VERSION ""

NS_ :

BS_:

BU_: VDCU_M CDCU VDR_TBOX ADCU VIU_B VIU_C VDCU_V EPB EBS FCS EPS_M EPS_S CMS_R CMS_B ECAS EGSM MTCU

BO_ 2566889511 NM_VDCU: 8 VDCU_M
 SG_ VDCU_SourceNodeID : 0|8@1+ (1,0) [0|255] "" Vector__XXX
 SG_ VDCU_ActiveWakeUpBit : 12|1@1+ (1,0) [0|1] "" Vector__XXX
 SG_ VDCU_RepeatMessageRequest : 8|1@1+ (1,0) [0|1] "" Vector__XXX
 SG_ VDCU_NMState_RMSfromBSM : 16|1@1+ (1,0) [0|1] "" Vector__XXX
 SG_ VDCU_NMState_RMSfromPBSM : 17|1@1+ (1,0) [0|1] "" Vector__XXX
 SG_ VDCU_NMState_RMSfromNOS : 18|1@1+ (1,0) [0|1] "" Vector__XXX
 SG_ VDCU_NMState_RMSfromRSS : 19|1@1+ (1,0) [0|1] "" Vector__XXX
 SG_ VDCU_NMState_NOSfromRMS : 20|1@1+ (1,0) [0|1] "" Vector__XXX
 SG_ VDCU_NMState_NOSfromRSS : 21|1@1+ (1,0) [0|1] "" Vector__XXX
 SG_ VDCU_WakeupSource : 24|8@1+ (1,0) [0|255] "" Vector__XXX
 SG_ VDCU_NMKpARson_NMPduReceived : 32|1@1+ (1,0) [0|1] "" Vector__XXX
 SG_ VDCU_NMKpARson_TimeOut : 33|1@1+ (1,0) [0|1] "" Vector__XXX
 SG_ VDCU_NMKpARson_Diag : 34|1@1+ (1,0) [0|1] "" Vector__XXX
 SG_ VDCU_NMKpARson_KL15 : 36|1@1+ (1,0) [0|1] "" Vector__XXX
 SG_ VDCU_NMKpARson_LINReq : 37|1@1+ (1,0) [0|1] "" Vector__XXX
 SG_ VDCU_NMKpARson_WinCtrl_L : 38|1@1+ (1,0) [0|1] "" Vector__XXX
 SG_ VDCU_NMKpARson_WinCtrl_R : 39|1@1+ (1,0) [0|1] "" Vector__XXX
 SG_ VDCU_NMKpARson_BrakePedalPressed : 40|1@1+ (1,0) [0|1] "" Vector__XXX
 SG_ VDCU_NMKpARson_LowBeamReq : 41|1@1+ (1,0) [0|1] "" Vector__XXX
 SG_ VDCU_NMKpARson_PosnLigjtReq : 42|1@1+ (1,0) [0|1] "" Vector__XXX
 SG_ VDCU_NMKpARson_DCChargeActive : 43|1@1+ (1,0) [0|1] "" Vector__XXX
 SG_ VDCU_NMKpARson_PowerOFFdelayMonitor : 44|1@1+ (1,0) [0|1] "" Vector__XXX
 SG_ VDCU_NMKpARson_ACChargeActive : 45|1@1+ (1,0) [0|1] "" Vector__XXX
 SG_ VDCU_NMKpARson_HVConnected : 46|1@1+ (1,0) [0|1] "" Vector__XXX
 SG_ VDCU_NMKpARson_ChargeWarmer : 47|1@1+ (1,0) [0|1] "" Vector__XXX
 SG_ VDCU_NMKpARson_Ready : 48|1@1+ (1,0) [0|1] "" Vector__XXX
 SG_ VDCU_NMKpARson_SmartCharge : 49|1@1+ (1,0) [0|1] "" Vector__XXX

BO_ 2566865177 TM_ACCtrl: 8 VDCU_M
 SG_ ACTempLevelDisp : 0|6@1+ (1,0) [0|63] "" CDCU,VDR_TBOX,ADCU
 SG_ ACPTCDisp : 6|2@1+ (1,0) [0|3] "" Vector__XXX
 SG_ ACTempLevelCtrl : 8|6@1+ (1,0) [0|63] "" VIU_B,ADCU
 SG_ ACModeMotorDisp : 16|3@1+ (1,0) [0|7] "" CDCU,VDR_TBOX,ADCU
 SG_ ACModeMotorCtrl : 19|3@1+ (1,0) [0|7] "" VIU_B,ADCU
 SG_ ACCycleMotorDisp : 22|2@1+ (1,0) [0|3] "" CDCU,VDR_TBOX,ADCU
 SG_ ACCycleMotorPosnCtrl : 24|2@1+ (1,0) [0|3] "" VIU_B,ADCU
 SG_ ACBlowerLevelDisp : 26|4@1+ (1,0) [0|15] "" CDCU,VDR_TBOX,ADCU
 SG_ ACBlowerLevelCtrl : 32|4@1+ (1,0) [0|15] "" VIU_B,ADCU
 SG_ ACFrontDefrostDisp : 36|2@1+ (1,0) [0|3] "" CDCU,VDR_TBOX,ADCU
 SG_ ACAcDisp : 38|2@1+ (1,0) [0|3] "" CDCU,VDR_TBOX,ADCU
 SG_ ACMaxDisp : 40|2@1+ (1,0) [0|3] "" CDCU,VDR_TBOX,ADCU
 SG_ ACAutoDisp : 42|2@1+ (1,0) [0|3] "" CDCU,VDR_TBOX,ADCU
 SG_ ACOffDisp : 44|2@1+ (1,0) [0|3] "" CDCU,VDR_TBOX,ADCU
 SG_ ACAirPurgeDisp : 46|2@1+ (1,0) [0|3] "" CDCU,VDR_TBOX,ADCU
 SG_ ACAirPurgeCtrl : 48|2@1+ (1,0) [0|3] "" VIU_B,ADCU
 SG_ ACLonizerDisp : 50|2@1+ (1,0) [0|3] "" CDCU,VDR_TBOX,ADCU
 SG_ ACLonizerCtrl : 52|2@1+ (1,0) [0|3] "" VIU_B,ADCU
 SG_ AC_TempZoneSyncSts : 54|2@1+ (1,0) [0|3] "" VIU_B,CDCU,VDR_TBOX,ADCU
 SG_ AC_HeatingMaxSts : 56|2@1+ (1,0) [0|3] "" VIU_B,CDCU,VDR_TBOX,ADCU
 SG_ ElecACTempLevelDisp : 58|5@1+ (1,0) [0|31] "" Vector__XXX

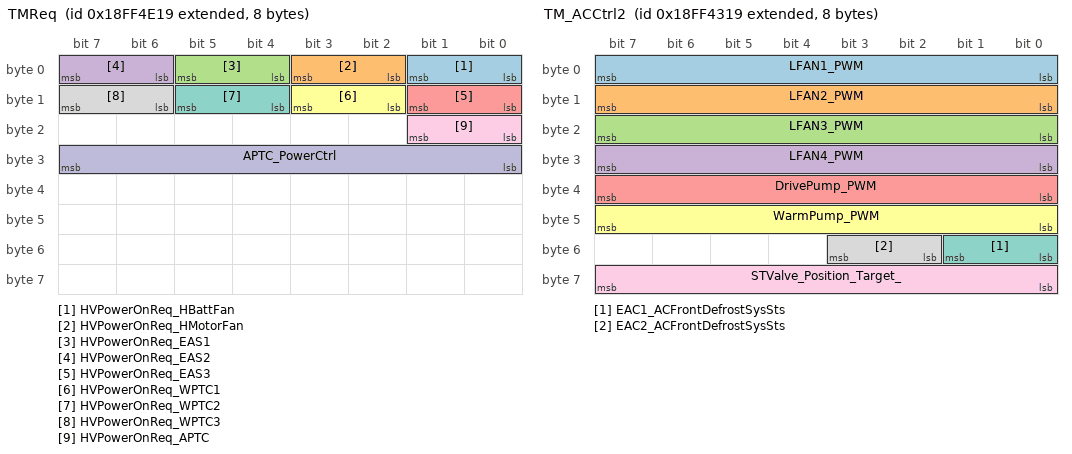
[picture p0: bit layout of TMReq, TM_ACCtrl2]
BO_ 2566868505 TMReq: 8 VDCU_M
 SG_ HVPowerOnReq_HBattFan : 0|2@1+ (1,0) [0|3] "" Vector__XXX
 SG_ HVPowerOnReq_HMotorFan : 2|2@1+ (1,0) [0|3] "" Vector__XXX
 SG_ HVPowerOnReq_EAS1 : 4|2@1+ (1,0) [0|3] "" Vector__XXX
 SG_ HVPowerOnReq_EAS2 : 6|2@1+ (1,0) [0|3] "" Vector__XXX
 SG_ HVPowerOnReq_EAS3 : 8|2@1+ (1,0) [0|3] "" Vector__XXX
 SG_ HVPowerOnReq_WPTC1 : 10|2@1+ (1,0) [0|3] "" Vector__XXX
 SG_ HVPowerOnReq_WPTC2 : 12|2@1+ (1,0) [0|3] "" Vector__XXX
 SG_ HVPowerOnReq_WPTC3 : 14|2@1+ (1,0) [0|3] "" Vector__XXX
 SG_ HVPowerOnReq_APTC : 16|2@1+ (1,0) [0|3] "" Vector__XXX
 SG_ APTC_PowerCtrl : 24|8@1+ (100,0) [0|4700] "W" VIU_B

BO_ 2566865433 TM_ACCtrl1: 8 VDCU_M
 SG_ ACTempLevelDispSlpr : 2|6@1+ (1,0) [0|63] "" CDCU
 SG_ ACTempLevelCtrl_Slpr : 10|6@1+ (1,0) [0|63] "" VIU_B
 SG_ ACBlowerLevelDisp_Slpr : 16|4@1+ (1,0) [0|15] "" CDCU
 SG_ ACBlowerLevelCtrl_Slpr : 20|4@1+ (1,0) [0|15] "" VIU_B
 SG_ ACTimingRunDisp_Slpr : 24|2@1+ (1,0) [0|3] "" CDCU
 SG_ ACOffDisp_Slpr : 26|2@1+ (1,0) [0|3] "" CDCU
 SG_ ESC_PTC_LowRelayCtrl : 28|2@1+ (1,0) [0|3] "" VIU_B
 SG_ FAN_LowRelayCtrl : 30|2@1+ (1,0) [0|3] "" VIU_C
 SG_ Blower_RelayCtrl : 32|2@1+ (1,0) [0|3] "" VIU_B
 SG_ Blower_RelayCtrl_Slpr : 34|2@1+ (1,0) [0|3] "" VIU_B
 SG_ BattPump_RelayCtrl : 36|2@1+ (1,0) [0|3] "" VIU_B
 SG_ WarmPump_RelayCtrl : 38|2@1+ (1,0) [0|3] "" VIU_B
 SG_ DrivePump_RelayCtrl : 40|2@1+ (1,0) [0|3] "" VIU_C
 SG_ SOVFront_Ctrl : 42|1@1+ (1,0) [0|1] "" VIU_B
 SG_ SOVRear_Ctrl : 43|1@1+ (1,0) [0|1] "" VIU_B
 SG_ Wasteheat_use_2way_SOV : 46|2@1+ (1,0) [0|3] "" VIU_C
 SG_ BattPump_PWM : 48|8@1+ (0.4,0) [0|100] "%" VIU_B,VIU_C
 SG_ Temp_Ambt_Accurate : 56|8@1+ (0.5,-40) [-40|87] "℃" Vector__XXX

BO_ 2566865689 TM_ACCtrl2: 8 VDCU_M
 SG_ LFAN1_PWM : 0|8@1+ (0.4,0) [0|100] "%" VIU_B,VIU_C
 SG_ LFAN2_PWM : 8|8@1+ (0.4,0) [0|100] "%" VIU_B,VIU_C
 SG_ LFAN3_PWM : 16|8@1+ (0.4,0) [0|100] "%" VIU_B,VIU_C
 SG_ LFAN4_PWM : 24|8@1+ (0.4,0) [0|100] "%" VIU_B,VIU_C
 SG_ DrivePump_PWM : 32|8@1+ (0.4,0) [0|100] "%" VIU_B,VIU_C
 SG_ WarmPump_PWM : 40|8@1+ (0.4,0) [0|100] "%" VIU_C
 SG_ EAC1_ACFrontDefrostSysSts : 48|2@1+ (1,0) [0|3] "" CDCU
 SG_ EAC2_ACFrontDefrostSysSts : 50|2@1+ (1,0) [0|3] "" CDCU
 SG_ STValve_Position_Target_ : 56|8@1+ (0.01953,0) [0|5] "v" VIU_C

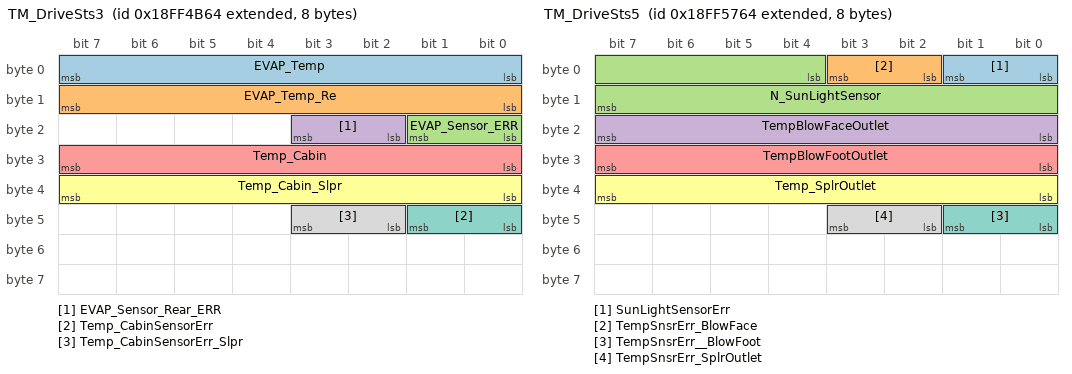
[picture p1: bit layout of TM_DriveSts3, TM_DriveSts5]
BO_ 2566867812 TM_DriveSts3: 8 VIU_B
 SG_ EVAP_Temp : 0|8@1+ (0.5,-48) [-48|79] "℃" VDCU_M
 SG_ EVAP_Temp_Re : 8|8@1+ (0.5,-48) [-48|79] "℃" VDCU_M
 SG_ EVAP_Sensor_ERR : 16|2@1+ (1,0) [0|3] "" VDCU_M
 SG_ EVAP_Sensor_Rear_ERR : 18|2@1+ (1,0) [0|3] "" VDCU_M
 SG_ Temp_Cabin : 24|8@1+ (0.5,-40) [-40|87] "℃" VDCU_M
 SG_ Temp_Cabin_Slpr : 32|8@1+ (0.5,-40) [-40|87] "℃" VDCU_M
 SG_ Temp_CabinSensorErr : 40|2@1+ (1,0) [0|3] "" VDCU_M
 SG_ Temp_CabinSensorErr_Slpr : 42|2@1+ (1,0) [0|3] "" VDCU_M

BO_ 2566868068 TM_DriveSts4: 8 VIU_B
 SG_ ESC_PTC_LowRelaySts : 0|1@1+ (1,0) [0|1] "" VDCU_M
 SG_ FAN_LowRelaySts : 1|1@1+ (1,0) [0|1] "" VDCU_M
 SG_ Blower_RelaySts : 2|1@1+ (1,0) [0|1] "" VDCU_M
 SG_ BlowerRelaySts_Slpr : 3|1@1+ (1,0) [0|1] "" VDCU_M
 SG_ VIUB_BattPump_RelaySts : 4|1@1+ (1,0) [0|1] "" VDCU_M
 SG_ VIUB_WarmPump_RelaySts : 5|1@1+ (1,0) [0|1] "" VDCU_M
 SG_ VIUB_DrivePump_RelaySts : 6|1@1+ (1,0) [0|1] "" VDCU_M
 SG_ ESC_PTC_LowRelayErr : 7|1@1+ (1,0) [0|1] "" VDCU_M
 SG_ FAN_LowRelayErr : 8|1@1+ (1,0) [0|1] "" VDCU_M
 SG_ Blower_RelayErr : 9|1@1+ (1,0) [0|1] "" VDCU_M
 SG_ Blower_RelayErr_Slpr : 10|1@1+ (1,0) [0|1] "" VDCU_M
 SG_ VIUB_BattPump_RelayErr : 11|1@1+ (1,0) [0|1] "" VDCU_M
 SG_ VIUB_WarmPump_RelayErr : 12|1@1+ (1,0) [0|1] "" VDCU_M
 SG_ VIUB_DrivePump_RelayErr : 13|1@1+ (1,0) [0|1] "" VDCU_M
 SG_ ACModeMotorErr : 24|3@1+ (1,0) [0|3] "" VDCU_M
 SG_ ACTempMixMotorErr : 27|3@1+ (1,0) [0|3] "" VDCU_M
 SG_ ACBlowerMotorErr : 32|3@1+ (1,0) [0|3] "" VDCU_M
 SG_ ACCycleMotorErr : 35|3@1+ (1,0) [0|3] "" VDCU_M
 SG_ ACTempMixMotorErr_Splr : 40|3@1+ (1,0) [0|3] "" VDCU_M
 SG_ ACBlowerMotorErr_Splr : 43|3@1+ (1,0) [0|3] "V" VDCU_M
 SG_ ACLonizerErr : 46|2@1+ (1,0) [0|3] "" VDCU_M

BO_ 2566870884 TM_DriveSts5: 8 VIU_B
 SG_ SunLightSensorErr : 0|2@1+ (1,0) [0|3] "" VDCU_M
 SG_ TempSnsrErr_BlowFace : 2|2@1+ (1,0) [0|3] "" VDCU_M
 SG_ N_SunLightSensor : 4|12@1+ (1,0) [0|2047] "W/m2" VDCU_M
 SG_ TempBlowFaceOutlet : 16|8@1+ (0.5,-40) [-40|87] "℃" VDCU_M
 SG_ TempBlowFootOutlet : 24|8@1+ (0.5,-40) [-40|87] "℃" VDCU_M
 SG_ Temp_SplrOutlet : 32|8@1+ (0.5,-40) [-40|87] "℃" VDCU_M
 SG_ TempSnsrErr__BlowFoot : 40|2@1+ (1,0) [0|3] "" VDCU_M
 SG_ TempSnsrErr_SplrOutlet : 42|2@1+ (1,0) [0|3] "" VDCU_M

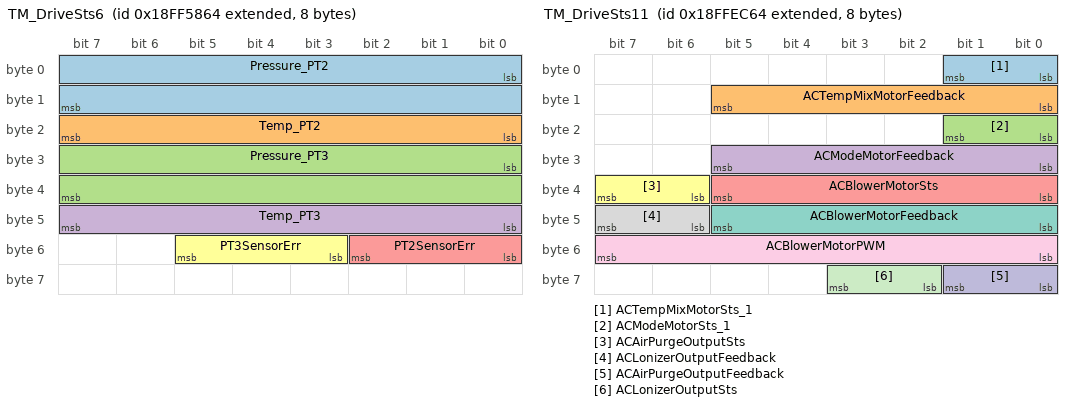
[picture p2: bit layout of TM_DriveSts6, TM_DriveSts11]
BO_ 2566871140 TM_DriveSts6: 8 VIU_B
 SG_ Pressure_PT2 : 0|16@1+ (1,0) [0|4000] "kpa" VDCU_M
 SG_ Temp_PT2 : 16|8@1+ (1,-48) [-48|206] "℃" VDCU_M
 SG_ Pressure_PT3 : 24|16@1+ (1,0) [0|4000] "kpa" VDCU_M
 SG_ Temp_PT3 : 40|8@1+ (1,-48) [-48|206] "℃" VDCU_M
 SG_ PT2SensorErr : 48|3@1+ (1,0) [0|7] "" VDCU_M
 SG_ PT3SensorErr : 51|3@1+ (1,0) [0|7] "" VDCU_M

BO_ 2566909028 TM_DriveSts11: 8 VIU_B
 SG_ ACTempMixMotorSts_1 : 0|2@1+ (1,0) [0|3] "" VDCU_M
 SG_ ACTempMixMotorFeedback : 8|6@1+ (0.1,0) [0|5] "V" VDCU_M
 SG_ ACModeMotorSts_1 : 16|2@1+ (1,0) [0|3] "" VDCU_M
 SG_ ACModeMotorFeedback : 24|6@1+ (0.1,0) [0|5] "V" VDCU_M
 SG_ ACBlowerMotorSts : 32|6@1+ (0.1,0) [0|5] "V" VDCU_M
 SG_ ACAirPurgeOutputSts : 38|2@1+ (1,0) [0|3] "" VDCU_M
 SG_ ACBlowerMotorFeedback : 40|6@1+ (0.1,0) [0|5] "V" VDCU_M
 SG_ ACLonizerOutputFeedback : 46|2@1+ (1,0) [0|3] "" VDCU_M
 SG_ ACBlowerMotorPWM : 48|8@1+ (0.4,0) [0|100] "%" VDCU_M
 SG_ ACAirPurgeOutputFeedback : 56|2@1+ (1,0) [0|3] "" VDCU_M
 SG_ ACLonizerOutputSts : 58|2@1+ (1,0) [0|3] "" VDCU_M

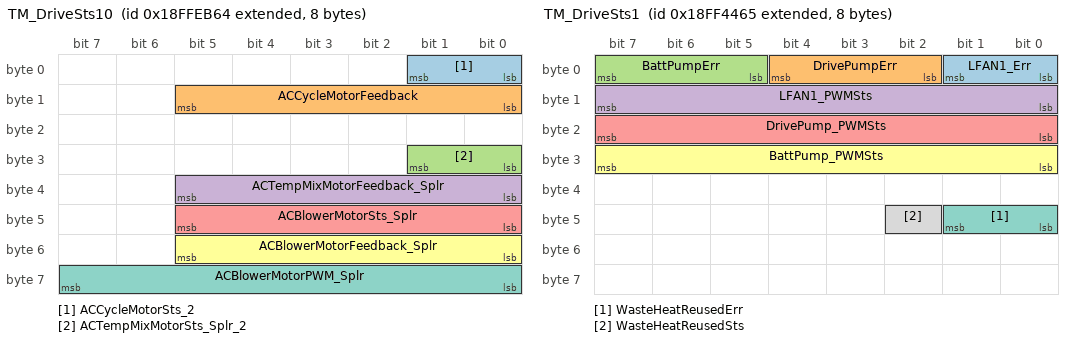
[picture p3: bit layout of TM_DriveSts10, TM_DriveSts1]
BO_ 2566908772 TM_DriveSts10: 8 VIU_B
 SG_ ACCycleMotorSts_2 : 0|2@1+ (1,0) [0|3] "" VDCU_M
 SG_ ACCycleMotorFeedback : 8|6@1+ (0.1,0) [0|5] "V" VDCU_M
 SG_ ACTempMixMotorSts_Splr_2 : 24|2@1+ (1,0) [0|3] "" VDCU_M
 SG_ ACTempMixMotorFeedback_Splr : 32|6@1+ (0.1,0) [0|5] "V" VDCU_M
 SG_ ACBlowerMotorSts_Splr : 40|6@1+ (0.1,0) [0|5] "V" VDCU_M
 SG_ ACBlowerMotorFeedback_Splr : 48|6@1+ (0.1,0) [0|5] "V" VDCU_M
 SG_ ACBlowerMotorPWM_Splr : 56|8@1+ (0.4,0) [0|100] "%" VDCU_M

BO_ 2566866021 TM_DriveSts1: 8 VIU_C
 SG_ LFAN1_Err : 0|2@1+ (1,0) [0|3] "" VDCU_M
 SG_ DrivePumpErr : 2|3@1+ (1,0) [0|7] "" VDCU_M
 SG_ BattPumpErr : 5|3@1+ (1,0) [0|7] "" VDCU_M
 SG_ LFAN1_PWMSts : 8|8@1+ (0.4,0) [0|100] "%" VDCU_M
 SG_ DrivePump_PWMSts : 16|8@1+ (0.4,0) [0|100] "%" VDCU_M
 SG_ BattPump_PWMSts : 24|8@1+ (0.4,0) [0|100] "%" VDCU_M
 SG_ WasteHeatReusedErr : 40|2@1+ (1,0) [0|3] "" VDCU_M
 SG_ WasteHeatReusedSts : 42|1@1+ (1,0) [0|1] "" VDCU_M

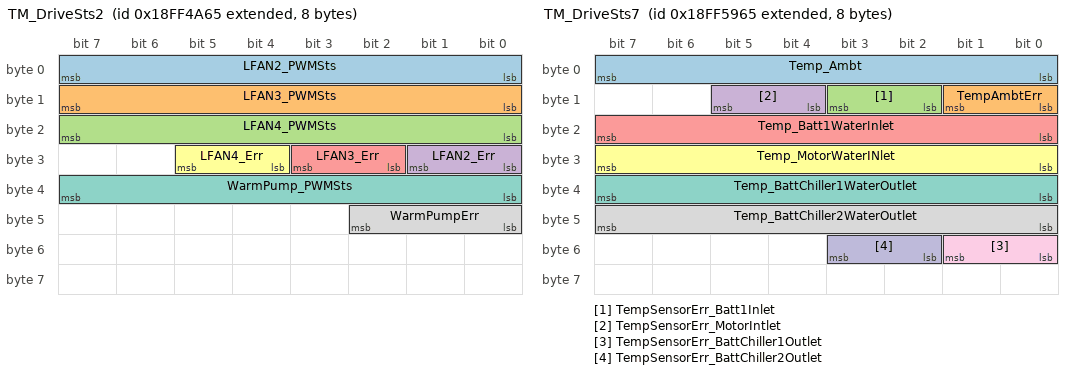
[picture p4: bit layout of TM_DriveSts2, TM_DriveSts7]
BO_ 2566867557 TM_DriveSts2: 8 VIU_C
 SG_ LFAN2_PWMSts : 0|8@1+ (0.4,0) [0|100] "%" VDCU_M
 SG_ LFAN3_PWMSts : 8|8@1+ (0.4,0) [0|100] "%" VDCU_M
 SG_ LFAN4_PWMSts : 16|8@1+ (0.4,0) [0|100] "%" VDCU_M
 SG_ LFAN2_Err : 24|2@1+ (1,0) [0|3] "" VDCU_M
 SG_ LFAN3_Err : 26|2@1+ (1,0) [0|3] "" VDCU_M
 SG_ LFAN4_Err : 28|2@1+ (1,0) [0|3] "" VDCU_M
 SG_ WarmPump_PWMSts : 32|8@1+ (0.4,0) [0|100] "%" VDCU_M
 SG_ WarmPumpErr : 40|3@1+ (1,0) [0|7] "" VDCU_M

BO_ 2566871397 TM_DriveSts7: 8 VIU_C
 SG_ Temp_Ambt : 0|8@1+ (0.5,-40) [-40|87] "℃" VDCU_M
 SG_ TempAmbtErr : 8|2@1+ (1,0) [0|3] "" VDCU_M
 SG_ TempSensorErr_Batt1Inlet : 10|2@1+ (1,0) [0|3] "" VDCU_M
 SG_ TempSensorErr_MotorIntlet : 12|2@1+ (1,0) [0|3] "" VDCU_M
 SG_ Temp_Batt1WaterInlet : 16|8@1+ (1,-40) [-40|215] "℃" VDCU_M
 SG_ Temp_MotorWaterINlet : 24|8@1+ (1,-40) [-40|215] "℃" VDCU_M
 SG_ Temp_BattChiller1WaterOutlet : 32|8@1+ (1,-40) [-40|215] "℃" VDCU_M
 SG_ Temp_BattChiller2WaterOutlet : 40|8@1+ (1,-40) [-40|215] "℃" VDCU_M
 SG_ TempSensorErr_BattChiller1Outlet : 48|2@1+ (1,0) [0|3] "" VDCU_M
 SG_ TempSensorErr_BattChiller2Outlet : 50|2@1+ (1,0) [0|3] "" VDCU_M

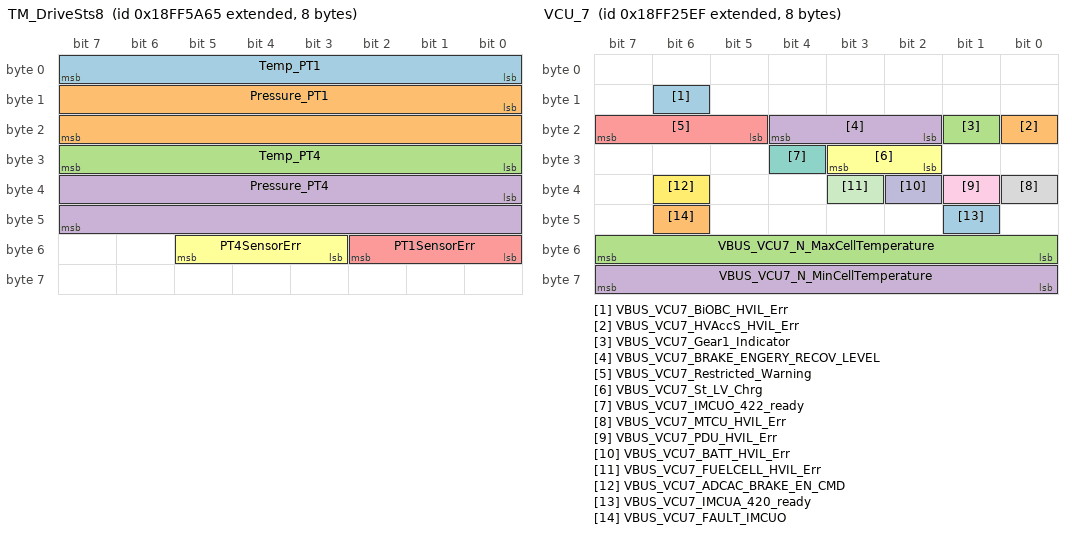
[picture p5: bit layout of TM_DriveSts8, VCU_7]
BO_ 2566871653 TM_DriveSts8: 8 VIU_C
 SG_ Temp_PT1 : 0|8@1+ (1,-48) [-48|206] "℃" VDCU_M
 SG_ Pressure_PT1 : 8|16@1+ (1,0) [0|4000] "kpa" VDCU_M
 SG_ Temp_PT4 : 24|8@1+ (1,-48) [-48|206] "℃" VDCU_M
 SG_ Pressure_PT4 : 32|16@1+ (1,0) [0|4000] "kpa" VDCU_M
 SG_ PT1SensorErr : 48|3@1+ (1,0) [0|7] "" VDCU_M
 SG_ PT4SensorErr : 51|3@1+ (1,0) [0|7] "" VDCU_M

BO_ 2566871909 TM_DriveSts9: 8 VIU_C
 SG_ MidPressure1Sts : 0|1@1+ (1,0) [0|1] "" VDCU_M
 SG_ HighPressure1Sts : 1|2@1+ (1,0) [0|3] "" VDCU_M
 SG_ MidPressure2Sts : 3|1@1+ (1,0) [0|1] "" VDCU_M
 SG_ HighPressure2Sts : 5|2@1+ (1,0) [0|3] "" VDCU_M
 SG_ MidPressure3Sts : 7|1@1+ (1,0) [0|1] "" VDCU_M
 SG_ HighPressure3Sts : 8|2@1+ (1,0) [0|3] "" VDCU_M
 SG_ HighPressure1Err : 10|1@1+ (1,0) [0|1] "" VDCU_M
 SG_ HighPressure2Err : 11|1@1+ (1,0) [0|1] "" VDCU_M
 SG_ HighPressure3Err : 12|1@1+ (1,0) [0|1] "" VDCU_M
 SG_ LevelSwt1Cmd : 13|1@1+ (1,0) [0|1] "" VDCU_M
 SG_ LevelSwt2Cmd : 14|1@1+ (1,0) [0|1] "" VDCU_M
 SG_ LevelSwt3Cmd : 15|1@1+ (1,0) [0|1] "" VDCU_M
 SG_ LevelSwt4Cmd : 16|1@1+ (1,0) [0|1] "" VDCU_M
 SG_ LevelSwt1Err : 17|1@1+ (1,0) [0|1] "" VDCU_M
 SG_ LevelSwt2Err : 18|1@1+ (1,0) [0|1] "" VDCU_M
 SG_ LevelSwt3Err : 19|1@1+ (1,0) [0|1] "" VDCU_M
 SG_ LevelSwt4Err : 20|1@1+ (1,0) [0|1] "" VDCU_M
 SG_ BattPump_Err : 21|2@1+ (1,0) [0|3] "" VDCU_M
 SG_ MotorPump_Err : 24|2@1+ (1,0) [0|3] "" VDCU_M
 SG_ xxxPump_Err : 26|2@1+ (1,0) [0|3] "" VDCU_M
 SG_ VIUC_BattPump_RelaySts : 28|1@1+ (1,0) [0|1] "" VDCU_M
 SG_ VIUC_WarmPump_RelaySts : 30|1@1+ (1,0) [0|1] "" VDCU_M
 SG_ VIUC_DrivePump_RelaySts : 32|1@1+ (1,0) [0|1] "" VDCU_M
 SG_ VIUC_BattPump_RelayErr : 34|1@1+ (1,0) [0|1] "" VDCU_M
 SG_ VIUC_WarmPump_RelayErr : 35|1@1+ (1,0) [0|1] "" VDCU_M
 SG_ VIUC_DrivePump_RelayErr : 36|1@1+ (1,0) [0|1] "" VDCU_M

BO_ 2566907943 VDCU_Response: 8 VDCU_V
 SG_ ValidDKM : 40|1@1+ (1,0) [0|1] "" VDCU_M

BO_ 2566858223 VCU_7: 8 VDCU_M
 SG_ VBUS_VCU7_BiOBC_HVIL_Err : 14|1@1+ (1,0) [0|1] "" CDCU,VDR_TBOX,ADCU
 SG_ VBUS_VCU7_HVAccS_HVIL_Err : 16|1@1+ (1,0) [0|1] "" ADCU
 SG_ VBUS_VCU7_Gear1_Indicator : 17|1@1+ (1,0) [0|1] "" CDCU,ADCU
 SG_ VBUS_VCU7_BRAKE_ENGERY_RECOV_LEVEL : 18|3@1+ (1,0) [0|7] "" CDCU,VDR_TBOX,ADCU
 SG_ VBUS_VCU7_Restricted_Warning : 21|3@1+ (1,0) [0|7] "" CDCU,VDR_TBOX,ADCU
 SG_ VBUS_VCU7_St_LV_Chrg : 26|2@1+ (1,0) [0|3] "" CDCU,VDR_TBOX,ADCU
 SG_ VBUS_VCU7_IMCUO_422_ready : 28|1@1+ (1,0) [0|1] "" CDCU,VDR_TBOX,ADCU
 SG_ VBUS_VCU7_MTCU_HVIL_Err : 32|1@1+ (1,0) [0|1] "" CDCU,VDR_TBOX,ADCU
 SG_ VBUS_VCU7_PDU_HVIL_Err : 33|1@1+ (1,0) [0|1] "" CDCU,VDR_TBOX,ADCU
 SG_ VBUS_VCU7_BATT_HVIL_Err : 34|1@1+ (1,0) [0|1] "" CDCU,VDR_TBOX,ADCU
 SG_ VBUS_VCU7_FUELCELL_HVIL_Err : 35|1@1+ (1,0) [0|1] "" CDCU,VDR_TBOX,ADCU
 SG_ VBUS_VCU7_ADCAC_BRAKE_EN_CMD : 38|1@1+ (1,0) [0|1] "" CDCU,VDR_TBOX,ADCU
 SG_ VBUS_VCU7_IMCUA_420_ready : 41|1@1+ (1,0) [0|1] "" VIU_C,CDCU,VDR_TBOX,ADCU
 SG_ VBUS_VCU7_FAULT_IMCUO : 46|1@1+ (1,0) [0|1] "" CDCU,VDR_TBOX,ADCU
 SG_ VBUS_VCU7_N_MaxCellTemperature : 48|8@1+ (1,-40) [-40|125] "℃" CDCU,VDR_TBOX,ADCU
 SG_ VBUS_VCU7_N_MinCellTemperature : 56|8@1+ (1,-40) [-40|125] "℃" CDCU,VDR_TBOX,ADCU

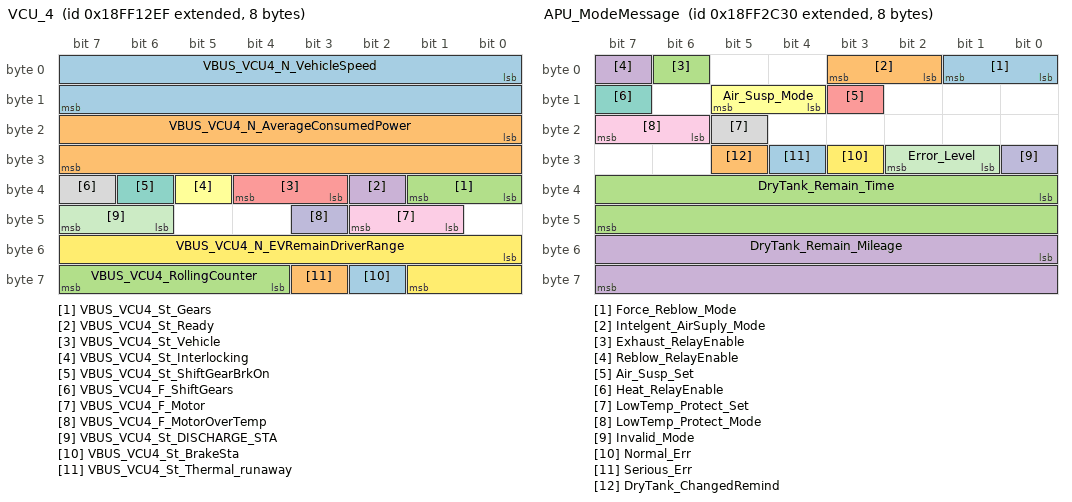
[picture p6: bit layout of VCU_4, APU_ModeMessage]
BO_ 2566853359 VCU_4: 8 VDCU_M
 SG_ VBUS_VCU4_N_VehicleSpeed : 0|16@1+ (0.0039,0) [0|250.996] "km/h" CDCU,VDR_TBOX,ADCU,EPB,EBS
 SG_ VBUS_VCU4_N_AverageConsumedPower : 16|16@1+ (0.1,0) [0|6553.5] "kW·h/100km" CDCU,VDR_TBOX,ADCU
 SG_ VBUS_VCU4_St_Gears : 32|2@1+ (1,0) [0|3] "" CDCU,VDR_TBOX,ADCU,EPB,FCS,EPS_M,EPS_S
 SG_ VBUS_VCU4_St_Ready : 34|1@1+ (1,0) [0|1] "" CDCU,VDR_TBOX,CMS_R,CMS_B,ADCU,FCS
 SG_ VBUS_VCU4_St_Vehicle : 35|2@1+ (1,0) [0|3] "" CDCU,VDR_TBOX,ADCU
 SG_ VBUS_VCU4_St_Interlocking : 37|1@1+ (1,0) [0|1] "" CDCU,VDR_TBOX,ADCU
 SG_ VBUS_VCU4_St_ShiftGearBrkOn : 38|1@1+ (1,0) [0|1] "" CDCU,VDR_TBOX,ADCU
 SG_ VBUS_VCU4_F_ShiftGears : 39|1@1+ (1,0) [0|1] "" CDCU,ADCU
 SG_ VBUS_VCU4_F_Motor : 41|2@1+ (1,0) [0|3] "" CDCU,VDR_TBOX,ADCU
 SG_ VBUS_VCU4_F_MotorOverTemp : 43|1@1+ (1,0) [0|1] "" CDCU,VDR_TBOX,ADCU
 SG_ VBUS_VCU4_St_DISCHARGE_STA : 46|2@1+ (1,0) [0|3] "" CDCU,VDR_TBOX,ADCU
 SG_ VBUS_VCU4_N_EVRemainDriverRange : 48|10@1+ (1,0) [0|1023] "km" CDCU,VDR_TBOX,ADCU
 SG_ VBUS_VCU4_St_BrakeSta : 58|1@1+ (1,0) [0|1] "" CDCU,VDR_TBOX,ADCU
 SG_ VBUS_VCU4_St_Thermal_runaway : 59|1@1+ (1,0) [0|1] "" CDCU,VDR_TBOX,ADCU
 SG_ VBUS_VCU4_RollingCounter : 60|4@1+ (1,0) [0|15] "" CDCU,VDR_TBOX,ADCU

BO_ 2566873957 BodyLiSts: 8 VIU_C
 SG_ TurnLightSts_LR : 0|1@1+ (1,0) [0|1] "" VDCU_M
 SG_ TurnLightFltMode_LR : 1|2@1+ (1,0) [0|3] "" VDCU_M
 SG_ TurnLightSts_RR : 3|1@1+ (1,0) [0|1] "" VDCU_M
 SG_ TurnLightFltMode_RR : 4|2@1+ (1,0) [0|3] "" VDCU_M
 SG_ MainReverseLampSts : 6|1@1+ (1,0) [0|1] "" VDCU_M
 SG_ TrailerReverseLampSts : 7|1@1+ (1,0) [0|1] "" VDCU_M
 SG_ MainReverseLampFltMode : 8|2@1+ (1,0) [0|3] "" VDCU_M
 SG_ TrailerReverseLampFltMode : 10|2@1+ (1,0) [0|3] "" VDCU_M
 SG_ TrailerSts : 12|1@1+ (1,0) [0|1] "" VDCU_M
 SG_ RearPositionLightSts_L : 22|1@1+ (1,0) [0|1] "" VDCU_M
 SG_ RearPositionLighFltMode_L : 24|2@1+ (1,0) [0|3] "" VDCU_M
 SG_ RearPositionLightSts_R : 26|1@1+ (1,0) [0|1] "" VDCU_M
 SG_ RearPositionLighFltMode_R : 27|2@1+ (1,0) [0|3] "" VDCU_M
 SG_ RearHeadlightSts : 32|1@1+ (1,0) [0|1] "" VDCU_M
 SG_ RearHeadlightFltMode : 33|2@1+ (1,0) [0|3] "" VDCU_M
 SG_ TrailerABSAlarm : 35|2@1+ (1,0) [0|3] "" VDCU_M
 SG_ TurnLightSts_TL : 37|1@1+ (1,0) [0|1] "" VDCU_M
 SG_ TurnLightFltMode_TL : 38|2@1+ (1,0) [0|3] "" VDCU_M
 SG_ TurnLightSts_TR : 40|1@1+ (1,0) [0|1] "" VDCU_M
 SG_ TurnLightFltMode_TR : 41|2@1+ (1,0) [0|3] "" VDCU_M
 SG_ RearPositionLightSts_TL : 43|1@1+ (1,0) [0|1] "" VDCU_M
 SG_ RearPositionLightSts_TR : 44|1@1+ (1,0) [0|1] "" VDCU_M

BO_ 2566859824 APU_ModeMessage: 8 VIU_C
 SG_ Force_Reblow_Mode : 0|2@1+ (1,0) [0|3] "" VDCU_M
 SG_ Intelgent_AirSuply_Mode : 2|2@1+ (1,0) [0|3] "" VDCU_M
 SG_ Exhaust_RelayEnable : 6|1@1+ (1,0) [0|1] "" VDCU_M
 SG_ Reblow_RelayEnable : 7|1@1+ (1,0) [0|1] "" VDCU_M
 SG_ Air_Susp_Set : 11|1@1+ (1,0) [0|1] "" VDCU_M
 SG_ Air_Susp_Mode : 12|2@1+ (1,0) [0|3] "" VDCU_M
 SG_ Heat_RelayEnable : 15|1@1+ (1,0) [0|1] "" VDCU_M
 SG_ LowTemp_Protect_Set : 21|1@1+ (1,0) [0|1] "" VDCU_M
 SG_ LowTemp_Protect_Mode : 22|2@1+ (1,0) [0|3] "" VDCU_M
 SG_ Invalid_Mode : 24|1@1+ (1,0) [0|1] "" VDCU_M
 SG_ Error_Level : 25|2@1+ (1,0) [0|3] "" VDCU_M
 SG_ Normal_Err : 27|1@1+ (1,0) [0|1] "" VDCU_M
 SG_ Serious_Err : 28|1@1+ (1,0) [0|1] "" VDCU_M
 SG_ DryTank_ChangedRemind : 29|1@1+ (1,0) [0|1] "" VDCU_M
 SG_ DryTank_Remain_Time : 32|16@1+ (1,0) [0|65535] "天" VDCU_M
 SG_ DryTank_Remain_Mileage : 48|16@1+ (3,0) [0|196605] "km" VDCU_M

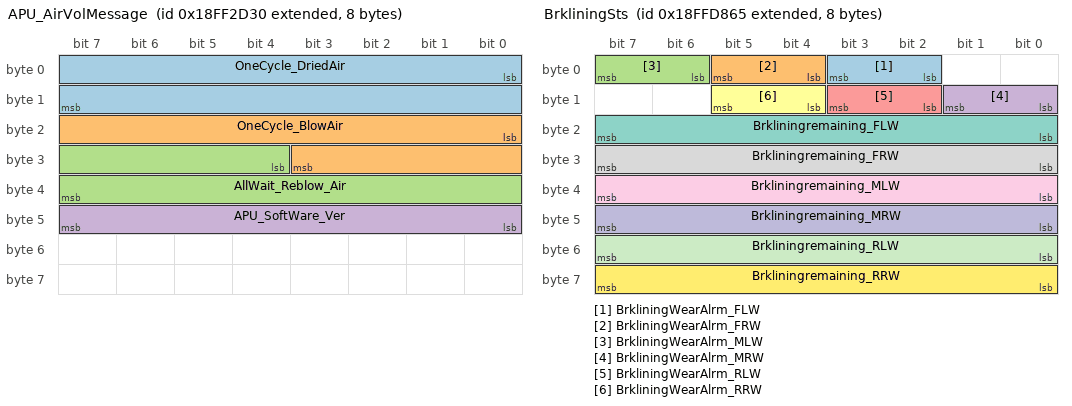
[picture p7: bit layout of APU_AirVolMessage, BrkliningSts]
BO_ 2566860080 APU_AirVolMessage: 8 VIU_C
 SG_ OneCycle_DriedAir : 0|16@1+ (0.1,0) [0|6553.5] "L" VDCU_M
 SG_ OneCycle_BlowAir : 16|12@1+ (0.1,0) [0|409.6] "L" VDCU_M
 SG_ AllWait_Reblow_Air : 28|12@1+ (0.1,0) [0|409.6] "L" VDCU_M
 SG_ APU_SoftWare_Ver : 40|8@1+ (0.1,0) [0|25.5] "" VDCU_M

BO_ 2566893413 SafetyFlt_VIUC: 8 VIU_C
 SG_ VIUC_ACFrontDefrostSysSts : 8|2@1+ (1,0) [0|3] "" VDCU_M

BO_ 2566860336 APU_AirVolMessage2: 8 VIU_C
 SG_ AirComp_WorkingLoad_OneStart : 8|8@1+ (1,0) [0|255] "" VDCU_M
 SG_ AirComp_WrkLoad_OneCycle : 16|8@1+ (1,0) [0|255] "" VDCU_M
 SG_ AllAir_Dried : 32|32@1+ (0.1,0) [0|4.294967296E8] "L" VDCU_M

BO_ 2566903909 BrkliningSts: 8 VIU_C
 SG_ BrkliningWearAlrm_FLW : 2|2@1+ (1,0) [0|3] "" VDCU_M
 SG_ BrkliningWearAlrm_FRW : 4|2@1+ (1,0) [0|3] "" VDCU_M
 SG_ BrkliningWearAlrm_MLW : 6|2@1+ (1,0) [0|3] "" VDCU_M
 SG_ BrkliningWearAlrm_MRW : 8|2@1+ (1,0) [0|3] "" VDCU_M
 SG_ BrkliningWearAlrm_RLW : 10|2@1+ (1,0) [0|3] "" VDCU_M
 SG_ BrkliningWearAlrm_RRW : 12|2@1+ (1,0) [0|3] "" VDCU_M
 SG_ Brkliningremaining_FLW : 16|8@1+ (1,0) [0|100] "%" VDCU_M
 SG_ Brkliningremaining_FRW : 24|8@1+ (1,0) [0|100] "%" VDCU_M
 SG_ Brkliningremaining_MLW : 32|8@1+ (1,0) [0|100] "%" VDCU_M
 SG_ Brkliningremaining_MRW : 40|8@1+ (1,0) [0|100] "%" VDCU_M
 SG_ Brkliningremaining_RLW : 48|8@1+ (1,0) [0|100] "%" VDCU_M
 SG_ Brkliningremaining_RRW : 56|8@1+ (1,0) [0|100] "%" VDCU_M

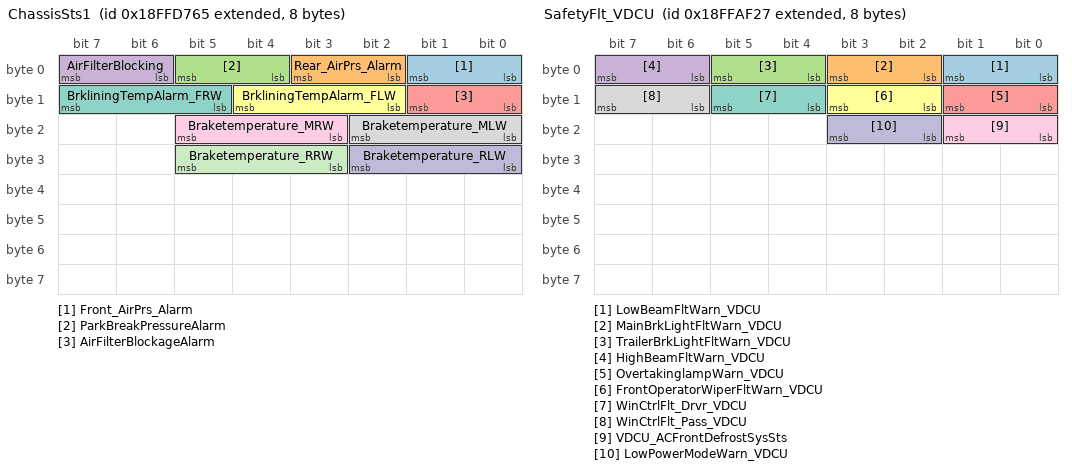
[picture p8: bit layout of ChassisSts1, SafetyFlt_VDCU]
BO_ 2566903653 ChassisSts1: 8 VIU_C
 SG_ Front_AirPrs_Alarm : 0|2@1+ (1,0) [0|3] "" VDCU_M
 SG_ Rear_AirPrs_Alarm : 2|2@1+ (1,0) [0|3] "" VDCU_M
 SG_ ParkBreakPressureAlarm : 4|2@1+ (1,0) [0|3] "" VDCU_M
 SG_ AirFilterBlocking : 6|2@1+ (1,0) [0|3] "" VDCU_M
 SG_ AirFilterBlockageAlarm : 8|2@1+ (1,0) [0|3] "" VDCU_M
 SG_ BrkliningTempAlarm_FLW : 10|3@1+ (1,0) [0|7] "" VDCU_M
 SG_ BrkliningTempAlarm_FRW : 13|3@1+ (1,0) [0|7] "" VDCU_M
 SG_ Braketemperature_MLW : 16|3@1+ (1,0) [0|7] "" VDCU_M
 SG_ Braketemperature_MRW : 19|3@1+ (1,0) [0|7] "" VDCU_M
 SG_ Braketemperature_RLW : 24|3@1+ (1,0) [0|7] "" VDCU_M
 SG_ Braketemperature_RRW : 27|3@1+ (1,0) [0|7] "" VDCU_M

BO_ 2566893351 SafetyFlt_VDCU: 8 VDCU_M
 SG_ LowBeamFltWarn_VDCU : 0|2@1+ (1,0) [0|3] "" VIU_B,CDCU
 SG_ MainBrkLightFltWarn_VDCU : 2|2@1+ (1,0) [0|3] "" VIU_B,VIU_C,CDCU
 SG_ TrailerBrkLightFltWarn_VDCU : 4|2@1+ (1,0) [0|3] "" VIU_B,VIU_C,CDCU
 SG_ HighBeamFltWarn_VDCU : 6|2@1+ (1,0) [0|3] "" VIU_B,CDCU
 SG_ OvertakinglampWarn_VDCU : 8|2@1+ (1,0) [0|3] "" VIU_B,CDCU
 SG_ FrontOperatorWiperFltWarn_VDCU : 10|2@1+ (1,0) [0|3] "" VIU_B,CDCU
 SG_ WinCtrlFlt_Drvr_VDCU : 12|2@1+ (1,0) [0|3] "" VIU_B,CDCU
 SG_ WinCtrlFlt_Pass_VDCU : 14|2@1+ (1,0) [0|3] "" VIU_B,CDCU
 SG_ VDCU_ACFrontDefrostSysSts : 16|2@1+ (1,0) [0|3] "" CDCU
 SG_ LowPowerModeWarn_VDCU : 18|2@1+ (1,0) [0|3] "" CDCU

BO_ 2365522727 EncryptData_VDCU: 20 VDCU_M
 SG_ CertificationSts_VDCU : 0|4@1+ (1,0) [0|127] "" VIU_B
 SG_ RandomData1_VDCU : 8|8@1+ (1,0) [0|255] "" VIU_B
 SG_ RandomData2_VDCU : 16|8@1+ (1,0) [0|255] "" VIU_B
 SG_ RandomData3_VDCU : 24|8@1+ (1,0) [0|255] "" VIU_B
 SG_ RandomData4_VDCU : 32|8@1+ (1,0) [0|255] "" VIU_B
 SG_ RandomData5_VDCU : 40|8@1+ (1,0) [0|255] "" VIU_B
 SG_ RandomData6_VDCU : 48|8@1+ (1,0) [0|255] "" VIU_B
 SG_ RandomData7_VDCU : 56|8@1+ (1,0) [0|255] "" VIU_B
 SG_ RandomData8_VDCU : 64|8@1+ (1,0) [0|255] "" VIU_B
 SG_ RandomData9_VDCU : 72|8@1+ (1,0) [0|255] "" VIU_B
 SG_ RandomData10_VDCU : 80|8@1+ (1,0) [0|255] "" VIU_B
 SG_ RandomData11_VDCU : 88|8@1+ (1,0) [0|255] "" VIU_B
 SG_ RandomData12_VDCU : 96|8@1+ (1,0) [0|255] "" VIU_B
 SG_ RandomData13_VDCU : 104|8@1+ (1,0) [0|255] "" VIU_B
 SG_ RandomData14_VDCU : 112|8@1+ (1,0) [0|255] "" VIU_B
 SG_ RandomData15_VDCU : 120|8@1+ (1,0) [0|255] "" VIU_B
 SG_ RandomData16_VDCU : 128|8@1+ (1,0) [0|255] "" VIU_B

BO_ 2566861351 LiCtrl: 8 VDCU_M
 SG_ LeftTurnLightReq : 0|4@1+ (1,0) [0|15] "" VIU_B,VIU_C,CDCU,VDR_TBOX,ADCU
 SG_ RightTurnLightReq : 4|4@1+ (1,0) [0|15] "" VIU_B,VIU_C,CDCU,VDR_TBOX,ADCU
 SG_ HzrdLightReq : 8|1@1+ (1,0) [0|1] "" VIU_B,VIU_C,CDCU,VDR_TBOX,ADCU,FCS
 SG_ LowBeamReq : 9|1@1+ (1,0) [0|1] "" VIU_B,CDCU,VDR_TBOX,ADCU
 SG_ HighBeamReq : 10|1@1+ (1,0) [0|1] "" VIU_B,CDCU,VDR_TBOX,ADCU
 SG_ ReverseLampReq : 11|1@1+ (1,0) [0|1] "" VIU_C,VDR_TBOX,ADCU
 SG_ MainBrkLightReq : 12|2@1+ (1,0) [0|3] "" VIU_C,VDR_TBOX,ADCU
 SG_ TrailerBrkLightReq : 14|2@1+ (1,0) [0|3] "" VIU_C,VDR_TBOX,ADCU
 SG_ PosnLigjtReq : 16|1@1+ (1,0) [0|1] "" VIU_B,VIU_C,CDCU,VDR_TBOX,CMS_R,CMS_B,ADCU
 SG_ BacklightAdjustReq : 17|4@1+ (1,0) [0|15] "" VIU_B,VDR_TBOX,ADCU
 SG_ LeftDayTimeRunngLiReq : 21|1@1+ (1,0) [0|1] "" VDR_TBOX,ADCU
 SG_ RightDayTimeRunngLiReq : 22|1@1+ (1,0) [0|1] "" VDR_TBOX,ADCU
 SG_ RearFogLampReq : 23|1@1+ (1,0) [0|1] "" VIU_C,CDCU,VDR_TBOX,ADCU
 SG_ RearFogLampReplcmtReq : 24|1@1+ (1,0) [0|1] "" VDR_TBOX,ADCU
 SG_ LanternLanguageReq : 25|4@1+ (1,0) [0|15] "" VDR_TBOX
 SG_ IVI_FrontFogLampLinkageSetFB : 29|1@1+ (1,0) [0|1] "" CDCU
 SG_ LampFollowMeHomeSetSts : 32|2@1+ (1,0) [0|3] "" CDCU,VDR_TBOX
 SG_ LampAwayHomeSetSts : 34|2@1+ (1,0) [0|3] "" CDCU,VDR_TBOX
 SG_ ExtrMirrHeatCtrl : 36|2@1+ (1,0) [0|3] "" VIU_B,CDCU,VDR_TBOX
 SG_ ExtrMirrDirAdjmtCtrl_L : 40|3@1+ (1,0) [0|7] "" VIU_B,VDR_TBOX
 SG_ ExtrMirrDirAdjmtCtrl_R : 43|3@1+ (1,0) [0|7] "" VIU_B,VDR_TBOX
 SG_ FrontFogLampReq_L : 46|1@1+ (1,0) [0|1] "" VIU_B,CDCU,VDR_TBOX,ADCU
 SG_ FrontFogLampReq_R : 47|1@1+ (1,0) [0|1] "" VIU_B,CDCU,VDR_TBOX,ADCU

BO_ 2566861607 BodyCtrl1: 8 VDCU_M
 SG_ WinReq_L : 0|2@1+ (1,0) [0|3] "" VIU_B,VDR_TBOX
 SG_ WinReq_R : 2|2@1+ (1,0) [0|3] "" VIU_B,VDR_TBOX
 SG_ WasherReq : 8|2@1+ (1,0) [0|3] "" VIU_B,VDR_TBOX
 SG_ WiperReq : 10|3@1+ (1,0) [0|7] "" VIU_B,VDR_TBOX
 SG_ OutIncrWinAntAlarm : 13|1@1+ (1,0) [0|1] "" VIU_B
 SG_ StartStopButtonLiReq : 14|2@1+ (1,0) [0|3] "" VDR_TBOX
 SG_ RelayReq_ACC : 16|1@1+ (1,0) [0|1] "" VDR_TBOX
 SG_ RelayReq_IG1 : 17|1@1+ (1,0) [0|1] "" VDR_TBOX
 SG_ RelayReq_IG2 : 18|1@1+ (1,0) [0|1] "" VDR_TBOX
 SG_ CrankReq : 19|1@1+ (1,0) [0|1] "" VDR_TBOX
 SG_ RelaySts_ACC : 20|1@1+ (1,0) [0|1] "" VDR_TBOX
 SG_ RelaySts_IG1 : 21|1@1+ (1,0) [0|1] "" VDR_TBOX
 SG_ RelaySts_IG2 : 22|1@1+ (1,0) [0|1] "" VDR_TBOX
 SG_ LowPowerMode : 24|4@1+ (1,0) [0|15] "" VIU_B,VIU_C,CDCU,VDR_TBOX,CMS_R,CMS_B,ADCU,EPB,FCS,EBS,EPS_M,EPS_S,ECAS,EGSM
 SG_ RmtLowPowerMode : 29|1@1+ (1,0) [0|1] "" VIU_B
 SG_ RainCloseWinSwt_Fb : 30|2@1+ (1,0) [0|3] "" CDCU,VDR_TBOX
 SG_ RmtLocaloutreq_VDCU : 32|2@1+ (1,0) [0|1] "" VDR_TBOX
 SG_ BluetoothKeyConnect : 36|2@1+ (1,0) [0|2] "" VIU_B
 SG_ BluetoothKeyLocation : 41|3@1+ (1,0) [0|4] "" VIU_B
 SG_ BluetoothKeyReq : 44|4@1+ (1,0) [0|15] "" VIU_B
 SG_ BluetoothPhoneConnect : 48|2@1+ (1,0) [0|3] "" VIU_B
 SG_ PrimaryAntennaSleepSts : 50|2@1+ (1,0) [0|3] "" VIU_B

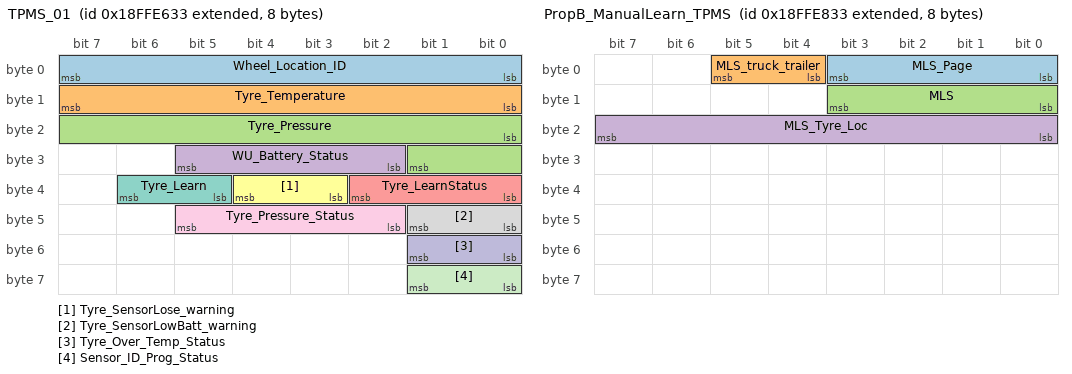
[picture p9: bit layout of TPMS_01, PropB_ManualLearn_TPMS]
BO_ 2566907443 TPMS_01: 8 VIU_C
 SG_ Wheel_Location_ID : 0|8@1+ (1,0) [0|255] "bit-mapped" VDCU_M
 SG_ Tyre_Temperature : 8|8@1+ (1,-40) [-40|215] "degC" VDCU_M
 SG_ Tyre_Pressure : 16|10@1+ (2,0) [0|2046] "Kpa" VDCU_M
 SG_ WU_Battery_Status : 26|4@1+ (10,0) [0|150] "%" VDCU_M
 SG_ Tyre_LearnStatus : 32|3@1+ (1,0) [0|7] "" VDCU_M
 SG_ Tyre_SensorLose_warning : 35|2@1+ (1,0) [0|3] "" VDCU_M
 SG_ Tyre_Learn : 37|2@1+ (1,0) [0|3] "" VDCU_M
 SG_ Tyre_SensorLowBatt_warning : 40|2@1+ (1,0) [0|3] "" VDCU_M
 SG_ Tyre_Pressure_Status : 42|4@1+ (1,0) [0|15] "" VDCU_M
 SG_ Tyre_Over_Temp_Status : 48|2@1+ (1,0) [0|3] "" VDCU_M
 SG_ Sensor_ID_Prog_Status : 56|2@1+ (1,0) [0|3] "" VDCU_M

BO_ 2566907955 PropB_ManualLearn_TPMS: 8 VIU_C
 SG_ MLS_Page : 0|4@1+ (1,0) [0|15] "" VDCU_M
 SG_ MLS_truck_trailer : 4|2@1+ (1,0) [0|3] "" VDCU_M
 SG_ MLS : 8|4@1+ (1,0) [0|15] "" VDCU_M
 SG_ MLS_Tyre_Loc : 16|8@1+ (1,0) [0|255] "" VDCU_M

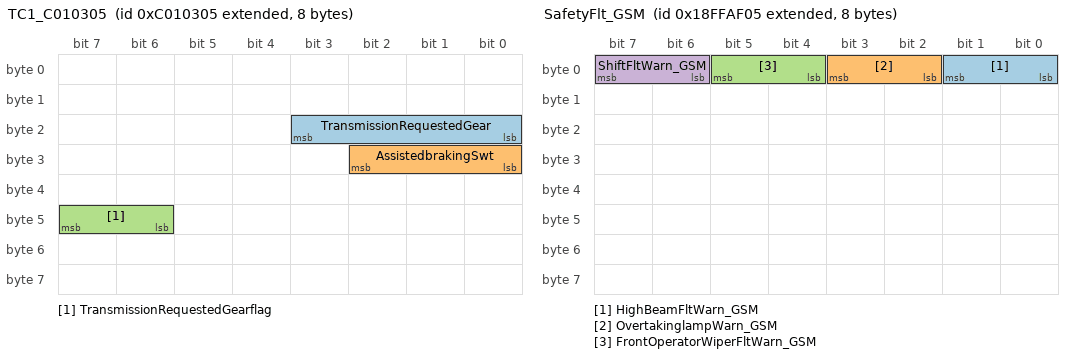
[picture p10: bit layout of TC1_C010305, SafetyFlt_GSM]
BO_ 2348876549 TC1_C010305: 8 EGSM
 SG_ TransmissionRequestedGear : 16|4@1+ (1,0) [0|15] "" VDCU_M
 SG_ AssistedbrakingSwt : 24|3@1+ (1,0) [0|7] "" VDCU_M
 SG_ TransmissionRequestedGearflag : 46|2@1+ (1,0) [0|3] "" VDCU_M

BO_ 2566893317 SafetyFlt_GSM: 8 EGSM
 SG_ HighBeamFltWarn_GSM : 0|2@1+ (1,0) [0|3] "" VDCU_M
 SG_ OvertakinglampWarn_GSM : 2|2@1+ (1,0) [0|3] "" VDCU_M
 SG_ FrontOperatorWiperFltWarn_GSM : 4|2@1+ (1,0) [0|3] "" VDCU_M
 SG_ ShiftFltWarn_GSM : 6|2@1+ (1,0) [0|3] "" VDCU_M

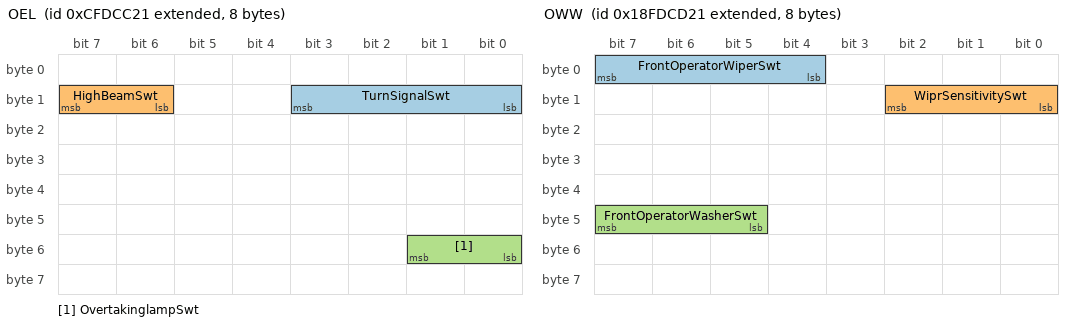
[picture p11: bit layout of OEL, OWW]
BO_ 2365443105 OEL: 8 EGSM
 SG_ TurnSignalSwt : 8|4@1+ (1,0) [0|15] "" VDCU_M
 SG_ HighBeamSwt : 14|2@1+ (1,0) [0|3] "" VDCU_M
 SG_ OvertakinglampSwt : 48|2@1+ (1,0) [0|3] "" VDCU_M

BO_ 2566769953 OWW: 8 EGSM
 SG_ FrontOperatorWiperSwt : 4|4@1+ (1,0) [0|15] "" VDCU_M
 SG_ WiprSensitivitySwt : 8|3@1+ (1,0) [0|7] "" VDCU_M
 SG_ FrontOperatorWasherSwt : 45|3@1+ (1,0) [0|7] "" VDCU_M

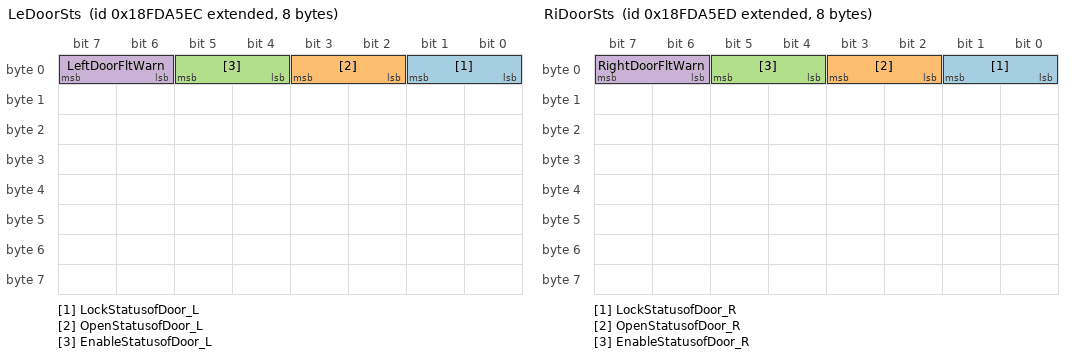
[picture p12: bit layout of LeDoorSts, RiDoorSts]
BO_ 2566759916 LeDoorSts: 8 VIU_B
 SG_ LockStatusofDoor_L : 0|2@1+ (1,0) [0|3] "" VDCU_M
 SG_ OpenStatusofDoor_L : 2|2@1+ (1,0) [0|3] "" VDCU_M
 SG_ EnableStatusofDoor_L : 4|2@1+ (1,0) [0|3] "" VDCU_M
 SG_ LeftDoorFltWarn : 6|2@1+ (1,0) [0|3] "" VDCU_M

BO_ 2566759917 RiDoorSts: 8 VIU_B
 SG_ LockStatusofDoor_R : 0|2@1+ (1,0) [0|3] "" VDCU_M
 SG_ OpenStatusofDoor_R : 2|2@1+ (1,0) [0|3] "" VDCU_M
 SG_ EnableStatusofDoor_R : 4|2@1+ (1,0) [0|3] "" VDCU_M
 SG_ RightDoorFltWarn : 6|2@1+ (1,0) [0|3] "" VDCU_M

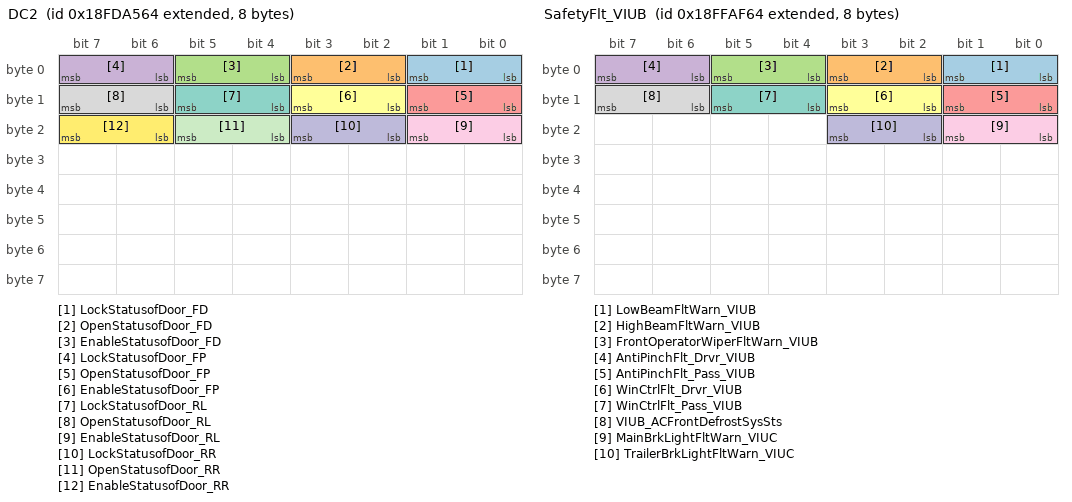
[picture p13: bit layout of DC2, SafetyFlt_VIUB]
BO_ 2566759780 DC2: 8 VIU_B
 SG_ LockStatusofDoor_FD : 0|2@1+ (1,0) [0|3] "" VDCU_M
 SG_ OpenStatusofDoor_FD : 2|2@1+ (1,0) [0|3] "" VDCU_M
 SG_ EnableStatusofDoor_FD : 4|2@1+ (1,0) [0|3] "" VDCU_M
 SG_ LockStatusofDoor_FP : 6|2@1+ (1,0) [0|3] "" VDCU_M
 SG_ OpenStatusofDoor_FP : 8|2@1+ (1,0) [0|3] "" VDCU_M
 SG_ EnableStatusofDoor_FP : 10|2@1+ (1,0) [0|3] "" VDCU_M
 SG_ LockStatusofDoor_RL : 12|2@1+ (1,0) [0|3] "" VDCU_M
 SG_ OpenStatusofDoor_RL : 14|2@1+ (1,0) [0|3] "" VDCU_M
 SG_ EnableStatusofDoor_RL : 16|2@1+ (1,0) [0|3] "" VDCU_M
 SG_ LockStatusofDoor_RR : 18|2@1+ (1,0) [0|3] "" VDCU_M
 SG_ OpenStatusofDoor_RR : 20|2@1+ (1,0) [0|3] "" VDCU_M
 SG_ EnableStatusofDoor_RR : 22|2@1+ (1,0) [0|3] "" VDCU_M

BO_ 2566874468 BodySts1: 8 VIU_B
 SG_ RearviewHeatSts : 0|2@1+ (1,0) [0|3] "" VDCU_M
 SG_ RearviewHeatRelayFlt : 2|2@1+ (1,0) [0|3] "" VDCU_M
 SG_ BacklightAdjustSts : 4|4@1+ (1,0) [0|15] "" VDCU_M
 SG_ UnlockTypeSetFb : 8|1@1+ (1,0) [0|1] "" VDCU_M
 SG_ PwroffAutoUnlockSetFb : 9|1@1+ (1,0) [0|1] "" VDCU_M
 SG_ SpdLockSetFb : 10|2@1+ (1,0) [0|3] "" VDCU_M
 SG_ ExternalKeySts : 12|2@1+ (1,0) [0|3] "" VDCU_M
 SG_ LockPromptSetSts : 14|1@1+ (1,0) [0|1] "" VDCU_M
 SG_ SearchingCarPromptSetSts : 15|1@1+ (1,0) [0|1] "" VDCU_M
 SG_ KeyNotDetectedWarn : 16|1@1+ (1,0) [0|1] "" VDCU_M
 SG_ LowBatteryWarn : 17|1@1+ (1,0) [0|1] "" VDCU_M
 SG_ KeyPutAntennaWarn : 18|1@1+ (1,0) [0|1] "" VDCU_M
 SG_ PEPSFaultWarn : 19|1@1+ (1,0) [0|1] "" VDCU_M
 SG_ KeyInCarOpenWhenExitWarn : 20|1@1+ (1,0) [0|1] "" VDCU_M
 SG_ PowerSwt_220V : 21|2@1+ (1,0) [0|3] "" VDCU_M
 SG_ StartStopButtonSts : 23|1@1+ (1,0) [0|1] "" VDCU_M
 SG_ EmgyShutdownReq : 24|1@1+ (1,0) [0|1] "" VDCU_M
 SG_ KeySearchLFReq : 25|1@1+ (1,0) [0|1] "" VDCU_M
 SG_ LFAntennaFlt : 26|2@1+ (1,0) [0|3] "" VDCU_M
 SG_ StartConditionMet : 28|1@1+ (1,0) [0|1] "" VDCU_M
 SG_ KeyAuthenticationSts : 29|2@1+ (1,0) [0|3] "" VDCU_M
 SG_ KeyNumber : 32|3@1+ (1,0) [0|7] "" VDCU_M
 SG_ KeyPosition : 35|3@1+ (1,0) [0|7] "" VDCU_M
 SG_ ExtrMirrSelectSts : 41|2@1+ (1,0) [0|3] "" VDCU_M
 SG_ AutoLampReq : 60|2@1+ (1,0) [0|3] "" VDCU_M

BO_ 2566874724 BodySts2: 8 VIU_B
 SG_ ElectricHornRelaySts : 0|2@1+ (1,0) [0|3] "" VDCU_M
 SG_ AirHornRelaySts : 2|2@1+ (1,0) [0|3] "" VDCU_M
 SG_ HornSwt : 4|1@1+ (1,0) [0|1] "" VDCU_M
 SG_ CabAntitheftSts : 5|3@1+ (1,0) [0|7] "" VDCU_M
 SG_ LockElectricHornReq : 8|2@1+ (1,0) [0|3] "" VDCU_M
 SG_ SearchingCarElectricHorReq : 10|2@1+ (1,0) [0|3] "" VDCU_M
 SG_ WiperParkSwt : 12|2@1+ (1,0) [0|3] "" VDCU_M
 SG_ WiperSts : 14|2@1+ (1,0) [0|3] "" VDCU_M
 SG_ WasherSts : 16|2@1+ (1,0) [0|3] "" VDCU_M
 SG_ WiperMotorFlt : 18|1@1+ (1,0) [0|1] "" VDCU_M
 SG_ WasherMotorFlt : 19|1@1+ (1,0) [0|1] "" VDCU_M
 SG_ HazardSwitch : 20|2@1+ (1,0) [0|3] "" VDCU_M
 SG_ TurnLightSts_LM : 22|1@1+ (1,0) [0|1] "" VDCU_M
 SG_ TurnLightSts_RM : 23|1@1+ (1,0) [0|1] "" VDCU_M
 SG_ TurnLightFlt_LM : 24|2@1+ (1,0) [0|3] "" VDCU_M
 SG_ TurnLightFlt_RM : 26|2@1+ (1,0) [0|3] "" VDCU_M
 SG_ AutoLampSwt : 28|2@1+ (1,0) [0|3] "" VDCU_M
 SG_ PsnLampSwt : 30|2@1+ (1,0) [0|3] "" VDCU_M
 SG_ LowBeamSwt : 32|2@1+ (1,0) [0|3] "" VDCU_M
 SG_ LeftLowBeamSts : 34|1@1+ (1,0) [0|1] "" VDCU_M
 SG_ LeftLowBeamFlt : 35|2@1+ (1,0) [0|3] "" VDCU_M
 SG_ RightLowBeamSts : 37|1@1+ (1,0) [0|1] "" VDCU_M
 SG_ RightLowBeamFlt : 38|2@1+ (1,0) [0|3] "" VDCU_M
 SG_ HighBeamSts : 40|1@1+ (1,0) [0|1] "" VDCU_M
 SG_ HighBeamFlt : 41|2@1+ (1,0) [0|3] "" VDCU_M
 SG_ PositionLightSts_L : 43|1@1+ (1,0) [0|1] "" VDCU_M
 SG_ PositionLightFlt_L : 44|2@1+ (1,0) [0|3] "" VDCU_M
 SG_ PositionLightSts_R : 46|1@1+ (1,0) [0|1] "" VDCU_M
 SG_ PositionLightFlt_R : 48|2@1+ (1,0) [0|3] "" VDCU_M
 SG_ RearFogLightSwt : 50|2@1+ (1,0) [0|3] "" VDCU_M
 SG_ FrontFogLightSwt : 52|2@1+ (1,0) [0|3] "" VDCU_M
 SG_ Electric_AirHornSetSts : 54|1@1+ (1,0) [0|1] "" VDCU_M
 SG_ ElectricHornReq : 55|1@1+ (1,0) [0|1] "" VDCU_M
 SG_ AirHornReq : 56|1@1+ (1,0) [0|1] "" VDCU_M
 SG_ FrontFogLightSts_L : 57|1@1+ (1,0) [0|1] "" VDCU_M
 SG_ FrontFogLightFltMode_L : 58|2@1+ (1,0) [0|3] "" VDCU_M
 SG_ FrontFogLightSts_R : 60|1@1+ (1,0) [0|1] "" VDCU_M
 SG_ FrontFogLightFltMode_R : 61|2@1+ (1,0) [0|3] "" VDCU_M
 SG_ EgySavingPwrSplySts : 63|1@1+ (1,0) [0|1] "" VDCU_M

BO_ 2566875236 LockCtrlSts: 8 VIU_B
 SG_ LockSource_MasterLock : 0|2@1+ (1,0) [0|3] "" VDCU_M
 SG_ LockSource_SleeperLock : 2|2@1+ (1,0) [0|3] "" VDCU_M
 SG_ LockSource_RkeLock : 4|4@1+ (1,0) [0|15] "" VDCU_M
 SG_ LockSource_RemoteLock : 8|3@1+ (1,0) [0|7] "" VDCU_M
 SG_ LockSource_AutoReLock : 11|1@1+ (1,0) [0|1] "" VDCU_M
 SG_ LockSource_PkeLock : 12|2@1+ (1,0) [0|3] "" VDCU_M
 SG_ LockSource_CrashLock : 14|1@1+ (1,0) [0|1] "" VDCU_M
 SG_ LockSource_DKMLock : 16|3@1+ (1,0) [0|7] "" VDCU_M
 SG_ LockSource_Insd_Outd : 19|3@1+ (1,0) [0|7] "" VDCU_M
 SG_ Lock_Unlock_SucessFb : 22|2@1+ (1,0) [0|3] "" VDCU_M
 SG_ PlayPrevnSts_LPKE_Unlock : 24|1@1+ (1,0) [0|1] "" VDCU_M
 SG_ PlayPrevnSts_LPKE_Lock : 25|1@1+ (1,0) [0|1] "" VDCU_M
 SG_ PlayPrevnSts_RPKE_Unlock : 26|1@1+ (1,0) [0|1] "" VDCU_M
 SG_ PlayPrevnSts_RPKE_Lock : 27|1@1+ (1,0) [0|1] "" VDCU_M
 SG_ CentralLockSw : 28|2@1+ (1,0) [0|3] "" VDCU_M
 SG_ AutoUnlockReq : 30|1@1+ (1,0) [0|1] "" VDCU_M
 SG_ SpeedReqLock : 31|1@1+ (1,0) [0|1] "" VDCU_M
 SG_ LockUnlockReq_L : 32|2@1+ (1,0) [0|3] "" VDCU_M
 SG_ LockUnlockReq_R : 34|2@1+ (1,0) [0|3] "" VDCU_M
 SG_ LockOverheatProtection_L : 36|1@1+ (1,0) [0|1] "" VDCU_M
 SG_ LockOverheatProtection_R : 37|1@1+ (1,0) [0|1] "" VDCU_M
 SG_ PlayPrevnSts_LPKE : 38|2@1+ (1,0) [0|3] "" VDCU_M
 SG_ PlayPrevnSts_RPKE : 40|2@1+ (1,0) [0|3] "" VDCU_M
 SG_ RearFogLightSts : 42|1@1+ (1,0) [0|1] "" VDCU_M
 SG_ RearFogLightFltMode : 43|2@1+ (1,0) [0|3] "" VDCU_M
 SG_ RearFogLightSts_T : 45|1@1+ (1,0) [0|1] "" VDCU_M
 SG_ RearFogLightFltMode_T : 46|2@1+ (1,0) [0|3] "" VDCU_M
 SG_ ExtrMirrHozlAdjMotorSts_R : 48|2@1+ (1,0) [0|3] "" VDCU_M
 SG_ ExtrMirrVertAdjMotorSts_R : 50|2@1+ (1,0) [0|3] "" VDCU_M
 SG_ ExtrMirrHozlAdjMotorSts_L : 52|2@1+ (1,0) [0|3] "" VDCU_M
 SG_ ExtrMirrVertAdjMotorSts_L : 54|2@1+ (1,0) [0|3] "" VDCU_M
 SG_ MainBrkLightSts : 56|2@1+ (1,0) [0|3] "" VDCU_M
 SG_ TrailerBrkLightSts : 58|2@1+ (1,0) [0|3] "" VDCU_M
 SG_ MainBrkLightFltMode : 60|2@1+ (1,0) [0|3] "" VDCU_M
 SG_ TrailerBrkLightFltMode : 62|2@1+ (1,0) [0|3] "" VDCU_M

BO_ 2566893412 SafetyFlt_VIUB: 8 VIU_B
 SG_ LowBeamFltWarn_VIUB : 0|2@1+ (1,0) [0|3] "" VDCU_M
 SG_ HighBeamFltWarn_VIUB : 2|2@1+ (1,0) [0|3] "" VDCU_M
 SG_ FrontOperatorWiperFltWarn_VIUB : 4|2@1+ (1,0) [0|3] "" VDCU_M
 SG_ AntiPinchFlt_Drvr_VIUB : 6|2@1+ (1,0) [0|3] "" VDCU_M
 SG_ AntiPinchFlt_Pass_VIUB : 8|2@1+ (1,0) [0|3] "" VDCU_M
 SG_ WinCtrlFlt_Drvr_VIUB : 10|2@1+ (1,0) [0|3] "" VDCU_M
 SG_ WinCtrlFlt_Pass_VIUB : 12|2@1+ (1,0) [0|3] "" VDCU_M
 SG_ VIUB_ACFrontDefrostSysSts : 14|2@1+ (1,0) [0|3] "" VDCU_M
 SG_ MainBrkLightFltWarn_VIUC : 16|2@1+ (1,0) [0|3] "" VDCU_M
 SG_ TrailerBrkLightFltWarn_VIUC : 18|2@1+ (1,0) [0|3] "" VDCU_M

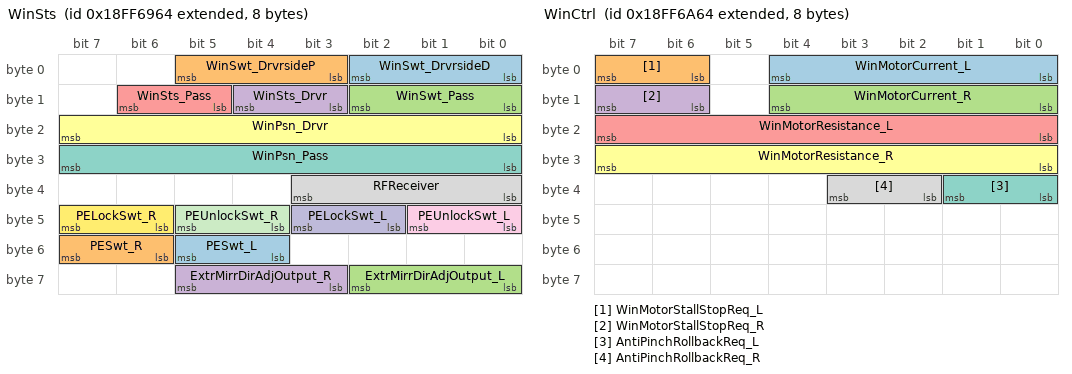
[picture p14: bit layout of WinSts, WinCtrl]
BO_ 2566875492 WinSts: 8 VIU_B
 SG_ WinSwt_DrvrsideD : 0|3@1+ (1,0) [0|7] "" VDCU_M
 SG_ WinSwt_DrvrsideP : 3|3@1+ (1,0) [0|7] "" VDCU_M
 SG_ WinSwt_Pass : 8|3@1+ (1,0) [0|7] "" VDCU_M
 SG_ WinSts_Drvr : 11|2@1+ (1,0) [0|3] "" VDCU_M
 SG_ WinSts_Pass : 13|2@1+ (1,0) [0|3] "" VDCU_M
 SG_ WinPsn_Drvr : 16|8@1+ (1,0) [0|255] "%" VDCU_M
 SG_ WinPsn_Pass : 24|8@1+ (1,0) [0|255] "%" VDCU_M
 SG_ RFReceiver : 32|4@1+ (1,0) [0|15] "" VDCU_M
 SG_ PEUnlockSwt_L : 40|2@1+ (1,0) [0|3] "" VDCU_M
 SG_ PELockSwt_L : 42|2@1+ (1,0) [0|3] "" VDCU_M
 SG_ PEUnlockSwt_R : 44|2@1+ (1,0) [0|3] "" VDCU_M
 SG_ PELockSwt_R : 46|2@1+ (1,0) [0|3] "" VDCU_M
 SG_ PESwt_L : 52|2@1+ (1,0) [0|3] "" VDCU_M
 SG_ PESwt_R : 54|2@1+ (1,0) [0|3] "" VDCU_M
 SG_ ExtrMirrDirAdjOutput_L : 56|3@1+ (1,0) [0|7] "" VDCU_M
 SG_ ExtrMirrDirAdjOutput_R : 59|3@1+ (1,0) [0|7] "" VDCU_M

BO_ 2566875748 WinCtrl: 8 VIU_B
 SG_ WinMotorCurrent_L : 0|5@1+ (1,0) [0|31] "A" VDCU_M
 SG_ WinMotorStallStopReq_L : 6|2@1+ (1,0) [0|3] "" VDCU_M
 SG_ WinMotorCurrent_R : 8|5@1+ (1,0) [0|31] "A" VDCU_M
 SG_ WinMotorStallStopReq_R : 14|2@1+ (1,0) [0|3] "" VDCU_M
 SG_ WinMotorResistance_L : 16|8@1+ (1,0) [0|255] "N" VDCU_M
 SG_ WinMotorResistance_R : 24|8@1+ (1,0) [0|255] "N" VDCU_M
 SG_ AntiPinchRollbackReq_L : 32|2@1+ (1,0) [0|3] "" VDCU_M
 SG_ AntiPinchRollbackReq_R : 34|2@1+ (1,0) [0|3] "" VDCU_M

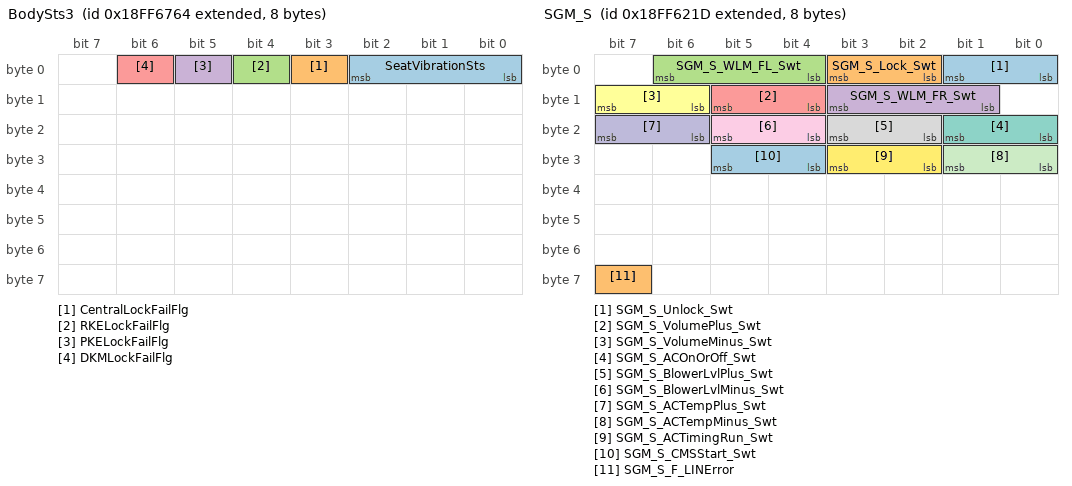
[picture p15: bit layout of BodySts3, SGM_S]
BO_ 2566874980 BodySts3: 8 VIU_B
 SG_ SeatVibrationSts : 0|3@1+ (1,0) [0|7] "" VDCU_M
 SG_ CentralLockFailFlg : 3|1@1+ (1,0) [0|1] "" VDCU_M
 SG_ RKELockFailFlg : 4|1@1+ (1,0) [0|1] "" VDCU_M
 SG_ PKELockFailFlg : 5|1@1+ (1,0) [0|1] "" VDCU_M
 SG_ DKMLockFailFlg : 6|1@1+ (1,0) [0|1] "" VDCU_M

BO_ 2365522788 EncryptData_VIU: 20 VIU_B
 SG_ CertificationSts_VIU : 0|4@1+ (1,0) [0|128] "" VDCU_M
 SG_ CMAC1_VIU : 8|8@1+ (1,0) [0|255] "" VDCU_M
 SG_ CMAC2_VIU : 16|8@1+ (1,0) [0|255] "" VDCU_M
 SG_ CMAC3_VIU : 24|8@1+ (1,0) [0|255] "" VDCU_M
 SG_ CMAC4_VIU : 32|8@1+ (1,0) [0|255] "" VDCU_M
 SG_ CMAC5_VIU : 40|8@1+ (1,0) [0|255] "" VDCU_M
 SG_ CMAC6_VIU : 48|8@1+ (1,0) [0|255] "" VDCU_M
 SG_ CMAC7_VIU : 56|8@1+ (1,0) [0|255] "" VDCU_M
 SG_ CMAC8_VIU : 64|8@1+ (1,0) [0|255] "" VDCU_M
 SG_ CMAC9_VIU : 72|8@1+ (1,0) [0|255] "" VDCU_M
 SG_ CMAC10_VIU : 80|8@1+ (1,0) [0|255] "" VDCU_M
 SG_ CMAC11_VIU : 88|8@1+ (1,0) [0|255] "" VDCU_M
 SG_ CMAC12_VIU : 96|8@1+ (1,0) [0|255] "" VDCU_M
 SG_ CMAC13_VIU : 104|8@1+ (1,0) [0|255] "" VDCU_M
 SG_ CMAC14_VIU : 112|8@1+ (1,0) [0|255] "" VDCU_M
 SG_ CMAC15_VIU : 120|8@1+ (1,0) [0|255] "" VDCU_M
 SG_ CMAC16_VIU : 128|8@1+ (1,0) [0|255] "" VDCU_M

BO_ 2566845721 AMB1: 8 VDCU_M
 SG_ AmbAirT : 24|16@1+ (0.03125,-273) [-273|1734] "°C" VIU_C,CDCU,MTCU

BO_ 2566873629 SGM_S: 8 VDCU_M
 SG_ SGM_S_Unlock_Swt : 0|2@1+ (1,0) [0|3] "" VIU_B
 SG_ SGM_S_Lock_Swt : 2|2@1+ (1,0) [0|3] "" VIU_B
 SG_ SGM_S_WLM_FL_Swt : 4|3@1+ (1,0) [0|7] "" Vector__XXX
 SG_ SGM_S_WLM_FR_Swt : 9|3@1+ (1,0) [0|7] "" Vector__XXX
 SG_ SGM_S_VolumePlus_Swt : 12|2@1+ (1,0) [0|3] "" CDCU
 SG_ SGM_S_VolumeMinus_Swt : 14|2@1+ (1,0) [0|3] "" CDCU
 SG_ SGM_S_ACOnOrOff_Swt : 16|2@1+ (1,0) [0|3] "" Vector__XXX
 SG_ SGM_S_BlowerLvlPlus_Swt : 18|2@1+ (1,0) [0|3] "" Vector__XXX
 SG_ SGM_S_BlowerLvlMinus_Swt : 20|2@1+ (1,0) [0|3] "" Vector__XXX
 SG_ SGM_S_ACTempPlus_Swt : 22|2@1+ (1,0) [0|3] "" Vector__XXX
 SG_ SGM_S_ACTempMinus_Swt : 24|2@1+ (1,0) [0|3] "" Vector__XXX
 SG_ SGM_S_ACTimingRun_Swt : 26|2@1+ (1,0) [0|3] "" Vector__XXX
 SG_ SGM_S_CMSStart_Swt : 28|2@1+ (1,0) [0|3] "" CMS_R,CMS_B
 SG_ SGM_S_F_LINError : 63|1@1+ (1,0) [0|1] "" VIU_B,CDCU,CMS_R,CMS_B

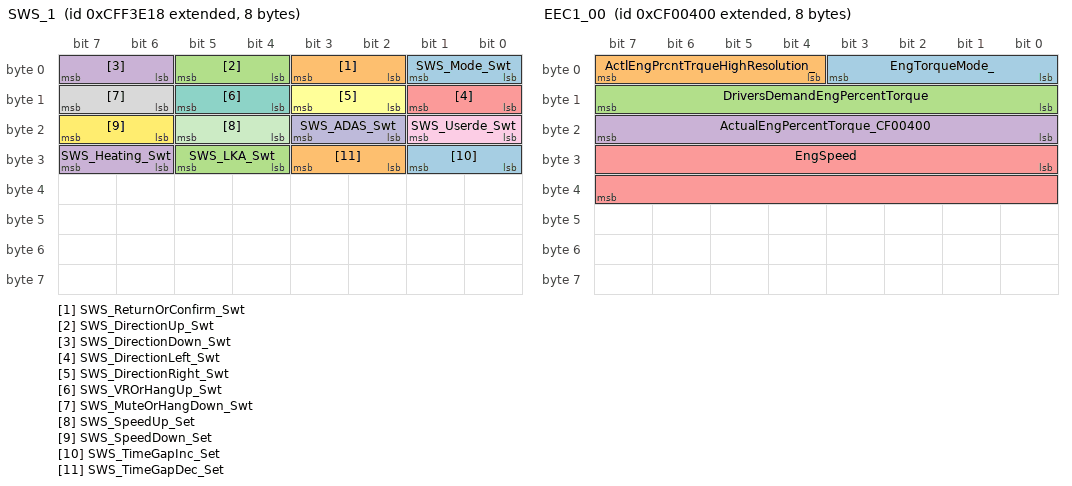
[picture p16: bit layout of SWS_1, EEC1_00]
BO_ 2365537816 SWS_1: 8 VDCU_M
 SG_ SWS_Mode_Swt : 0|2@1+ (1,0) [0|3] "" CDCU
 SG_ SWS_ReturnOrConfirm_Swt : 2|2@1+ (1,0) [0|3] "" CDCU
 SG_ SWS_DirectionUp_Swt : 4|2@1+ (1,0) [0|3] "" CDCU
 SG_ SWS_DirectionDown_Swt : 6|2@1+ (1,0) [0|3] "" CDCU
 SG_ SWS_DirectionLeft_Swt : 8|2@1+ (1,0) [0|3] "" CDCU
 SG_ SWS_DirectionRight_Swt : 10|2@1+ (1,0) [0|3] "" CDCU
 SG_ SWS_VROrHangUp_Swt : 12|2@1+ (1,0) [0|3] "" CDCU
 SG_ SWS_MuteOrHangDown_Swt : 14|2@1+ (1,0) [0|3] "" CDCU
 SG_ SWS_Userde_Swt : 16|2@1+ (1,0) [0|3] "" CDCU,ADCU,FCS
 SG_ SWS_ADAS_Swt : 18|2@1+ (1,0) [0|3] "" CDCU,ADCU,FCS
 SG_ SWS_SpeedUp_Set : 20|2@1+ (1,0) [0|3] "" CDCU,ADCU,FCS
 SG_ SWS_SpeedDown_Set : 22|2@1+ (1,0) [0|3] "" CDCU,ADCU,FCS
 SG_ SWS_TimeGapInc_Set : 24|2@1+ (1,0) [0|3] "" CDCU,ADCU,FCS
 SG_ SWS_TimeGapDec_Set : 26|2@1+ (1,0) [0|3] "" CDCU,ADCU,FCS
 SG_ SWS_LKA_Swt : 28|2@1+ (1,0) [0|3] "" CDCU,ADCU,FCS
 SG_ SWS_Heating_Swt : 30|2@1+ (1,0) [0|3] "" VIU_B,CDCU

BO_ 2566873374 SGM_IP: 8 VDCU_M
 SG_ SGM_IP_HornType_Swt : 0|2@1+ (1,0) [0|3] "" VIU_B
 SG_ SGM_IP_RearLight_Swt : 2|2@1+ (1,0) [0|3] "" VIU_C
 SG_ SGM_IP_ACOff_Swt : 4|2@1+ (1,0) [0|3] "" Vector__XXX
 SG_ SGM_IP_BlowerLvlPlus_Swt : 6|2@1+ (1,0) [0|3] "" Vector__XXX
 SG_ SGM_IP_BlowerLvlMinus_Swt : 8|2@1+ (1,0) [0|3] "" Vector__XXX
 SG_ SGM_IP_ACTempPlus_Swt : 10|2@1+ (1,0) [0|3] "" Vector__XXX
 SG_ SGM_IP_ACTempMinus_Swt : 12|2@1+ (1,0) [0|3] "" Vector__XXX
 SG_ SGM_IP_ACFrontDefrost_Swt : 14|2@1+ (1,0) [0|3] "" Vector__XXX
 SG_ SGM_IP_F_LINError : 63|2@1+ (1,0) [0|3] "" Vector__XXX

BO_ 2364539904 EEC1_00: 8 VDCU_M
 SG_ EngTorqueMode_ : 0|4@1+ (1,0) [0|15] "%" VDR_TBOX,ADCU,EPB,FCS,EPS_M,EPS_S
 SG_ ActlEngPrcntTrqueHighResolution_ : 4|4@1+ (0.125,0) [0|0.875] "%" VDR_TBOX,ADCU,EPB,FCS,EBS,EPS_M,EPS_S
 SG_ DriversDemandEngPercentTorque : 8|8@1+ (1,-125) [-125|125] "%" VIU_C,VDR_TBOX,ADCU,EPB,FCS,EBS,EPS_M,EPS_S
 SG_ ActualEngPercentTorque_CF00400 : 16|8@1+ (1,-125) [-125|125] "%" VIU_C,VDR_TBOX,ADCU,EPB,FCS,EBS,EPS_M,EPS_S
 SG_ EngSpeed : 24|16@1+ (0.125,0) [0|8031.875] "rpm" VIU_C,VDR_TBOX,ADCU,EPB,FCS,EBS,EPS_M,EPS_S,ECAS

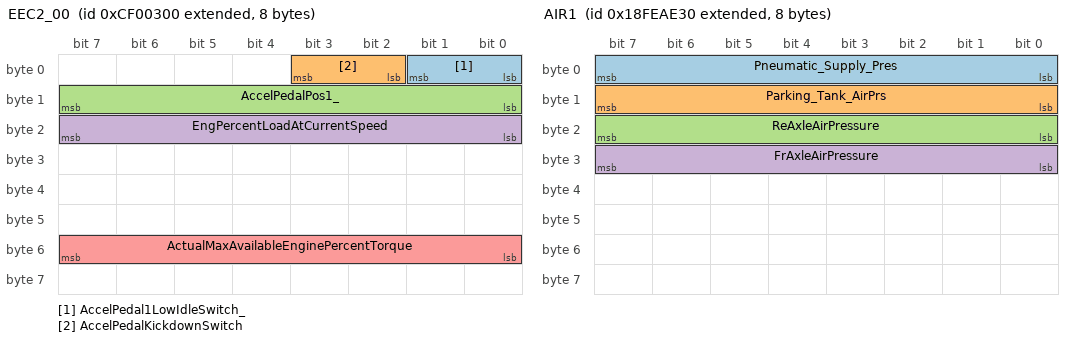
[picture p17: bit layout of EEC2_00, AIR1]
BO_ 2364539648 EEC2_00: 8 VDCU_M
 SG_ AccelPedal1LowIdleSwitch_ : 0|2@1+ (1,0) [0|3] "" VDR_TBOX,ADCU,EPB,FCS,EPS_M,EPS_S
 SG_ AccelPedalKickdownSwitch : 2|2@1+ (1,0) [0|3] "" VDR_TBOX,ADCU,EPB,FCS,EPS_M,EPS_S
 SG_ AccelPedalPos1_ : 8|8@1+ (0.4,0) [0|100] "%" VDR_TBOX,ADCU,EPB,FCS,EBS,EPS_M,EPS_S
 SG_ EngPercentLoadAtCurrentSpeed : 16|8@1+ (1,0) [0|250] "%" VIU_C,VDR_TBOX,ADCU,EPB,FCS,EBS,EPS_M,EPS_S
 SG_ ActualMaxAvailableEnginePercentTorque : 48|8@1+ (0.4,0) [0|100] "%" VDR_TBOX,ADCU,EPB,FCS,EPS_M,EPS_S

BO_ 2566827568 AIR1: 8 VIU_C
 SG_ Pneumatic_Supply_Pres : 0|8@1+ (8,0) [0|2000] "kpa" VDCU_M
 SG_ Parking_Tank_AirPrs : 8|8@1+ (8,0) [0|2040] "kpa" VDCU_M
 SG_ ReAxleAirPressure : 16|8@1+ (8,0) [0|2000] "kpa" VDCU_M
 SG_ FrAxleAirPressure : 24|8@1+ (8,0) [0|2000] "kpa" VDCU_M

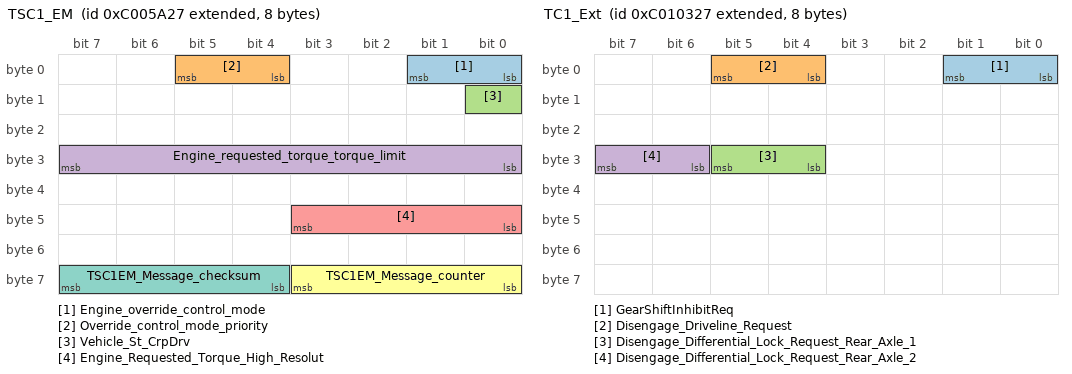
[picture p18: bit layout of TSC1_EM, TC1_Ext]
BO_ 2348833319 TSC1_EM: 8 VDCU_M
 SG_ Engine_override_control_mode : 0|2@1+ (1,0) [0|3] "" MTCU
 SG_ Override_control_mode_priority : 4|2@1+ (1,0) [0|3] "" MTCU
 SG_ Vehicle_St_CrpDrv : 8|1@1+ (1,0) [0|1] "" MTCU
 SG_ Engine_requested_torque_torque_limit : 24|8@1+ (1,-125) [-125|125] "%" MTCU
 SG_ Engine_Requested_Torque_High_Resolut : 40|4@1+ (0.125,0) [0|0.875] "%" MTCU
 SG_ TSC1EM_Message_counter : 56|4@1+ (1,0) [0|15] "" MTCU
 SG_ TSC1EM_Message_checksum : 60|4@1+ (1,0) [0|15] "" MTCU

BO_ 2348876583 TC1_Ext: 8 VDCU_M
 SG_ GearShiftInhibitReq : 0|2@1+ (1,0) [0|3] "" MTCU
 SG_ Disengage_Driveline_Request : 4|2@1+ (1,0) [0|3] "" MTCU
 SG_ Disengage_Differential_Lock_Request_Rear_Axle_1 : 28|2@1+ (1,0) [0|3] "" MTCU
 SG_ Disengage_Differential_Lock_Request_Rear_Axle_2 : 30|2@1+ (1,0) [0|3] "" MTCU

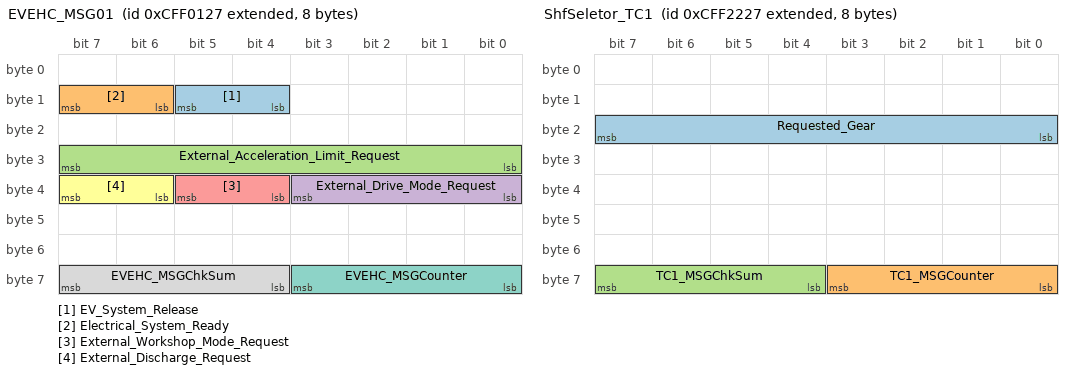
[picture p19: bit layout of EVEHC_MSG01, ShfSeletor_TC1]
BO_ 2365522215 EVEHC_MSG01: 8 VDCU_M
 SG_ EV_System_Release : 12|2@1+ (1,0) [0|3] "" MTCU
 SG_ Electrical_System_Ready : 14|2@1+ (1,0) [0|3] "" MTCU
 SG_ External_Acceleration_Limit_Request : 24|8@1+ (0.01,0) [0|2.5] "" MTCU
 SG_ External_Drive_Mode_Request : 32|4@1+ (1,0) [0|15] "" MTCU
 SG_ External_Workshop_Mode_Request : 36|2@1+ (1,0) [0|3] "" MTCU
 SG_ External_Discharge_Request : 38|2@1+ (1,0) [0|3] "" MTCU
 SG_ EVEHC_MSGCounter : 56|4@1+ (1,0) [0|15] "" MTCU
 SG_ EVEHC_MSGChkSum : 60|4@1+ (1,0) [0|15] "" MTCU

BO_ 2365530663 ShfSeletor_TC1: 8 VDCU_M
 SG_ Requested_Gear : 16|8@1+ (1,0) [0|255] "" MTCU
 SG_ TC1_MSGCounter : 56|4@1+ (1,0) [0|15] "" MTCU
 SG_ TC1_MSGChkSum : 60|4@1+ (1,0) [0|15] "" MTCU

BO_ 2364539687 Eng_EEC2: 8 VDCU_M
 SG_ Accelerator_Pedal_Position : 8|8@1+ (0.4,0) [0|100] "%" MTCU

BO_ 2566843687 CCSS: 8 VDCU_M
 SG_ MaxVehicleSpeedLimit : 0|8@1+ (1,0) [0|250] "km/h" MTCU

BO_ 2364575988 BMS_MSG01: 8 VDCU_M
 SG_ DCL_Voltage : 32|16@1+ (0.1,0) [0|6000] "V" MTCU
 SG_ DCL_Current : 48|16@1+ (0.1,-1000) [-1000|1000] "A" MTCU

BO_ 2364577012 BMS_MSG02: 8 VDCU_M
 SG_ DCL_Max_Current_Discharge : 0|16@1+ (0.1,-1000) [-1000|1000] "A" MTCU
 SG_ DCL_Max_Current_Charge : 16|16@1+ (0.1,-1000) [-1000|1000] "A" MTCU

BO_ 2364578036 BMS_MSG04: 8 VDCU_M
 SG_ BMS_DISCHG_MAX_PWR : 16|16@1+ (0.1,0) [0|1000] "kW" MTCU
 SG_ BMS_FEED_MAX_PWR_Instant : 32|16@1+ (0.1,0) [0|1000] "kW" MTCU

BO_ 2566698996 BMS_MSG03: 8 VDCU_M
 SG_ State_Of_Charge : 0|16@1+ (0.1,0) [0|100] "%" MTCU

BO_ 2566848756 BMS_MSG06: 8 VDCU_M
 SG_ DCL_Max_Voltage : 0|16@1+ (0.1,0) [0|6000] "V" MTCU
 SG_ DCL_Min_Voltage : 16|16@1+ (0.1,0) [0|6000] "V" MTCU

BO_ 2566846247 VEP: 8 VDCU_M
 SG_ Battery_voltage_24V : 48|16@1+ (0.05,0) [0|3212.75] "V" MTCU

CM_ SG_ 2566889511 VDCU_SourceNodeID "源节点 ID";
CM_ SG_ 2566889511 VDCU_ActiveWakeUpBit "主动唤醒标志位";
CM_ SG_ 2566889511 VDCU_RepeatMessageRequest "重复报文请求标志位";
CM_ SG_ 2566889511 VDCU_NMState_RMSfromBSM "重复报文状态（从总线睡眠模式切换而来）";
CM_ SG_ 2566889511 VDCU_NMState_RMSfromPBSM "重复报文状态（从预总线切换而来）";
CM_ SG_ 2566889511 VDCU_NMState_RMSfromNOS "重复报文状态（从正常运行状态切换而来）";
CM_ SG_ 2566889511 VDCU_NMState_RMSfromRSS "重复报文状态（从准备睡眠状态切换而来）";
CM_ SG_ 2566889511 VDCU_NMState_NOSfromRMS "正常运行状态（从重复报文状态切换而来）";
CM_ SG_ 2566889511 VDCU_NMState_NOSfromRSS "正常运行状态（从准备睡眠状态切换而来）";
CM_ SG_ 2566889511 VDCU_WakeupSource "唤醒源（本次唤醒的首次唤醒源）";
CM_ SG_ 2566889511 VDCU_NMKpARson_NMPduReceived "NM唤醒源（维持唤醒源）收到NM报文";
CM_ SG_ 2566889511 VDCU_NMKpARson_TimeOut "NM唤醒源（维持唤醒源）Repeat Message定时器没有到期";
CM_ SG_ 2566889511 VDCU_NMKpARson_Diag "NM唤醒源（维持唤醒源）诊断";
CM_ SG_ 2566889511 VDCU_NMKpARson_KL15 "NM唤醒源（维持唤醒源）检测到低压电源状态处于ON或Crank";
CM_ SG_ 2566889511 VDCU_NMKpARson_LINReq "NM唤醒源（维持唤醒源）LIN唤醒";
CM_ SG_ 2566889511 VDCU_NMKpARson_WinCtrl_L "NM唤醒源（维持唤醒源）主驾车窗控制命令输出";
CM_ SG_ 2566889511 VDCU_NMKpARson_WinCtrl_R "NM唤醒源（维持唤醒源）副驾车窗控制命令输出";
CM_ SG_ 2566889511 VDCU_NMKpARson_BrakePedalPressed "NM唤醒源（维持唤醒源）制动踏板踩下";
CM_ SG_ 2566889511 VDCU_NMKpARson_LowBeamReq "NM唤醒源（维持唤醒源）近光灯控制灯光输出命令";
CM_ SG_ 2566889511 VDCU_NMKpARson_PosnLigjtReq "NM唤醒源（维持唤醒源）位置灯控制灯光输出命令";
CM_ SG_ 2566889511 VDCU_NMKpARson_DCChargeActive "NM唤醒源（维持唤醒源）直流充电激活信号有效";
CM_ SG_ 2566889511 VDCU_NMKpARson_PowerOFFdelayMonitor "NM唤醒源（维持唤醒源）下电延时监控有效";
CM_ SG_ 2566889511 VDCU_NMKpARson_ACChargeActive "NM唤醒源（维持唤醒源）交流充电激活信号有效";
CM_ SG_ 2566889511 VDCU_NMKpARson_HVConnected "NM唤醒源（维持唤醒源）检测到高压上电处于高压连接状态";
CM_ SG_ 2566889511 VDCU_NMKpARson_ChargeWarmer "NM唤醒源（维持唤醒源）电池充电保温功能激活";
CM_ SG_ 2566889511 VDCU_NMKpARson_Ready "NM唤醒源（维持唤醒源）高压连接状态";
CM_ SG_ 2566889511 VDCU_NMKpARson_SmartCharge "NM唤醒源（维持唤醒源）蓄电池智能补电功能激活";
CM_ SG_ 2566865177 ACTempLevelDisp "用户设定温度显示 按0.5精度 17-32";
CM_ SG_ 2566865177 ACPTCDisp "Beacon预留，空调PTC档位显示";
CM_ SG_ 2566865177 ACTempLevelCtrl "用户设定温度控制";
CM_ SG_ 2566865177 ACModeMotorDisp "模式挡位显示";
CM_ SG_ 2566865177 ACModeMotorCtrl "模式风门电机位置控制";
CM_ SG_ 2566865177 ACCycleMotorDisp "内外循环档位显示 inside and outside circulation mode";
CM_ SG_ 2566865177 ACCycleMotorPosnCtrl "内外循环风门电机位置控制";
CM_ SG_ 2566865177 ACBlowerLevelDisp "风量档位显示";
CM_ SG_ 2566865177 ACBlowerLevelCtrl "鼓风机挡位控制";
CM_ SG_ 2566865177 ACFrontDefrostDisp "前除霜档位显示";
CM_ SG_ 2566865177 ACAcDisp "空调AC档位显示";
CM_ SG_ 2566865177 ACMaxDisp "ACMax档位显示（急速制冷）";
CM_ SG_ 2566865177 ACAutoDisp "Auto档位显示";
CM_ SG_ 2566865177 ACOffDisp "OFF档位显示OFF控制=OFF即空调开机";
CM_ SG_ 2566865177 ACAirPurgeDisp "空气净化显示";
CM_ SG_ 2566865177 ACAirPurgeCtrl "空气净化控制";
CM_ SG_ 2566865177 ACLonizerDisp "负离子发生器工作显示";
CM_ SG_ 2566865177 ACLonizerCtrl "负离子发生器控制";
CM_ SG_ 2566865177 AC_TempZoneSyncSts "空调温区同步状态反馈 前排卧铺同步";
CM_ SG_ 2566865177 AC_HeatingMaxSts "前排急速制热状态（急速制热）";
CM_ SG_ 2566865177 ElecACTempLevelDisp "Beacon，电动空调温度档位显示";
CM_ SG_ 2566868505 HVPowerOnReq_HBattFan "预留。高压冷却风扇-电堆上高压请求";
CM_ SG_ 2566868505 HVPowerOnReq_HMotorFan "预留。高压冷却风扇-电机上高压请求";
CM_ SG_ 2566868505 HVPowerOnReq_EAS1 "压缩机1（空调）上高压请求";
CM_ SG_ 2566868505 HVPowerOnReq_EAS2 "压缩机2（动力电池）上高压请求";
CM_ SG_ 2566868505 HVPowerOnReq_EAS3 "压缩机3（动力电池）上高压请求";
CM_ SG_ 2566868505 HVPowerOnReq_WPTC1 "WPTC1上高压请求";
CM_ SG_ 2566868505 HVPowerOnReq_WPTC2 "WPTC2上高压请求";
CM_ SG_ 2566868505 HVPowerOnReq_WPTC3 "WPTC3上高压请求";
CM_ SG_ 2566868505 HVPowerOnReq_APTC "APTC上高压请求";
CM_ SG_ 2566868505 APTC_PowerCtrl "APTC功率控制请求信号，0-3500W /100";
CM_ SG_ 2566865433 ACTempLevelDispSlpr "卧铺空调用户设定温度显示";
CM_ SG_ 2566865433 ACTempLevelCtrl_Slpr "卧铺空调用户设定温度控制";
CM_ SG_ 2566865433 ACBlowerLevelDisp_Slpr "卧铺空调风量控制档位显示";
CM_ SG_ 2566865433 ACBlowerLevelCtrl_Slpr "卧铺鼓风机挡位控制";
CM_ SG_ 2566865433 ACTimingRunDisp_Slpr "驻车定时通风（卧铺）档位显示";
CM_ SG_ 2566865433 ACOffDisp_Slpr "卧铺空调OFF档位显示OFF控制=OFF即空调开机";
CM_ SG_ 2566865433 ESC_PTC_LowRelayCtrl "电动压缩机、WPTC、APTC低压侧继电器控制Low-voltage relay control";
CM_ SG_ 2566865433 FAN_LowRelayCtrl "低压风扇继电器控制";
CM_ SG_ 2566865433 Blower_RelayCtrl "鼓风机继电器控制";
CM_ SG_ 2566865433 Blower_RelayCtrl_Slpr "后鼓风机继电器控制 L5无B有";
CM_ SG_ 2566865433 BattPump_RelayCtrl "电池水泵继电器";
CM_ SG_ 2566865433 WarmPump_RelayCtrl "采暖水泵继电器 L5无B有";
CM_ SG_ 2566865433 DrivePump_RelayCtrl "电驱动水泵继电器";
CM_ SG_ 2566865433 SOVFront_Ctrl "前空调电磁阀关闭控制 L5&B电磁阀OFF=功能开启（默认常开）";
CM_ SG_ 2566865433 SOVRear_Ctrl "后空调电磁阀关闭控制 B电磁阀OFF=功能开启（默认常开）";
CM_ SG_ 2566865433 Wasteheat_use_2way_SOV "电堆电控开关阀位置控制/电堆余热利用水阀控制";
CM_ SG_ 2566865433 BattPump_PWM "电池水泵功率控制";
CM_ SG_ 2566865433 Temp_Ambt_Accurate "室外温度（计算后使用）";
CM_ SG_ 2566865689 LFAN1_PWM "低压风扇组1调速占空比 L5+Beacon";
CM_ SG_ 2566865689 LFAN2_PWM "低压风扇组2调速占空比  L5无";
CM_ SG_ 2566865689 LFAN3_PWM "低压风扇组3调速占空比 L5无";
CM_ SG_ 2566865689 LFAN4_PWM "低压风扇组4调速占空比 L5无";
CM_ SG_ 2566865689 DrivePump_PWM "电驱动水泵功率控制";
CM_ SG_ 2566865689 WarmPump_PWM "采暖水泵功率控制  L5无";
CM_ SG_ 2566865689 EAC1_ACFrontDefrostSysSts "除霜除雾功能系统状态";
CM_ SG_ 2566865689 EAC2_ACFrontDefrostSysSts "除霜除雾功能系统状态";
CM_ SG_ 2566865689 STValve_Position_Target_ "三通水阀目标位置例如：Byte=EC,对应的十进制为236,电压=236*0.01953=4.6V";
CM_ SG_ 2566867812 EVAP_Temp "蒸发器温度采集信号";
CM_ SG_ 2566867812 EVAP_Temp_Re "后蒸发器温度采集信号";
CM_ SG_ 2566867812 EVAP_Sensor_ERR "蒸发器温度传感器故障";
CM_ SG_ 2566867812 EVAP_Sensor_Rear_ERR "后蒸发器温度传感器故障";
CM_ SG_ 2566867812 Temp_Cabin "室内温度采集信号 温度范围在-40~100";
CM_ SG_ 2566867812 Temp_Cabin_Slpr "后空调室内温度采集信号 温度范围在-40~100";
CM_ SG_ 2566867812 Temp_CabinSensorErr "室内温度传感器故障";
CM_ SG_ 2566867812 Temp_CabinSensorErr_Slpr "后空调室内温度传感器故障";
CM_ SG_ 2566868068 ESC_PTC_LowRelaySts "电动压缩机、WPTC、APTC低压侧继电器状态";
CM_ SG_ 2566868068 FAN_LowRelaySts "低压风扇继电器状态";
CM_ SG_ 2566868068 Blower_RelaySts "鼓风机继电器状态";
CM_ SG_ 2566868068 BlowerRelaySts_Slpr "后鼓风机继电器状态 L5无B有";
CM_ SG_ 2566868068 VIUB_BattPump_RelaySts "电池水泵继电器状态";
CM_ SG_ 2566868068 VIUB_WarmPump_RelaySts "采暖水泵继电器状态 L5无B有";
CM_ SG_ 2566868068 VIUB_DrivePump_RelaySts "电驱动水泵继电器状态";
CM_ SG_ 2566868068 ESC_PTC_LowRelayErr "电动压缩机、WPTC、APTC低压侧继电器故障";
CM_ SG_ 2566868068 FAN_LowRelayErr "低压风扇继电器故障";
CM_ SG_ 2566868068 Blower_RelayErr "鼓风机继电器故障";
CM_ SG_ 2566868068 Blower_RelayErr_Slpr "后鼓风机继电器故障";
CM_ SG_ 2566868068 VIUB_BattPump_RelayErr "电池水泵继电器故障";
CM_ SG_ 2566868068 VIUB_WarmPump_RelayErr "采暖水泵继电器故障 L5无B有";
CM_ SG_ 2566868068 VIUB_DrivePump_RelayErr "电驱动水泵继电器故障";
CM_ SG_ 2566868068 ACModeMotorErr "模式风门电机故障";
CM_ SG_ 2566868068 ACTempMixMotorErr "冷暖风门电机故障";
CM_ SG_ 2566868068 ACBlowerMotorErr "鼓风机电机故障";
CM_ SG_ 2566868068 ACCycleMotorErr "内外循环风门电机故障";
CM_ SG_ 2566868068 ACTempMixMotorErr_Splr "后空调冷暖风门电机故障";
CM_ SG_ 2566868068 ACBlowerMotorErr_Splr "后空调鼓风机电机故障";
CM_ SG_ 2566868068 ACLonizerErr "负离子发生器故障";
CM_ SG_ 2566870884 SunLightSensorErr "阳光强度传感器故障sunlight sensor";
CM_ SG_ 2566870884 TempSnsrErr_BlowFace "前空调吹脸出风温度传感器故障";
CM_ SG_ 2566870884 N_SunLightSensor "阳光强度信号 取值范围在0~1000之间";
CM_ SG_ 2566870884 TempBlowFaceOutlet "前空调吹脸出风温度采集  -40 85 0,5";
CM_ SG_ 2566870884 TempBlowFootOutlet "前空调吹脚出风温度采集  -40 85 0,5";
CM_ SG_ 2566870884 Temp_SplrOutlet "后空调出风温度采集  -40 85 0,5";
CM_ SG_ 2566870884 TempSnsrErr__BlowFoot "前空调吹脚出风温度传感器故障";
CM_ SG_ 2566870884 TempSnsrErr_SplrOutlet "后空调出风温度传感器故障";
CM_ SG_ 2566871140 Pressure_PT2 "冷媒侧低压PT2Beacon-后蒸压力";
CM_ SG_ 2566871140 Temp_PT2 "冷媒侧低压PT2Beacon-后蒸温度";
CM_ SG_ 2566871140 Pressure_PT3 "冷媒侧低压PT3压缩机进口 Chiller1-L5，前蒸压力信号_Beacon";
CM_ SG_ 2566871140 Temp_PT3 "冷媒侧低压PT3压缩机进口 Chiller1-L5，前蒸温度信号_Beacon";
CM_ SG_ 2566871140 PT2SensorErr "冷媒侧低压PT2传感器故障状态";
CM_ SG_ 2566871140 PT3SensorErr "冷媒侧低压PT3传感器故障状态";
CM_ SG_ 2566909028 ACTempMixMotorSts_1 "冷暖风门电机驱动信号状态 电压 0-12V 正反转";
CM_ SG_ 2566909028 ACTempMixMotorFeedback "冷暖风门电机驱动信号状态反馈 电压 0-5V 0.1";
CM_ SG_ 2566909028 ACModeMotorSts_1 "模式风门电机驱动信号状态 电压 0-12";
CM_ SG_ 2566909028 ACModeMotorFeedback "模式风门电机驱动信号状态反馈。 电压 0-5V 0.1";
CM_ SG_ 2566909028 ACBlowerMotorSts "鼓风机驱动信号状态 电压 0-5V 0.1";
CM_ SG_ 2566909028 ACAirPurgeOutputSts "空气净化器驱动信号状态";
CM_ SG_ 2566909028 ACBlowerMotorFeedback "鼓风机驱动信号状态反馈。 电压 0-5V 0.1";
CM_ SG_ 2566909028 ACLonizerOutputFeedback "负离子发生器驱动信号状态反馈";
CM_ SG_ 2566909028 ACBlowerMotorPWM "鼓风机驱动功率";
CM_ SG_ 2566909028 ACAirPurgeOutputFeedback "空气净化器驱动信号状态反馈";
CM_ SG_ 2566909028 ACLonizerOutputSts "负离子发生器驱动信号状态";
CM_ SG_ 2566908772 ACCycleMotorSts_2 "内外循环风门电机驱动信号状态 0-12V 正反转";
CM_ SG_ 2566908772 ACCycleMotorFeedback "内外循环风门电机驱动反馈 电压 0-5V 0.1";
CM_ SG_ 2566908772 ACTempMixMotorSts_Splr_2 "后空调冷暖风门电机驱动信号状态  电压 0-12V 正反转";
CM_ SG_ 2566908772 ACTempMixMotorFeedback_Splr "后空调冷暖风门电机驱动信号状态反馈 电压 0-5V 0.1";
CM_ SG_ 2566908772 ACBlowerMotorSts_Splr "后空调鼓风机驱动信号状态  电压 0-5V 0.1";
CM_ SG_ 2566908772 ACBlowerMotorFeedback_Splr "后空调鼓风机驱动反馈  电压 0-5V 0.1";
CM_ SG_ 2566908772 ACBlowerMotorPWM_Splr "后空调鼓风机驱动功率";
CM_ SG_ 2566866021 LFAN1_Err "低压冷却风扇1故障";
CM_ SG_ 2566866021 DrivePumpErr "电驱动水泵故障状态";
CM_ SG_ 2566866021 BattPumpErr "电池水泵故障状态";
CM_ SG_ 2566866021 LFAN1_PWMSts "低压风扇组1调速信号状态";
CM_ SG_ 2566866021 DrivePump_PWMSts "电驱动水泵驱动信号状态";
CM_ SG_ 2566866021 BattPump_PWMSts "电池水泵驱动信号状态";
CM_ SG_ 2566866021 WasteHeatReusedErr "氢堆余热利用水阀故障";
CM_ SG_ 2566866021 WasteHeatReusedSts "氢堆余热利用水阀状态";
CM_ SG_ 2566867557 LFAN2_PWMSts "低压风扇组2调速信号状态";
CM_ SG_ 2566867557 LFAN3_PWMSts "低压风扇组3调速信号状态";
CM_ SG_ 2566867557 LFAN4_PWMSts "低压风扇组4调速信号状态";
CM_ SG_ 2566867557 LFAN2_Err "低压风扇组2故障";
CM_ SG_ 2566867557 LFAN3_Err "低压风扇组3故障";
CM_ SG_ 2566867557 LFAN4_Err "低压风扇组4故障";
CM_ SG_ 2566867557 WarmPump_PWMSts "采暖水泵驱动信号状态";
CM_ SG_ 2566867557 WarmPumpErr "采暖水泵故障状态";
CM_ SG_ 2566871397 Temp_Ambt "室外传感器采集温度ambient  temperature 滤波值 -40~85 0.5";
CM_ SG_ 2566871397 TempAmbtErr "室外温度传感器故障";
CM_ SG_ 2566871397 TempSensorErr_Batt1Inlet "电池入水口温度传感器故障 L5&B";
CM_ SG_ 2566871397 TempSensorErr_MotorIntlet "电机入水口水温温度传感器故障 L5&B";
CM_ SG_ 2566871397 Temp_Batt1WaterInlet "电池入水口温度 温度范围在-40~180之间 L5&B";
CM_ SG_ 2566871397 Temp_MotorWaterINlet "电机入水口水温信号 L5&B";
CM_ SG_ 2566871397 Temp_BattChiller1WaterOutlet "chiller1支路出水温度 温度范围在-40~180之间 B";
CM_ SG_ 2566871397 Temp_BattChiller2WaterOutlet "chiller2支路出水温度 温度范围在-40~180之间 B";
CM_ SG_ 2566871397 TempSensorErr_BattChiller1Outlet "chiller1支路出水温度传感器故障 B";
CM_ SG_ 2566871397 TempSensorErr_BattChiller2Outlet "chiller2支路出水温度传感器故障 B";
CM_ SG_ 2566871653 Temp_PT1 "冷媒侧低压PT1-chiller1温度-40~180";
CM_ SG_ 2566871653 Pressure_PT1 "冷媒侧低压PT1-chiller1压力 压力范围在0~4000之间";
CM_ SG_ 2566871653 Temp_PT4 "冷媒侧低压PT4-chiller1温度-40~180";
CM_ SG_ 2566871653 Pressure_PT4 "冷媒侧低压PT4-chiller1压力 压力范围在0~4000之间";
CM_ SG_ 2566871653 PT1SensorErr "冷媒侧低压PT1传感器故障状态";
CM_ SG_ 2566871653 PT4SensorErr "冷媒侧低压PT4传感器故障状态";
CM_ SG_ 2566871909 MidPressure1Sts "压力开关1中压压力开关状态 B";
CM_ SG_ 2566871909 HighPressure1Sts "压力开关1高低压压力开关状态B";
CM_ SG_ 2566871909 MidPressure2Sts "压力开关2中压压力开关状态B";
CM_ SG_ 2566871909 HighPressure2Sts "压力开关2高低压压力开关状态B";
CM_ SG_ 2566871909 MidPressure3Sts "压力开关3中压压力开关状态B";
CM_ SG_ 2566871909 HighPressure3Sts "压力开关3高低压压力开关状态B";
CM_ SG_ 2566871909 HighPressure1Err "压力开关1故障信号";
CM_ SG_ 2566871909 HighPressure2Err "压力开关2故障信号";
CM_ SG_ 2566871909 HighPressure3Err "压力开关3故障信号";
CM_ SG_ 2566871909 LevelSwt1Cmd "液位开关1 暖风回路液位 BOpen-仪表点灯";
CM_ SG_ 2566871909 LevelSwt2Cmd "液位开关2  电池回路液位L5&BOpen-仪表点灯";
CM_ SG_ 2566871909 LevelSwt3Cmd "液位开关3 电驱动回路液位 L5&BOpen-仪表点灯";
CM_ SG_ 2566871909 LevelSwt4Cmd "液位开关4  电堆回路液位BOpen-仪表点灯";
CM_ SG_ 2566871909 LevelSwt1Err "液位开关1故障";
CM_ SG_ 2566871909 LevelSwt2Err "液位开关2故障";
CM_ SG_ 2566871909 LevelSwt3Err "液位开关3故障";
CM_ SG_ 2566871909 LevelSwt4Err "液位开关4故障";
CM_ SG_ 2566871909 BattPump_Err "电池水泵驱动故障反馈";
CM_ SG_ 2566871909 MotorPump_Err "电机水泵驱动故障反馈";
CM_ SG_ 2566871909 xxxPump_Err "采暖水泵驱动故障反馈 B";
CM_ SG_ 2566871909 VIUC_BattPump_RelaySts "电池水泵继电器状态";
CM_ SG_ 2566871909 VIUC_WarmPump_RelaySts "采暖水泵继电器状态 L5无B有";
CM_ SG_ 2566871909 VIUC_DrivePump_RelaySts "电驱动水泵继电器状态";
CM_ SG_ 2566871909 VIUC_BattPump_RelayErr "电池水泵继电器故障";
CM_ SG_ 2566871909 VIUC_WarmPump_RelayErr "采暖水泵继电器故障 L5无B有";
CM_ SG_ 2566871909 VIUC_DrivePump_RelayErr "电驱动水泵继电器故障";
CM_ SG_ 2566907943 ValidDKM "蓝牙钥匙有效判断";
CM_ SG_ 2566858223 VBUS_VCU7_BiOBC_HVIL_Err "车内取电逆变器互锁故障";
CM_ SG_ 2566858223 VBUS_VCU7_HVAccS_HVIL_Err "高压附件互锁故障";
CM_ SG_ 2566858223 VBUS_VCU7_Gear1_Indicator "车速过高，已启用N挡，请重新挂挡";
CM_ SG_ 2566858223 VBUS_VCU7_BRAKE_ENGERY_RECOV_LEVEL "制动能量回收挡位";
CM_ SG_ 2566858223 VBUS_VCU7_Restricted_Warning "远程锁车状态提示";
CM_ SG_ 2566858223 VBUS_VCU7_St_LV_Chrg "低压蓄电池补电状态";
CM_ SG_ 2566858223 VBUS_VCU7_IMCUO_422_ready "转向DCAC使能状态（对VCU使能的反馈）";
CM_ SG_ 2566858223 VBUS_VCU7_MTCU_HVIL_Err "MTCU互锁故障";
CM_ SG_ 2566858223 VBUS_VCU7_PDU_HVIL_Err "PDU互锁故障";
CM_ SG_ 2566858223 VBUS_VCU7_BATT_HVIL_Err "动力电池系统互锁故障";
CM_ SG_ 2566858223 VBUS_VCU7_FUELCELL_HVIL_Err "燃料电池系统互锁故障";
CM_ SG_ 2566858223 VBUS_VCU7_ADCAC_BRAKE_EN_CMD "制动DCAC使能命令";
CM_ SG_ 2566858223 VBUS_VCU7_IMCUA_420_ready "制动DCAC使能状态（对VCU使能的反馈）";
CM_ SG_ 2566858223 VBUS_VCU7_FAULT_IMCUO "IMCUO系统故障";
CM_ SG_ 2566858223 VBUS_VCU7_N_MaxCellTemperature "电池单体最高温度";
CM_ SG_ 2566858223 VBUS_VCU7_N_MinCellTemperature "电池单体最低温度";
CM_ SG_ 2566853359 VBUS_VCU4_N_VehicleSpeed "实际车速";
CM_ SG_ 2566853359 VBUS_VCU4_N_AverageConsumedPower "平均电耗（100KM）";
CM_ SG_ 2566853359 VBUS_VCU4_St_Gears "档位状态";
CM_ SG_ 2566853359 VBUS_VCU4_St_Ready "ready信号";
CM_ SG_ 2566853359 VBUS_VCU4_St_Vehicle "整车状态";
CM_ SG_ 2566853359 VBUS_VCU4_St_Interlocking "互锁状态";
CM_ SG_ 2566853359 VBUS_VCU4_St_ShiftGearBrkOn "换挡请踩制动";
CM_ SG_ 2566853359 VBUS_VCU4_F_ShiftGears "换挡不成功状态提示";
CM_ SG_ 2566853359 VBUS_VCU4_F_Motor "电机故障";
CM_ SG_ 2566853359 VBUS_VCU4_F_MotorOverTemp "电机过热报警";
CM_ SG_ 2566853359 VBUS_VCU4_St_DISCHARGE_STA "车辆放电状态";
CM_ SG_ 2566853359 VBUS_VCU4_N_EVRemainDriverRange "纯电剩余可行驶里程";
CM_ SG_ 2566853359 VBUS_VCU4_St_BrakeSta "制动踏板状态";
CM_ SG_ 2566853359 VBUS_VCU4_St_Thermal_runaway "动力电池热失控预警";
CM_ SG_ 2566853359 VBUS_VCU4_RollingCounter "VCU计数器I";
CM_ SG_ 2566873957 TurnLightSts_LR "左后转向灯状态";
CM_ SG_ 2566873957 TurnLightFltMode_LR "左后转向灯故障模式";
CM_ SG_ 2566873957 TurnLightSts_RR "右后转向灯状态";
CM_ SG_ 2566873957 TurnLightFltMode_RR "右后转向灯故障模式";
CM_ SG_ 2566873957 MainReverseLampSts "主车倒车灯状态";
CM_ SG_ 2566873957 TrailerReverseLampSts "挂车倒车灯状态";
CM_ SG_ 2566873957 MainReverseLampFltMode "主车倒车灯故障模式";
CM_ SG_ 2566873957 TrailerReverseLampFltMode "挂车倒车灯故障模式";
CM_ SG_ 2566873957 TrailerSts "挂车状态反馈";
CM_ SG_ 2566873957 RearPositionLightSts_L "左后位置灯驱动状态";
CM_ SG_ 2566873957 RearPositionLighFltMode_L "左后位置灯故障模式";
CM_ SG_ 2566873957 RearPositionLightSts_R "右后位置灯驱动状态";
CM_ SG_ 2566873957 RearPositionLighFltMode_R "右后位置灯故障模式";
CM_ SG_ 2566873957 RearHeadlightSts "后照灯驱动状态";
CM_ SG_ 2566873957 RearHeadlightFltMode "后照灯故障模式";
CM_ SG_ 2566873957 TrailerABSAlarm "挂车ABS报警灯";
CM_ SG_ 2566873957 TurnLightSts_TL "挂车左转向灯状态";
CM_ SG_ 2566873957 TurnLightFltMode_TL "挂车左转向灯故障模式";
CM_ SG_ 2566873957 TurnLightSts_TR "挂车右转向灯状态";
CM_ SG_ 2566873957 TurnLightFltMode_TR "挂车右转向灯故障模式";
CM_ SG_ 2566873957 RearPositionLightSts_TL "挂车左位置灯驱动状态";
CM_ SG_ 2566873957 RearPositionLightSts_TR "挂车右位置灯驱动状态";
CM_ SG_ 2566859824 Force_Reblow_Mode "下电再生模式";
CM_ SG_ 2566859824 Intelgent_AirSuply_Mode "智能供气模式";
CM_ SG_ 2566859824 Exhaust_RelayEnable "排气阀使能";
CM_ SG_ 2566859824 Reblow_RelayEnable "反吹阀使能";
CM_ SG_ 2566859824 Air_Susp_Set "空气悬挂配置";
CM_ SG_ 2566859824 Air_Susp_Mode "空气悬挂模式";
CM_ SG_ 2566859824 Heat_RelayEnable "加热继电器闭合";
CM_ SG_ 2566859824 LowTemp_Protect_Set "低温保护设置";
CM_ SG_ 2566859824 LowTemp_Protect_Mode "低温保护模式";
CM_ SG_ 2566859824 Invalid_Mode "无效模式";
CM_ SG_ 2566859824 Error_Level "故障等级";
CM_ SG_ 2566859824 Normal_Err "一般故障";
CM_ SG_ 2566859824 Serious_Err "严重故障";
CM_ SG_ 2566859824 DryTank_ChangedRemind "干燥罐更换提醒";
CM_ SG_ 2566859824 DryTank_Remain_Time "干燥管剩余使用时间";
CM_ SG_ 2566859824 DryTank_Remain_Mileage "干燥罐剩余使用里程";
CM_ SG_ 2566860080 OneCycle_DriedAir "单次循环干燥气量";
CM_ SG_ 2566860080 OneCycle_BlowAir "单次循环再生气量";
CM_ SG_ 2566860080 AllWait_Reblow_Air "总待在生气量";
CM_ SG_ 2566860080 APU_SoftWare_Ver "APU软件版本号";
CM_ SG_ 2566893413 VIUC_ACFrontDefrostSysSts "除霜除雾功能系统状态包括传感器导致的潜伏故障信号和单点故障信号;";
CM_ SG_ 2566860336 AirComp_WorkingLoad_OneStart "一次点火，空压机负载";
CM_ SG_ 2566860336 AirComp_WrkLoad_OneCycle "一次工作循环空压机负载";
CM_ SG_ 2566860336 AllAir_Dried "干燥剂干燥总气量";
CM_ SG_ 2566903909 BrkliningWearAlrm_FLW "磨损量报警信号（一轴左）";
CM_ SG_ 2566903909 BrkliningWearAlrm_FRW "磨损量报警信号（一轴右）";
CM_ SG_ 2566903909 BrkliningWearAlrm_MLW "磨损量报警信号（二轴左）";
CM_ SG_ 2566903909 BrkliningWearAlrm_MRW "磨损量报警信号（二轴右）";
CM_ SG_ 2566903909 BrkliningWearAlrm_RLW "磨损量报警信号（三轴左）";
CM_ SG_ 2566903909 BrkliningWearAlrm_RRW "磨损量报警信号（三轴右）";
CM_ SG_ 2566903909 Brkliningremaining_FLW "一轴左轮剩余磨损量";
CM_ SG_ 2566903909 Brkliningremaining_FRW "一轴右轮剩余磨损量";
CM_ SG_ 2566903909 Brkliningremaining_MLW "二轴左轮剩余磨损量";
CM_ SG_ 2566903909 Brkliningremaining_MRW "二轴右轮剩余磨损量";
CM_ SG_ 2566903909 Brkliningremaining_RLW "三轴左轮剩余磨损量";
CM_ SG_ 2566903909 Brkliningremaining_RRW "三轴右轮剩余磨损量";
CM_ SG_ 2566903653 Front_AirPrs_Alarm "前桥气压报警";
CM_ SG_ 2566903653 Rear_AirPrs_Alarm "后桥气压报警";
CM_ SG_ 2566903653 ParkBreakPressureAlarm "驻车气路气压低报警";
CM_ SG_ 2566903653 AirFilterBlocking "空滤堵塞状态";
CM_ SG_ 2566903653 AirFilterBlockageAlarm "空滤堵塞报警信号";
CM_ SG_ 2566903653 BrkliningTempAlarm_FLW "一轴左轮蹄片温度报警信号";
CM_ SG_ 2566903653 BrkliningTempAlarm_FRW "一轴右轮蹄片温度报警信号";
CM_ SG_ 2566903653 Braketemperature_MLW "二轴左轮蹄片温度报警信号";
CM_ SG_ 2566903653 Braketemperature_MRW "二轴右轮蹄片温度报警信号";
CM_ SG_ 2566903653 Braketemperature_RLW "三轴左轮蹄片温度报警信号";
CM_ SG_ 2566903653 Braketemperature_RRW "三轴右轮蹄片温度报警信号";
CM_ SG_ 2566893351 LowBeamFltWarn_VDCU "近光灯故障提醒";
CM_ SG_ 2566893351 MainBrkLightFltWarn_VDCU "主车制动灯故障提醒";
CM_ SG_ 2566893351 TrailerBrkLightFltWarn_VDCU "挂车制动灯故障提醒";
CM_ SG_ 2566893351 HighBeamFltWarn_VDCU "远光灯故障提醒";
CM_ SG_ 2566893351 OvertakinglampWarn_VDCU "超车灯故障提醒";
CM_ SG_ 2566893351 FrontOperatorWiperFltWarn_VDCU "雨刮故障提醒";
CM_ SG_ 2566893351 WinCtrlFlt_Drvr_VDCU "主驾侧车窗故障提醒";
CM_ SG_ 2566893351 WinCtrlFlt_Pass_VDCU "副驾侧车窗故障提醒";
CM_ SG_ 2566893351 VDCU_ACFrontDefrostSysSts "除霜除雾功能系统状态包括控制策略引发的潜伏故障信号和单点故障信号;";
CM_ SG_ 2566893351 LowPowerModeWarn_VDCU "低压电源档位故障";
CM_ SG_ 2365522727 CertificationSts_VDCU "加密状态";
CM_ SG_ 2365522727 RandomData1_VDCU "随机数1";
CM_ SG_ 2365522727 RandomData2_VDCU "随机数2";
CM_ SG_ 2365522727 RandomData3_VDCU "随机数3";
CM_ SG_ 2365522727 RandomData4_VDCU "随机数4";
CM_ SG_ 2365522727 RandomData5_VDCU "随机数5";
CM_ SG_ 2365522727 RandomData6_VDCU "随机数6";
CM_ SG_ 2365522727 RandomData7_VDCU "随机数7";
CM_ SG_ 2365522727 RandomData8_VDCU "随机数8";
CM_ SG_ 2365522727 RandomData9_VDCU "随机数9";
CM_ SG_ 2365522727 RandomData10_VDCU "随机数10";
CM_ SG_ 2365522727 RandomData11_VDCU "随机数11";
CM_ SG_ 2365522727 RandomData12_VDCU "随机数12";
CM_ SG_ 2365522727 RandomData13_VDCU "随机数13";
CM_ SG_ 2365522727 RandomData14_VDCU "随机数14";
CM_ SG_ 2365522727 RandomData15_VDCU "随机数15";
CM_ SG_ 2365522727 RandomData16_VDCU "随机数16";
CM_ SG_ 2566861351 LeftTurnLightReq "左转向灯驱动请求";
CM_ SG_ 2566861351 RightTurnLightReq "右转向灯驱动请求";
CM_ SG_ 2566861351 HzrdLightReq "危报灯驱动请求";
CM_ SG_ 2566861351 LowBeamReq "近光灯控制请求";
CM_ SG_ 2566861351 HighBeamReq "远光灯控制请求";
CM_ SG_ 2566861351 ReverseLampReq "倒车灯控制请求";
CM_ SG_ 2566861351 MainBrkLightReq "主车制动灯驱动请求";
CM_ SG_ 2566861351 TrailerBrkLightReq "挂车制动灯驱动请求";
CM_ SG_ 2566861351 PosnLigjtReq "位置灯控制请求";
CM_ SG_ 2566861351 BacklightAdjustReq "背光亮度调节请求";
CM_ SG_ 2566861351 LeftDayTimeRunngLiReq "左昼行灯驱动请求";
CM_ SG_ 2566861351 RightDayTimeRunngLiReq "右昼行灯驱动请求";
CM_ SG_ 2566861351 RearFogLampReq "后雾灯控制请求";
CM_ SG_ 2566861351 RearFogLampReplcmtReq "后雾灯代替制动灯请求";
CM_ SG_ 2566861351 LanternLanguageReq "灯语请求";
CM_ SG_ 2566861351 IVI_FrontFogLampLinkageSetFB "前雾灯随后雾灯联动设置反馈";
CM_ SG_ 2566861351 LampFollowMeHomeSetSts "伴我回家功能设置成功状态反馈";
CM_ SG_ 2566861351 LampAwayHomeSetSts "照我离家功能设置成功反馈";
CM_ SG_ 2566861351 ExtrMirrHeatCtrl "后视镜加热控制";
CM_ SG_ 2566861351 ExtrMirrDirAdjmtCtrl_L "左侧后视镜视野调节控制";
CM_ SG_ 2566861351 ExtrMirrDirAdjmtCtrl_R "右侧后视镜视野调节控制";
CM_ SG_ 2566861351 FrontFogLampReq_L "左前雾灯控制请求";
CM_ SG_ 2566861351 FrontFogLampReq_R "右前雾灯控制请求";
CM_ SG_ 2566861607 WinReq_L "主驾车窗升降控制请求";
CM_ SG_ 2566861607 WinReq_R "副驾车窗升降控制请求";
CM_ SG_ 2566861607 WasherReq "喷淋电机驱动请求";
CM_ SG_ 2566861607 WiperReq "雨刮驱动请求";
CM_ SG_ 2566861607 OutIncrWinAntAlarm "外部升窗防夹报警";
CM_ SG_ 2566861607 StartStopButtonLiReq "一键启动开关指示灯驱动命令";
CM_ SG_ 2566861607 RelayReq_ACC "ACC继电器吸合命令";
CM_ SG_ 2566861607 RelayReq_IG1 "IG1继电器吸合命令";
CM_ SG_ 2566861607 RelayReq_IG2 "IG2继电器吸合命令";
CM_ SG_ 2566861607 CrankReq "Crank命令";
CM_ SG_ 2566861607 RelaySts_ACC "ACC继电器状态";
CM_ SG_ 2566861607 RelaySts_IG1 "IG1继电器状态";
CM_ SG_ 2566861607 RelaySts_IG2 "IG2继电器状态";
CM_ SG_ 2566861607 LowPowerMode "低压电源状态";
CM_ SG_ 2566861607 RmtLowPowerMode "低压电源远控标志位";
CM_ SG_ 2566861607 RainCloseWinSwt_Fb "雨天自动关窗设置反馈";
CM_ SG_ 2566861607 RmtLocaloutreq_VDCU "本地事件触发退出远控请求(VDCU)";
CM_ SG_ 2566861607 BluetoothKeyConnect "蓝牙钥匙是否连接";
CM_ SG_ 2566861607 BluetoothKeyLocation "蓝牙钥匙位置";
CM_ SG_ 2566861607 BluetoothKeyReq "蓝牙钥匙请求";
CM_ SG_ 2566861607 BluetoothPhoneConnect "手机蓝牙是否连接";
CM_ SG_ 2566861607 PrimaryAntennaSleepSts "主天线休眠指令";
CM_ SG_ 2566907443 Wheel_Location_ID "轮胎位置编码";
CM_ SG_ 2566907443 Tyre_Temperature "轮胎温度";
CM_ SG_ 2566907443 Tyre_Pressure "轮胎压力";
CM_ SG_ 2566907443 WU_Battery_Status "传感器电池电量";
CM_ SG_ 2566907443 Tyre_LearnStatus "轮胎状态自学习";
CM_ SG_ 2566907443 Tyre_SensorLose_warning "传感器信号丢失报警";
CM_ SG_ 2566907443 Tyre_Learn "学习类型";
CM_ SG_ 2566907443 Tyre_SensorLowBatt_warning "传感器电量不足报警";
CM_ SG_ 2566907443 Tyre_Pressure_Status "轮胎压力状态";
CM_ SG_ 2566907443 Tyre_Over_Temp_Status "高温状态";
CM_ SG_ 2566907443 Sensor_ID_Prog_Status "传感器ID写入状态";
CM_ SG_ 2566907955 MLS_Page "手动学习状态页";
CM_ SG_ 2566907955 MLS_truck_trailer "卡车/挂车标志位(声明该报文与牵引车相关还是和挂车相关当MLS Page = 0时)";
CM_ SG_ 2566907955 MLS "手动学习状态";
CM_ SG_ 2566907955 MLS_Tyre_Loc "所学习的轮胎位置";
CM_ SG_ 2348876549 TransmissionRequestedGear "Indicates the gear requested by the operator(有效值发5帧）";
CM_ SG_ 2348876549 AssistedbrakingSwt "辅助制动挡位";
CM_ SG_ 2348876549 TransmissionRequestedGearflag "档位有效标志位";
CM_ SG_ 2566893317 HighBeamFltWarn_GSM "远光灯故障提醒";
CM_ SG_ 2566893317 OvertakinglampWarn_GSM "超车灯故障提醒";
CM_ SG_ 2566893317 FrontOperatorWiperFltWarn_GSM "雨刮故障提醒";
CM_ SG_ 2566893317 ShiftFltWarn_GSM "档位故障提醒";
CM_ SG_ 2365443105 TurnSignalSwt "转向灯开关（小于700ms为变道）";
CM_ SG_ 2365443105 HighBeamSwt "远光开关";
CM_ SG_ 2365443105 OvertakinglampSwt "超车开关";
CM_ SG_ 2566769953 FrontOperatorWiperSwt "雨刮档位开关状态";
CM_ SG_ 2566769953 WiprSensitivitySwt "雨刮灵敏度开关状态";
CM_ SG_ 2566769953 FrontOperatorWasherSwt "洗涤开关状态";
CM_ SG_ 2566759916 LockStatusofDoor_L "左侧门锁开闭状态";
CM_ SG_ 2566759916 OpenStatusofDoor_L "左侧车门开闭状态";
CM_ SG_ 2566759916 EnableStatusofDoor_L "左自动门状态";
CM_ SG_ 2566759916 LeftDoorFltWarn "左自动门故障提醒";
CM_ SG_ 2566759917 LockStatusofDoor_R "右侧门锁开闭状态";
CM_ SG_ 2566759917 OpenStatusofDoor_R "右侧车门开闭状态";
CM_ SG_ 2566759917 EnableStatusofDoor_R "右自动门状态";
CM_ SG_ 2566759917 RightDoorFltWarn "右自动门故障提醒";
CM_ SG_ 2566759780 LockStatusofDoor_FD "主驾门锁开闭状态";
CM_ SG_ 2566759780 OpenStatusofDoor_FD "主驾车门开闭状态";
CM_ SG_ 2566759780 EnableStatusofDoor_FD "主驾自动门状态";
CM_ SG_ 2566759780 LockStatusofDoor_FP "副驾门锁开闭状态";
CM_ SG_ 2566759780 OpenStatusofDoor_FP "副驾车门开闭状态";
CM_ SG_ 2566759780 EnableStatusofDoor_FP "副驾自动门状态";
CM_ SG_ 2566759780 LockStatusofDoor_RL "左后门锁开闭状态";
CM_ SG_ 2566759780 OpenStatusofDoor_RL "左后车门开闭状态";
CM_ SG_ 2566759780 EnableStatusofDoor_RL "左后自动门状态";
CM_ SG_ 2566759780 LockStatusofDoor_RR "右后门锁开闭状态";
CM_ SG_ 2566759780 OpenStatusofDoor_RR "右后车门开闭状态";
CM_ SG_ 2566759780 EnableStatusofDoor_RR "右后自动门状态";
CM_ SG_ 2566874468 RearviewHeatSts "后视镜加热状态";
CM_ SG_ 2566874468 RearviewHeatRelayFlt "后视镜加热继电器故障状态";
CM_ SG_ 2566874468 BacklightAdjustSts "背光亮度执行状态";
CM_ SG_ 2566874468 UnlockTypeSetFb "解锁类型设置状态反馈";
CM_ SG_ 2566874468 PwroffAutoUnlockSetFb "熄火解锁设置状态反馈";
CM_ SG_ 2566874468 SpdLockSetFb "车速锁设置状态反馈";
CM_ SG_ 2566874468 ExternalKeySts "低频钥匙状态";
CM_ SG_ 2566874468 LockPromptSetSts "闭锁提示设置状态反馈";
CM_ SG_ 2566874468 SearchingCarPromptSetSts "寻车提示设置状态反馈";
CM_ SG_ 2566874468 KeyNotDetectedWarn "未检测到（低频+蓝牙）钥匙提醒";
CM_ SG_ 2566874468 LowBatteryWarn "电池电量低提醒";
CM_ SG_ 2566874468 KeyPutAntennaWarn "请把低频钥匙放在备用天线上提醒";
CM_ SG_ 2566874468 PEPSFaultWarn "PEPS系统异常";
CM_ SG_ 2566874468 KeyInCarOpenWhenExitWarn "（低频+蓝牙）钥匙离车提醒";
CM_ SG_ 2566874468 PowerSwt_220V "220V取电开关";
CM_ SG_ 2566874468 StartStopButtonSts "一键启动开关状态";
CM_ SG_ 2566874468 EmgyShutdownReq "紧急熄火请求（2S内3次开关工作）";
CM_ SG_ 2566874468 KeySearchLFReq "查找（低频+蓝牙）钥匙请求";
CM_ SG_ 2566874468 LFAntennaFlt "低频天线故障信息";
CM_ SG_ 2566874468 StartConditionMet "满足启动条件";
CM_ SG_ 2566874468 KeyAuthenticationSts "低频钥匙防盗认证";
CM_ SG_ 2566874468 KeyNumber "低频钥匙号码信息输出";
CM_ SG_ 2566874468 KeyPosition "低频钥匙位置";
CM_ SG_ 2566874468 ExtrMirrSelectSts "后视镜调节选择状态反馈";
CM_ SG_ 2566874468 AutoLampReq "硬线光照传感器自动大灯开闭请求(低电平Off，高电平ON）";
CM_ SG_ 2566874724 ElectricHornRelaySts "电喇叭继电器状态";
CM_ SG_ 2566874724 AirHornRelaySts "气喇叭继电器状态";
CM_ SG_ 2566874724 HornSwt "喇叭开关状态";
CM_ SG_ 2566874724 CabAntitheftSts "车身防盗状态（周期发送）";
CM_ SG_ 2566874724 LockElectricHornReq "闭锁电喇叭请求（有效值发3帧）";
CM_ SG_ 2566874724 SearchingCarElectricHorReq "寻车电喇叭请求（有效值发3帧）";
CM_ SG_ 2566874724 WiperParkSwt "雨刮停止位开关状态";
CM_ SG_ 2566874724 WiperSts "雨刮驱动状态反馈";
CM_ SG_ 2566874724 WasherSts "雨刮喷淋状态反馈";
CM_ SG_ 2566874724 WiperMotorFlt "雨刮电机故障";
CM_ SG_ 2566874724 WasherMotorFlt "喷淋电机故障";
CM_ SG_ 2566874724 HazardSwitch "危报灯开关状态";
CM_ SG_ 2566874724 TurnLightSts_LM "左中转向灯状态";
CM_ SG_ 2566874724 TurnLightSts_RM "右中转向灯状态";
CM_ SG_ 2566874724 TurnLightFlt_LM "左中转向灯故障模式";
CM_ SG_ 2566874724 TurnLightFlt_RM "右中转向灯故障模式";
CM_ SG_ 2566874724 AutoLampSwt "自动大灯开关状态";
CM_ SG_ 2566874724 PsnLampSwt "位置灯开关状态";
CM_ SG_ 2566874724 LowBeamSwt "近光灯开关状态";
CM_ SG_ 2566874724 LeftLowBeamSts "左近光灯状态";
CM_ SG_ 2566874724 LeftLowBeamFlt "左近光灯故障模式";
CM_ SG_ 2566874724 RightLowBeamSts "右近光灯状态";
CM_ SG_ 2566874724 RightLowBeamFlt "右近光灯故障模式";
CM_ SG_ 2566874724 HighBeamSts "远光灯状态";
CM_ SG_ 2566874724 HighBeamFlt "远光灯故障模式";
CM_ SG_ 2566874724 PositionLightSts_L "左(侧)位置灯驱动状态";
CM_ SG_ 2566874724 PositionLightFlt_L "左(侧)位置灯故障模式";
CM_ SG_ 2566874724 PositionLightSts_R "右(侧)位置灯驱动状态";
CM_ SG_ 2566874724 PositionLightFlt_R "右(侧)位置灯故障模式";
CM_ SG_ 2566874724 RearFogLightSwt "后雾灯开关状态";
CM_ SG_ 2566874724 FrontFogLightSwt "前雾灯开关状态";
CM_ SG_ 2566874724 Electric_AirHornSetSts "电/气喇叭设置状态";
CM_ SG_ 2566874724 ElectricHornReq "电喇叭驱动请求";
CM_ SG_ 2566874724 AirHornReq "气喇叭驱动请求";
CM_ SG_ 2566874724 FrontFogLightSts_L "左前雾灯驱动状态";
CM_ SG_ 2566874724 FrontFogLightFltMode_L "左前雾灯故障模式";
CM_ SG_ 2566874724 FrontFogLightSts_R "右前雾灯驱动状态";
CM_ SG_ 2566874724 FrontFogLightFltMode_R "右前雾灯故障模式";
CM_ SG_ 2566874724 EgySavingPwrSplySts "节能电输出";
CM_ SG_ 2566875236 LockSource_MasterLock "中控解闭锁请求来源";
CM_ SG_ 2566875236 LockSource_SleeperLock "卧铺侧解闭锁请求来源";
CM_ SG_ 2566875236 LockSource_RkeLock "低频钥匙解锁请求来源";
CM_ SG_ 2566875236 LockSource_RemoteLock "远程解闭锁请求来源";
CM_ SG_ 2566875236 LockSource_AutoReLock "自动闭锁回防请求来源";
CM_ SG_ 2566875236 LockSource_PkeLock "PKE解闭锁请求来源";
CM_ SG_ 2566875236 LockSource_CrashLock "碰撞解锁请求来源";
CM_ SG_ 2566875236 LockSource_DKMLock "蓝牙解闭锁请求来源";
CM_ SG_ 2566875236 LockSource_Insd_Outd "车辆内外部解闭锁命令";
CM_ SG_ 2566875236 Lock_Unlock_SucessFb "成功解闭锁";
CM_ SG_ 2566875236 PlayPrevnSts_LPKE_Unlock "主驾解锁PKE防玩模式";
CM_ SG_ 2566875236 PlayPrevnSts_LPKE_Lock "主驾闭锁PKE防玩模式";
CM_ SG_ 2566875236 PlayPrevnSts_RPKE_Unlock "副驾解锁PKE防玩模式";
CM_ SG_ 2566875236 PlayPrevnSts_RPKE_Lock "副驾闭锁PKE防玩模式";
CM_ SG_ 2566875236 CentralLockSw "中控解闭锁开关状态";
CM_ SG_ 2566875236 AutoUnlockReq "熄火解锁请求";
CM_ SG_ 2566875236 SpeedReqLock "车速锁请求闭锁";
CM_ SG_ 2566875236 LockUnlockReq_L "左侧门锁控制请求";
CM_ SG_ 2566875236 LockUnlockReq_R "右侧（及后排）门锁控制请求";
CM_ SG_ 2566875236 LockOverheatProtection_L "主驾门锁电机过热保护";
CM_ SG_ 2566875236 LockOverheatProtection_R "副驾门锁电机过热保护";
CM_ SG_ 2566875236 PlayPrevnSts_LPKE "主驾PKE防玩模式";
CM_ SG_ 2566875236 PlayPrevnSts_RPKE "副驾PKE防玩模式";
CM_ SG_ 2566875236 RearFogLightSts "后雾灯驱动状态";
CM_ SG_ 2566875236 RearFogLightFltMode "后雾灯故障模式";
CM_ SG_ 2566875236 RearFogLightSts_T "挂车后雾灯驱动状态";
CM_ SG_ 2566875236 RearFogLightFltMode_T "挂车后雾灯故障模式";
CM_ SG_ 2566875236 ExtrMirrHozlAdjMotorSts_R "右侧外后视镜左右调节电机故障状态";
CM_ SG_ 2566875236 ExtrMirrVertAdjMotorSts_R "右侧外后视镜上下调节电机故障状态";
CM_ SG_ 2566875236 ExtrMirrHozlAdjMotorSts_L "左侧外后视镜左右调节电机故障状态";
CM_ SG_ 2566875236 ExtrMirrVertAdjMotorSts_L "左侧外后视镜上下调节电机故障状态";
CM_ SG_ 2566875236 MainBrkLightSts "主车制动灯状态";
CM_ SG_ 2566875236 TrailerBrkLightSts "挂车制动灯状态";
CM_ SG_ 2566875236 MainBrkLightFltMode "主车制动灯故障模式";
CM_ SG_ 2566875236 TrailerBrkLightFltMode "挂车制动灯故障模式";
CM_ SG_ 2566893412 LowBeamFltWarn_VIUB "近光灯故障提醒";
CM_ SG_ 2566893412 HighBeamFltWarn_VIUB "远光灯故障提醒";
CM_ SG_ 2566893412 FrontOperatorWiperFltWarn_VIUB "雨刮故障提醒";
CM_ SG_ 2566893412 AntiPinchFlt_Drvr_VIUB "司机侧车窗防夹故障提醒";
CM_ SG_ 2566893412 AntiPinchFlt_Pass_VIUB "副驾侧车窗防夹故障提醒";
CM_ SG_ 2566893412 WinCtrlFlt_Drvr_VIUB "主驾侧车窗故障提醒";
CM_ SG_ 2566893412 WinCtrlFlt_Pass_VIUB "副驾侧车窗故障提醒";
CM_ SG_ 2566893412 VIUB_ACFrontDefrostSysSts "除霜除雾功能系统状态包括传感器导致的潜伏故障信号和单点故障信号;";
CM_ SG_ 2566893412 MainBrkLightFltWarn_VIUC "主车制动灯故障提醒";
CM_ SG_ 2566893412 TrailerBrkLightFltWarn_VIUC "挂车制动灯故障提醒";
CM_ SG_ 2566875492 WinSwt_DrvrsideD "主驾侧主驾车窗开关状态";
CM_ SG_ 2566875492 WinSwt_DrvrsideP "主驾侧副驾车窗开关状态";
CM_ SG_ 2566875492 WinSwt_Pass "副驾侧副驾车窗开关状态";
CM_ SG_ 2566875492 WinSts_Drvr "主驾车窗升降状态";
CM_ SG_ 2566875492 WinSts_Pass "副驾车窗升降状态";
CM_ SG_ 2566875492 WinPsn_Drvr "主驾侧车窗位置";
CM_ SG_ 2566875492 WinPsn_Pass "副驾侧车窗位置";
CM_ SG_ 2566875492 RFReceiver "低频钥匙请求";
CM_ SG_ 2566875492 PEUnlockSwt_L "左侧PE解锁开关状态";
CM_ SG_ 2566875492 PELockSwt_L "左侧PE闭锁开关状态";
CM_ SG_ 2566875492 PEUnlockSwt_R "右侧PE解锁开关状态";
CM_ SG_ 2566875492 PELockSwt_R "右侧PE闭锁开关状态";
CM_ SG_ 2566875492 PESwt_L "左侧PE开关状态";
CM_ SG_ 2566875492 PESwt_R "右侧PE开关信号";
CM_ SG_ 2566875492 ExtrMirrDirAdjOutput_L "左侧外后视镜视野调节电机驱动";
CM_ SG_ 2566875492 ExtrMirrDirAdjOutput_R "右侧外后视镜视野调节电机驱动";
CM_ SG_ 2566875748 WinMotorCurrent_L "主驾侧升降器电流";
CM_ SG_ 2566875748 WinMotorStallStopReq_L "主驾堵转停止请求";
CM_ SG_ 2566875748 WinMotorCurrent_R "副驾侧升降器电流";
CM_ SG_ 2566875748 WinMotorStallStopReq_R "副驾堵转停止请求";
CM_ SG_ 2566875748 WinMotorResistance_L "主驾侧升降器阻力";
CM_ SG_ 2566875748 WinMotorResistance_R "副驾侧升降器阻力";
CM_ SG_ 2566875748 AntiPinchRollbackReq_L "主驾防夹回退请求";
CM_ SG_ 2566875748 AntiPinchRollbackReq_R "副驾防夹回退请求";
CM_ SG_ 2566874980 SeatVibrationSts "座椅震动状态反馈";
CM_ SG_ 2566874980 CentralLockFailFlg "中控闭锁失败标志位";
CM_ SG_ 2566874980 RKELockFailFlg "遥控闭锁失败标志位";
CM_ SG_ 2566874980 PKELockFailFlg "PKE闭锁失败标志位";
CM_ SG_ 2566874980 DKMLockFailFlg "DKM闭锁失败标志位";
CM_ SG_ 2365522788 CertificationSts_VIU "加密状态";
CM_ SG_ 2365522788 CMAC1_VIU "加密数据1";
CM_ SG_ 2365522788 CMAC2_VIU "加密数据2";
CM_ SG_ 2365522788 CMAC3_VIU "加密数据3";
CM_ SG_ 2365522788 CMAC4_VIU "加密数据4";
CM_ SG_ 2365522788 CMAC5_VIU "加密数据5";
CM_ SG_ 2365522788 CMAC6_VIU "加密数据6";
CM_ SG_ 2365522788 CMAC7_VIU "加密数据7";
CM_ SG_ 2365522788 CMAC8_VIU "加密数据8";
CM_ SG_ 2365522788 CMAC9_VIU "加密数据9";
CM_ SG_ 2365522788 CMAC10_VIU "加密数据10";
CM_ SG_ 2365522788 CMAC11_VIU "加密数据11";
CM_ SG_ 2365522788 CMAC12_VIU "加密数据12";
CM_ SG_ 2365522788 CMAC13_VIU "加密数据13";
CM_ SG_ 2365522788 CMAC14_VIU "加密数据14";
CM_ SG_ 2365522788 CMAC15_VIU "加密数据15";
CM_ SG_ 2365522788 CMAC16_VIU "加密数据16";
CM_ SG_ 2566845721 AmbAirT "Temperature of air surrounding vehicle.室外温度 Needed for AVE EP and Cetrax for Rotor-Temperature Derating Function";
CM_ SG_ 2566873629 SGM_S_Unlock_Swt "The Switch of the  Unlock";
CM_ SG_ 2566873629 SGM_S_Lock_Swt "The Switch of the  Lock";
CM_ SG_ 2566873629 SGM_S_WLM_FL_Swt "The Switch of the  window";
CM_ SG_ 2566873629 SGM_S_WLM_FR_Swt "The Switch of the  window";
CM_ SG_ 2566873629 SGM_S_VolumePlus_Swt "The Switch of the  Volume plus";
CM_ SG_ 2566873629 SGM_S_VolumeMinus_Swt "The Switch of the  Volume minus";
CM_ SG_ 2566873629 SGM_S_ACOnOrOff_Swt "The Switch of the  AC on or off";
CM_ SG_ 2566873629 SGM_S_BlowerLvlPlus_Swt "The Switch of the  AC Blowe plus";
CM_ SG_ 2566873629 SGM_S_BlowerLvlMinus_Swt "The Switch of the  AC Blowe minus";
CM_ SG_ 2566873629 SGM_S_ACTempPlus_Swt "The Switch of the  AC Temperature plus";
CM_ SG_ 2566873629 SGM_S_ACTempMinus_Swt "The Switch of the  AC Temperature minus";
CM_ SG_ 2566873629 SGM_S_ACTimingRun_Swt "The Switch of the  AC Timing Run";
CM_ SG_ 2566873629 SGM_S_CMSStart_Swt "The Switch of the  CMS start";
CM_ SG_ 2566873629 SGM_S_F_LINError "This signal shows one or more failures related to LIN communication.";
CM_ SG_ 2365537816 SWS_Mode_Swt "The Switch of the  Mode";
CM_ SG_ 2365537816 SWS_ReturnOrConfirm_Swt "The Switch of return or confirm";
CM_ SG_ 2365537816 SWS_DirectionUp_Swt "The switch of the Direction";
CM_ SG_ 2365537816 SWS_DirectionDown_Swt "The switch of the Direction";
CM_ SG_ 2365537816 SWS_DirectionLeft_Swt "The switch of the Direction";
CM_ SG_ 2365537816 SWS_DirectionRight_Swt "The switch of the Direction";
CM_ SG_ 2365537816 SWS_VROrHangUp_Swt "The switch of the VR Or Hang UP";
CM_ SG_ 2365537816 SWS_MuteOrHangDown_Swt "The switch of the mute Or HangDown";
CM_ SG_ 2365537816 SWS_Userde_Swt "The switch of the user-defined";
CM_ SG_ 2365537816 SWS_ADAS_Swt "(预留)The switch of the ADAS";
CM_ SG_ 2365537816 SWS_SpeedUp_Set "The switch of the CC Speed Set";
CM_ SG_ 2365537816 SWS_SpeedDown_Set "The switch of the CC Speed Set";
CM_ SG_ 2365537816 SWS_TimeGapInc_Set "The switch of the Time Gap Increase";
CM_ SG_ 2365537816 SWS_TimeGapDec_Set "The switch of the Time Gap Decrease";
CM_ SG_ 2365537816 SWS_LKA_Swt "The Switch of lane-keeping assist";
CM_ SG_ 2365537816 SWS_Heating_Swt "The Switch of sws heating";
CM_ SG_ 2566873374 SGM_IP_HornType_Swt "The Switch of the  Horn Type";
CM_ SG_ 2566873374 SGM_IP_RearLight_Swt "The Switch of the  Rear light";
CM_ SG_ 2566873374 SGM_IP_ACOff_Swt "The Switch of the  AC off";
CM_ SG_ 2566873374 SGM_IP_BlowerLvlPlus_Swt "The Switch of the  AC Blowe plus";
CM_ SG_ 2566873374 SGM_IP_BlowerLvlMinus_Swt "The Switch of the  AC Blowe minus";
CM_ SG_ 2566873374 SGM_IP_ACTempPlus_Swt "The Switch of the  AC Temperature plus";
CM_ SG_ 2566873374 SGM_IP_ACTempMinus_Swt "The Switch of the  AC Temperature minus";
CM_ SG_ 2566873374 SGM_IP_ACFrontDefrost_Swt "The Switch of the  AC Front Defrost";
CM_ SG_ 2566873374 SGM_IP_F_LINError "This signal shows one or more failures related to LIN communication.";
CM_ SG_ 2364539904 EngTorqueMode_ "State signal which indicates which engine torque mode is currently generating, limiting, or controlling the torque.发动机扭矩模式";
CM_ SG_ 2364539904 ActlEngPrcntTrqueHighResolution_ "This parameter displays an additional torque in percent of the reference engine torque.(实际扭矩百分比小数部分)";
CM_ SG_ 2364539904 DriversDemandEngPercentTorque "The requested torque output of the engine by the driver.驾驶指令扭矩百分比";
CM_ SG_ 2364539904 ActualEngPercentTorque_CF00400 "The calculated output torque of the engine.发动机实际扭矩百分比";
CM_ SG_ 2364539904 EngSpeed "Actual engine speed which is calculated over a minimum crankshaft angle of 720 degrees divided by the number of cylinders.Invalid Value: 0xFB00~ALLFF发动机转速";
CM_ SG_ 2364539648 AccelPedal1LowIdleSwitch_ "Switch signal which indicates the state of the accelerator pedal 1 low idle switch.";
CM_ SG_ 2364539648 AccelPedalKickdownSwitch "Switch signal which indicates whether the accelerator pedal kickdown switch is opened or closed.KD油门开关";
CM_ SG_ 2364539648 AccelPedalPos1_ "The ratio of actual position of the analog engine speed/torque request input device (such as an accelerator pedal or油门开度";
CM_ SG_ 2364539648 EngPercentLoadAtCurrentSpeed "The ratio of actual engine percent torque (indicated) to maximum indicated torque available at the current engine speed,当前转速下的负荷百分比";
CM_ SG_ 2364539648 ActualMaxAvailableEnginePercentTorque "This is the maximum amount of torque that the engine can immediately deliver as a percentage of the reference enginetorque (SPN 544).";
CM_ SG_ 2566827568 Pneumatic_Supply_Pres "空压机供气压力";
CM_ SG_ 2566827568 Parking_Tank_AirPrs "驻车储气筒气压";
CM_ SG_ 2566827568 ReAxleAirPressure "The pneumatic pressure in the primary service brake circuit or reservoir, supplying the rear axle. 后桥气压传感器信号";
CM_ SG_ 2566827568 FrAxleAirPressure "The pneumatic pressure in the secondary service brake circuit or reservoir, supplying the front axle. 前桥气压传感器信号";
CM_ SG_ 2348833319 Engine_override_control_mode "Requested Mode";
CM_ SG_ 2348833319 Override_control_mode_priority "Priority of request";
CM_ SG_ 2348833319 Vehicle_St_CrpDrv "蠕行功能开启标志位";
CM_ SG_ 2348833319 Engine_requested_torque_torque_limit "Torque in percent of the reference engine torque.";
CM_ SG_ 2348833319 Engine_Requested_Torque_High_Resolut "Additional high resoluted torque in percent of the reference engine torque.";
CM_ SG_ 2348833319 TSC1EM_Message_counter "Message Counter";
CM_ SG_ 2348833319 TSC1EM_Message_checksum "Message Checksum";
CM_ SG_ 2348876583 GearShiftInhibitReq "VCU Command signal to inhibit gear shifts.";
CM_ SG_ 2348876583 Disengage_Driveline_Request "Command signal used to simply disengage the driveline, e.g., to prevent engine drag torque from causing high wheel slipon slippery surfaces.";
CM_ SG_ 2348876583 Disengage_Differential_Lock_Request_Rear_Axle_1 "Command signal used to disengage the various differential locks";
CM_ SG_ 2348876583 Disengage_Differential_Lock_Request_Rear_Axle_2 "Command signal used to disengage the various differential locks";
CM_ SG_ 2365522215 EV_System_Release "Additional Release Request by the Driver  or Vehicle Controller (comparable to Kl50) to release the Driveline";
CM_ SG_ 2365522215 Electrical_System_Ready "Status of the HV System (including ESS, Vehicle control Unit, …) which indicates the Vehicle is possible to drive (for example, on Error case VECU, charging Batterie, the Signal status can be set to “0“)";
CM_ SG_ 2365522215 External_Acceleration_Limit_Request "External Request for EVCU Acceleration Limitation.";
CM_ SG_ 2365522215 External_Drive_Mode_Request "External Request for EVCU Power limitation";
CM_ SG_ 2365522215 External_Workshop_Mode_Request "Acitvates Workshop Mode, which disables ZF EVCU specific functions (ZF ASR); Activation will only work limited time";
CM_ SG_ 2365522215 External_Discharge_Request "External Request for discharging the HV DC-Link by the Inverter";
CM_ SG_ 2365522215 EVEHC_MSGCounter "Message Counter; Because this Message contains Safety Relevant Signals, it will use a separate CRC / Counter to ensure the Message / Signals are valid";
CM_ SG_ 2365522215 EVEHC_MSGChkSum "Message Checksum; Because this Message contains Safety Relevant Signals, it will use a separate CRC / Counter to ensure the Message / Signals are valid";
CM_ SG_ 2365530663 Requested_Gear "Requested Vehicle Direction (D,N,R) (only necessary if no ZF-Shiftlever is used)";
CM_ SG_ 2365530663 TC1_MSGCounter "Message Counter; Because this Message contains Safety Relevant Signals, it will use a separate CRC / Counter to ensure the Message / Signals are valid";
CM_ SG_ 2365530663 TC1_MSGChkSum "Message Checksum; Because this Message contains Safety Relevant Signals, it will use a separate CRC / Counter to ensure the Message / Signals are valid";
CM_ SG_ 2364539687 Accelerator_Pedal_Position "Accelerator Pedal Position";
CM_ SG_ 2566843687 MaxVehicleSpeedLimit "Maximum vehicle velocity allowed.";
CM_ SG_ 2364575988 DCL_Voltage "Actual Voltage of the DC link";
CM_ SG_ 2364575988 DCL_Current "Actual Current of the DC link( I<0 =Current Charged; I>0 = Current Discharged)";
CM_ SG_ 2364577012 DCL_Max_Current_Discharge "Max. limited discharge Current for traction of the DC link(reduction depending on temperature, …. For maximum lifetime of the ESS)";
CM_ SG_ 2364577012 DCL_Max_Current_Charge "Max. limited charge Current for recuperation of the DC link(reduction depending on temperature, …. For maximum lifetime of the ESS)";
CM_ SG_ 2364578036 BMS_DISCHG_MAX_PWR "当前状态允许最大放电功率（实时）";
CM_ SG_ 2364578036 BMS_FEED_MAX_PWR_Instant "当前状态允许最大回馈功率（瞬时）";
CM_ SG_ 2566698996 State_Of_Charge "ESS State of Charge (SOC)";
CM_ SG_ 2566848756 DCL_Max_Voltage "Static electrical voltage maximum limit of the DC link";
CM_ SG_ 2566848756 DCL_Min_Voltage "Static electrical voltage minimum limit of the DC link";
CM_ SG_ 2566846247 Battery_voltage_24V "24V battery voltage";

BA_DEF_ BU_ "NodeLayerModules" STRING ;
BA_DEF_ BU_ "NmStationAddress" HEX 0 255;
BA_DEF_ BU_ "NmCAN" INT 1 2;
BA_DEF_ BU_ "ILUsed" ENUM "No","Yes";
BA_DEF_ BU_ "J1939MultiPgBroadcastType" ENUM "FBFF","FEFF";
BA_DEF_ BU_ "J1939MultiPgSizeThreshold" INT 0 64;
BA_DEF_ BU_ "J1939MultiPgSendTimeout" INT 0 3600000;
BA_DEF_ "NmType" STRING ;
BA_DEF_ "VersionYear" INT 2010 2999;
BA_DEF_ "ProtocolType" STRING ;
BA_DEF_ "NmMessageCount" INT 0 255;
BA_DEF_ "NmBaseAddress" HEX 0 2047;
BA_DEF_ "DBName" STRING ;
BA_DEF_ "BusType" STRING ;
BA_DEF_ "Baudrate" INT 0 1000000;
BA_DEF_ BO_ "GenMsgSendType" ENUM "Cycle","NoMsgSendType","IfActive","Event","CA","CE";
BA_DEF_ BO_ "GenMsgNrOfRepetition" INT 0 0;
BA_DEF_ BO_ "GenMsgILSupport" ENUM "No","Yes";
BA_DEF_ BO_ "GenMsgCycleTimeFast" INT 0 0;
BA_DEF_ BO_ "GenMsgCycleTime" INT 0 0;
BA_DEF_ BO_ "NmMessage" ENUM "No","Yes";
BA_DEF_ BO_ "VFrameFormat" ENUM "StandardCAN","ExtendedCAN","reserved","J1939PG";
BA_DEF_ BO_ "J1939CPgTOS" INT 0 7;
BA_DEF_ BO_ "J1939CPgSendTimeout" INT -1 3600000;
BA_DEF_ BO_ "J1939PgAppearanceOnBus" ENUM "Default","CAN_Extended","CANFD_Extended";
BA_DEF_ BO_ "GenMsgRequestable" INT 0 1;
BA_DEF_ SG_ "GenSigInvalidValue" HEX 0 0;
BA_DEF_ SG_ "GenSigStartValue" HEX 0 0;
BA_DEF_ SG_ "GenSigInactiveValue" HEX 0 0;
BA_DEF_ SG_ "GenSigSendType" ENUM "Cycle","OnWrite","OnWriteWithRepetition","OnChange","OnChangeWithRepetition","IfActive","IfActiveWithRepetition","NoSigSendType","vector_leerstring";
BA_DEF_ SG_ "SPN" INT 0 0;
BA_DEF_ SG_ "ASIL" STRING ;
BA_DEF_ SG_ "SigType" ENUM "Default","Range","RangeSigned","ASCII","Discrete","Control","ReferencePGN","DTC","StringDelimiter","StringLength","StringLengthControl","MessageCounter","MessageChecksum";
BA_DEF_ SG_ "GenSigILSupport" ENUM "No","Yes";
BA_DEF_ SG_ "GenSigEVName" STRING ;
BA_DEF_DEF_ "NodeLayerModules" "OSEKNM01.dll,CANoeILNLVector.dll";
BA_DEF_DEF_ "NmStationAddress" 254;
BA_DEF_DEF_ "NmCAN" 2;
BA_DEF_DEF_ "ILUsed" "Yes";
BA_DEF_DEF_ "J1939MultiPgBroadcastType" "FEFF";
BA_DEF_DEF_ "J1939MultiPgSizeThreshold" 56;
BA_DEF_DEF_ "J1939MultiPgSendTimeout" 2;
BA_DEF_DEF_ "NmType" "OSEK";
BA_DEF_DEF_ "VersionYear" 2019;
BA_DEF_DEF_ "ProtocolType" "CAN";
BA_DEF_DEF_ "NmMessageCount" 128;
BA_DEF_DEF_ "NmBaseAddress" 1024;
BA_DEF_DEF_ "DBName" "";
BA_DEF_DEF_ "BusType" "";
BA_DEF_DEF_ "Baudrate" 500000;
BA_DEF_DEF_ "GenMsgSendType" "Cycle";
BA_DEF_DEF_ "GenMsgNrOfRepetition" 0;
BA_DEF_DEF_ "GenMsgILSupport" "Yes";
BA_DEF_DEF_ "GenMsgCycleTimeFast" 0;
BA_DEF_DEF_ "GenMsgCycleTime" 100;
BA_DEF_DEF_ "NmMessage" "No";
BA_DEF_DEF_ "VFrameFormat" "StandardCAN";
BA_DEF_DEF_ "J1939CPgTOS" 2;
BA_DEF_DEF_ "J1939CPgSendTimeout" -1;
BA_DEF_DEF_ "J1939PgAppearanceOnBus" "Default";
BA_DEF_DEF_ "GenMsgRequestable" 1;
BA_DEF_DEF_ "GenSigInvalidValue" 0;
BA_DEF_DEF_ "GenSigStartValue" 0;
BA_DEF_DEF_ "GenSigInactiveValue" 0;
BA_DEF_DEF_ "GenSigSendType" "Cycle";
BA_DEF_DEF_ "SPN" 0;
BA_DEF_DEF_ "ASIL" "";
BA_DEF_DEF_ "SigType" "Default";
BA_DEF_DEF_ "GenSigILSupport" "Yes";
BA_DEF_DEF_ "GenSigEVName" "Env@Nodename_@Signame";
BA_ "BusType" "CAN";
BA_ "ProtocolType" "J1939";
BA_ "DBName" "Matrix";
BA_ "NmStationAddress" BU_ VDCU_M 39;
BA_ "NmStationAddress" BU_ CDCU 33;
BA_ "NmStationAddress" BU_ VDR_TBOX 159;
BA_ "NmStationAddress" BU_ ADCU 42;
BA_ "NmStationAddress" BU_ VIU_B 100;
BA_ "NmStationAddress" BU_ VIU_C 48;
BA_ "NmStationAddress" BU_ VDCU_V 3;
BA_ "NmStationAddress" BU_ EPB 80;
BA_ "NmStationAddress" BU_ EBS 11;
BA_ "NmStationAddress" BU_ FCS 42;
BA_ "NmStationAddress" BU_ EPS_M 19;
BA_ "NmStationAddress" BU_ EPS_S 20;
BA_ "NmStationAddress" BU_ CMS_R 97;
BA_ "NmStationAddress" BU_ CMS_B 99;
BA_ "NmStationAddress" BU_ ECAS 47;
BA_ "NmStationAddress" BU_ EGSM 5;
BA_ "NmStationAddress" BU_ MTCU 4;
BA_ "GenMsgCycleTime" BO_ 2566889511 500;
BA_ "NmMessage" BO_ 2566889511 1;
BA_ "GenMsgCycleTimeFast" BO_ 2566889511 50;
BA_ "GenMsgSendType" BO_ 2566889511 4;
BA_ "VFrameFormat" BO_ 2566889511 1;
BA_ "VFrameFormat" BO_ 2566865177 3;
BA_ "VFrameFormat" BO_ 2566868505 3;
BA_ "VFrameFormat" BO_ 2566865433 3;
BA_ "VFrameFormat" BO_ 2566865689 3;
BA_ "VFrameFormat" BO_ 2566867812 3;
BA_ "VFrameFormat" BO_ 2566868068 3;
BA_ "VFrameFormat" BO_ 2566870884 3;
BA_ "VFrameFormat" BO_ 2566871140 3;
BA_ "GenMsgCycleTime" BO_ 2566909028 500;
BA_ "VFrameFormat" BO_ 2566909028 3;
BA_ "GenMsgCycleTime" BO_ 2566908772 500;
BA_ "VFrameFormat" BO_ 2566908772 3;
BA_ "VFrameFormat" BO_ 2566866021 3;
BA_ "VFrameFormat" BO_ 2566867557 3;
BA_ "VFrameFormat" BO_ 2566871397 3;
BA_ "VFrameFormat" BO_ 2566871653 3;
BA_ "VFrameFormat" BO_ 2566871909 3;
BA_ "GenMsgCycleTime" BO_ 2566907943 0;
BA_ "GenMsgSendType" BO_ 2566907943 3;
BA_ "VFrameFormat" BO_ 2566907943 3;
BA_ "GenMsgCycleTime" BO_ 2566858223 500;
BA_ "VFrameFormat" BO_ 2566858223 3;
BA_ "GenMsgCycleTime" BO_ 2566853359 50;
BA_ "VFrameFormat" BO_ 2566853359 3;
BA_ "VFrameFormat" BO_ 2566873957 3;
BA_ "VFrameFormat" BO_ 2566859824 3;
BA_ "VFrameFormat" BO_ 2566860080 3;
BA_ "VFrameFormat" BO_ 2566893413 3;
BA_ "GenMsgCycleTime" BO_ 2566860336 1000;
BA_ "VFrameFormat" BO_ 2566860336 3;
BA_ "GenMsgCycleTime" BO_ 2566903909 1000;
BA_ "VFrameFormat" BO_ 2566903909 3;
BA_ "GenMsgCycleTime" BO_ 2566903653 1000;
BA_ "VFrameFormat" BO_ 2566903653 3;
BA_ "VFrameFormat" BO_ 2566893351 3;
BA_ "GenMsgCycleTime" BO_ 2365522727 0;
BA_ "GenMsgSendType" BO_ 2365522727 3;
BA_ "VFrameFormat" BO_ 2365522727 3;
BA_ "GenMsgCycleTime" BO_ 2566861351 20;
BA_ "VFrameFormat" BO_ 2566861351 3;
BA_ "GenMsgCycleTime" BO_ 2566861607 50;
BA_ "GenMsgCycleTimeFast" BO_ 2566861607 20;
BA_ "VFrameFormat" BO_ 2566861607 3;
BA_ "VFrameFormat" BO_ 2566907443 3;
BA_ "GenMsgSendType" BO_ 2566907955 1;
BA_ "VFrameFormat" BO_ 2566907955 3;
BA_ "GenMsgCycleTime" BO_ 2348876549 20;
BA_ "VFrameFormat" BO_ 2348876549 3;
BA_ "VFrameFormat" BO_ 2566893317 3;
BA_ "GenMsgNrOfRepetition" BO_ 2365443105 3;
BA_ "GenMsgCycleTime" BO_ 2365443105 1000;
BA_ "GenMsgCycleTimeFast" BO_ 2365443105 100;
BA_ "GenMsgSendType" BO_ 2365443105 5;
BA_ "VFrameFormat" BO_ 2365443105 3;
BA_ "GenMsgNrOfRepetition" BO_ 2566769953 3;
BA_ "GenMsgCycleTime" BO_ 2566769953 1000;
BA_ "GenMsgCycleTimeFast" BO_ 2566769953 100;
BA_ "GenMsgSendType" BO_ 2566769953 5;
BA_ "VFrameFormat" BO_ 2566769953 3;
BA_ "VFrameFormat" BO_ 2566759916 3;
BA_ "VFrameFormat" BO_ 2566759917 3;
BA_ "VFrameFormat" BO_ 2566759780 3;
BA_ "VFrameFormat" BO_ 2566874468 3;
BA_ "VFrameFormat" BO_ 2566874724 3;
BA_ "VFrameFormat" BO_ 2566875236 3;
BA_ "VFrameFormat" BO_ 2566893412 3;
BA_ "VFrameFormat" BO_ 2566875492 3;
BA_ "VFrameFormat" BO_ 2566875748 3;
BA_ "VFrameFormat" BO_ 2566874980 3;
BA_ "GenMsgCycleTime" BO_ 2365522788 0;
BA_ "GenMsgSendType" BO_ 2365522788 3;
BA_ "VFrameFormat" BO_ 2365522788 3;
BA_ "GenMsgCycleTime" BO_ 2566845721 1000;
BA_ "VFrameFormat" BO_ 2566845721 3;
BA_ "VFrameFormat" BO_ 2566873629 3;
BA_ "GenMsgCycleTime" BO_ 2365537816 50;
BA_ "VFrameFormat" BO_ 2365537816 3;
BA_ "VFrameFormat" BO_ 2566873374 3;
BA_ "GenMsgCycleTime" BO_ 2364539904 20;
BA_ "VFrameFormat" BO_ 2364539904 3;
BA_ "GenMsgCycleTime" BO_ 2364539648 20;
BA_ "VFrameFormat" BO_ 2364539648 3;
BA_ "GenMsgCycleTime" BO_ 2566827568 500;
BA_ "VFrameFormat" BO_ 2566827568 3;
BA_ "GenMsgCycleTime" BO_ 2348833319 50;
BA_ "VFrameFormat" BO_ 2348833319 3;
BA_ "GenMsgCycleTime" BO_ 2348876583 50;
BA_ "VFrameFormat" BO_ 2348876583 3;
BA_ "GenMsgCycleTime" BO_ 2365522215 50;
BA_ "VFrameFormat" BO_ 2365522215 3;
BA_ "GenMsgCycleTime" BO_ 2365530663 50;
BA_ "VFrameFormat" BO_ 2365530663 3;
BA_ "GenMsgCycleTime" BO_ 2364539687 50;
BA_ "VFrameFormat" BO_ 2364539687 3;
BA_ "GenMsgCycleTime" BO_ 2566843687 50;
BA_ "VFrameFormat" BO_ 2566843687 3;
BA_ "GenMsgCycleTime" BO_ 2364575988 20;
BA_ "VFrameFormat" BO_ 2364575988 3;
BA_ "GenMsgCycleTime" BO_ 2364577012 20;
BA_ "VFrameFormat" BO_ 2364577012 3;
BA_ "GenMsgCycleTime" BO_ 2364578036 20;
BA_ "VFrameFormat" BO_ 2364578036 3;
BA_ "GenMsgCycleTime" BO_ 2566698996 1000;
BA_ "VFrameFormat" BO_ 2566698996 3;
BA_ "GenMsgCycleTime" BO_ 2566848756 1000;
BA_ "VFrameFormat" BO_ 2566848756 3;
BA_ "GenMsgCycleTime" BO_ 2566846247 1000;
BA_ "VFrameFormat" BO_ 2566846247 3;
BA_ "SPN" SG_ 2566889511 VDCU_SourceNodeID 520608;
BA_ "GenSigStartValue" SG_ 2566889511 VDCU_SourceNodeID 84;
BA_ "SPN" SG_ 2566889511 VDCU_RepeatMessageRequest 520609;
BA_ "SPN" SG_ 2566889511 VDCU_NMState_RMSfromBSM 520610;
BA_ "GenSigSendType" SG_ 2566889511 VDCU_NMState_RMSfromBSM 6;
BA_ "SPN" SG_ 2566889511 VDCU_NMState_RMSfromPBSM 520611;
BA_ "GenSigSendType" SG_ 2566889511 VDCU_NMState_RMSfromPBSM 6;
BA_ "SPN" SG_ 2566889511 VDCU_NMState_RMSfromNOS 520612;
BA_ "GenSigSendType" SG_ 2566889511 VDCU_NMState_RMSfromNOS 6;
BA_ "SPN" SG_ 2566889511 VDCU_NMState_RMSfromRSS 520613;
BA_ "GenSigSendType" SG_ 2566889511 VDCU_NMState_RMSfromRSS 6;
BA_ "SPN" SG_ 2566889511 VDCU_NMState_NOSfromRMS 520614;
BA_ "SPN" SG_ 2566889511 VDCU_NMState_NOSfromRSS 520615;
BA_ "SPN" SG_ 2566889511 VDCU_WakeupSource 520618;
BA_ "SPN" SG_ 2566889511 VDCU_NMKpARson_NMPduReceived 520815;
BA_ "SPN" SG_ 2566889511 VDCU_NMKpARson_TimeOut 520621;
BA_ "SPN" SG_ 2566889511 VDCU_NMKpARson_Diag 520620;
BA_ "SPN" SG_ 2566889511 VDCU_NMKpARson_KL15 520619;
BA_ "SPN" SG_ 2566889511 VDCU_NMKpARson_LINReq 520814;
BA_ "SPN" SG_ 2566889511 VDCU_NMKpARson_WinCtrl_L 520814;
BA_ "SPN" SG_ 2566889511 VDCU_NMKpARson_WinCtrl_R 520814;
BA_ "SPN" SG_ 2566889511 VDCU_NMKpARson_BrakePedalPressed 520814;
BA_ "SPN" SG_ 2566889511 VDCU_NMKpARson_LowBeamReq 520814;
BA_ "SPN" SG_ 2566889511 VDCU_NMKpARson_PosnLigjtReq 520814;
BA_ "SPN" SG_ 2566889511 VDCU_NMKpARson_DCChargeActive 520814;
BA_ "SPN" SG_ 2566889511 VDCU_NMKpARson_PowerOFFdelayMonitor 520814;
BA_ "SPN" SG_ 2566889511 VDCU_NMKpARson_ACChargeActive 520814;
BA_ "SPN" SG_ 2566889511 VDCU_NMKpARson_HVConnected 520814;
BA_ "SPN" SG_ 2566889511 VDCU_NMKpARson_ChargeWarmer 520814;
BA_ "SPN" SG_ 2566889511 VDCU_NMKpARson_Ready 520814;
BA_ "SPN" SG_ 2566889511 VDCU_NMKpARson_SmartCharge 520814;
BA_ "GenSigStartValue" SG_ 2566865177 ACTempLevelDisp 1;
BA_ "GenSigStartValue" SG_ 2566865177 ACModeMotorDisp 4;
BA_ "GenSigStartValue" SG_ 2566865177 ACModeMotorCtrl 4;
BA_ "ASIL" SG_ 2566865177 ACModeMotorCtrl "A";
BA_ "GenSigStartValue" SG_ 2566865177 ACCycleMotorDisp 2;
BA_ "GenSigStartValue" SG_ 2566865177 ACCycleMotorPosnCtrl 2;
BA_ "ASIL" SG_ 2566865177 ACBlowerLevelCtrl "A";
BA_ "ASIL" SG_ 2566865433 FAN_LowRelayCtrl "A";
BA_ "ASIL" SG_ 2566865433 Blower_RelayCtrl "A";
BA_ "ASIL" SG_ 2566865689 LFAN1_PWM "A";
BA_ "ASIL" SG_ 2566865689 LFAN2_PWM "A";
BA_ "ASIL" SG_ 2566865689 LFAN3_PWM "A";
BA_ "ASIL" SG_ 2566865689 LFAN4_PWM "A";
BA_ "ASIL" SG_ 2566865689 EAC1_ACFrontDefrostSysSts "A";
BA_ "ASIL" SG_ 2566865689 EAC2_ACFrontDefrostSysSts "A";
BA_ "GenSigInvalidValue" SG_ 2566870884 N_SunLightSensor 2047;
BA_ "GenSigStartValue" SG_ 2566870884 N_SunLightSensor 2047;
BA_ "GenSigSendType" SG_ 2566907943 ValidDKM 1;
BA_ "ASIL" SG_ 2566858223 VBUS_VCU7_BATT_HVIL_Err "A";
BA_ "ASIL" SG_ 2566853359 VBUS_VCU4_N_VehicleSpeed "B";
BA_ "ASIL" SG_ 2566853359 VBUS_VCU4_St_Gears "B";
BA_ "ASIL" SG_ 2566853359 VBUS_VCU4_St_Vehicle "A";
BA_ "ASIL" SG_ 2566853359 VBUS_VCU4_St_Interlocking "A";
BA_ "ASIL" SG_ 2566853359 VBUS_VCU4_F_Motor "A";
BA_ "ASIL" SG_ 2566853359 VBUS_VCU4_St_Thermal_runaway "A";
BA_ "ASIL" SG_ 2566893413 VIUC_ACFrontDefrostSysSts "A";
BA_ "ASIL" SG_ 2566893351 LowBeamFltWarn_VDCU "B";
BA_ "ASIL" SG_ 2566893351 MainBrkLightFltWarn_VDCU "B";
BA_ "ASIL" SG_ 2566893351 TrailerBrkLightFltWarn_VDCU "B";
BA_ "ASIL" SG_ 2566893351 HighBeamFltWarn_VDCU "A";
BA_ "ASIL" SG_ 2566893351 OvertakinglampWarn_VDCU "A";
BA_ "ASIL" SG_ 2566893351 FrontOperatorWiperFltWarn_VDCU "A";
BA_ "ASIL" SG_ 2566893351 WinCtrlFlt_Drvr_VDCU "A";
BA_ "ASIL" SG_ 2566893351 WinCtrlFlt_Pass_VDCU "A";
BA_ "ASIL" SG_ 2566893351 VDCU_ACFrontDefrostSysSts "A";
BA_ "ASIL" SG_ 2566893351 LowPowerModeWarn_VDCU "B";
BA_ "GenSigSendType" SG_ 2365522727 CertificationSts_VDCU 1;
BA_ "GenSigSendType" SG_ 2365522727 RandomData1_VDCU 1;
BA_ "GenSigSendType" SG_ 2365522727 RandomData2_VDCU 1;
BA_ "GenSigSendType" SG_ 2365522727 RandomData3_VDCU 1;
BA_ "GenSigSendType" SG_ 2365522727 RandomData4_VDCU 1;
BA_ "GenSigSendType" SG_ 2365522727 RandomData5_VDCU 1;
BA_ "GenSigSendType" SG_ 2365522727 RandomData6_VDCU 1;
BA_ "GenSigSendType" SG_ 2365522727 RandomData7_VDCU 1;
BA_ "GenSigSendType" SG_ 2365522727 RandomData8_VDCU 1;
BA_ "GenSigSendType" SG_ 2365522727 RandomData9_VDCU 1;
BA_ "GenSigSendType" SG_ 2365522727 RandomData10_VDCU 1;
BA_ "GenSigSendType" SG_ 2365522727 RandomData11_VDCU 1;
BA_ "GenSigSendType" SG_ 2365522727 RandomData12_VDCU 1;
BA_ "GenSigSendType" SG_ 2365522727 RandomData13_VDCU 1;
BA_ "GenSigSendType" SG_ 2365522727 RandomData14_VDCU 1;
BA_ "GenSigSendType" SG_ 2365522727 RandomData15_VDCU 1;
BA_ "GenSigSendType" SG_ 2365522727 RandomData16_VDCU 1;
BA_ "ASIL" SG_ 2566861351 LowBeamReq "B";
BA_ "ASIL" SG_ 2566861351 HighBeamReq "A";
BA_ "ASIL" SG_ 2566861351 MainBrkLightReq "B";
BA_ "ASIL" SG_ 2566861351 TrailerBrkLightReq "B";
BA_ "ASIL" SG_ 2566861607 WiperReq "A";
BA_ "ASIL" SG_ 2566861607 LowPowerMode "B";
BA_ "SPN" SG_ 2566907443 Wheel_Location_ID 524149;
BA_ "GenSigStartValue" SG_ 2566907443 Wheel_Location_ID 23;
BA_ "SPN" SG_ 2566907443 Tyre_Temperature 524150;
BA_ "GenSigStartValue" SG_ 2566907443 Tyre_Temperature 255;
BA_ "SPN" SG_ 2566907443 Tyre_Pressure 524151;
BA_ "GenSigInvalidValue" SG_ 2566907443 Tyre_Pressure 1023;
BA_ "GenSigStartValue" SG_ 2566907443 Tyre_Pressure 1023;
BA_ "SPN" SG_ 2566907443 WU_Battery_Status 524152;
BA_ "GenSigInvalidValue" SG_ 2566907443 WU_Battery_Status 15;
BA_ "GenSigStartValue" SG_ 2566907443 WU_Battery_Status 15;
BA_ "SPN" SG_ 2566907443 Tyre_LearnStatus 524153;
BA_ "SPN" SG_ 2566907443 Tyre_SensorLose_warning 524154;
BA_ "SPN" SG_ 2566907443 Tyre_Learn 524156;
BA_ "SPN" SG_ 2566907443 Tyre_SensorLowBatt_warning 524158;
BA_ "SPN" SG_ 2566907443 Tyre_Pressure_Status 524155;
BA_ "GenSigInvalidValue" SG_ 2566907443 Tyre_Pressure_Status 15;
BA_ "GenSigStartValue" SG_ 2566907443 Tyre_Pressure_Status 15;
BA_ "SPN" SG_ 2566907443 Tyre_Over_Temp_Status 524157;
BA_ "GenSigInvalidValue" SG_ 2566907443 Tyre_Over_Temp_Status 3;
BA_ "GenSigStartValue" SG_ 2566907443 Tyre_Over_Temp_Status 3;
BA_ "SPN" SG_ 2566907443 Sensor_ID_Prog_Status 524160;
BA_ "GenSigInvalidValue" SG_ 2566907443 Sensor_ID_Prog_Status 3;
BA_ "GenSigStartValue" SG_ 2566907443 Sensor_ID_Prog_Status 1;
BA_ "SPN" SG_ 2566907955 MLS_Page 520002;
BA_ "GenSigSendType" SG_ 2566907955 MLS_Page 5;
BA_ "SPN" SG_ 2566907955 MLS_truck_trailer 520003;
BA_ "GenSigSendType" SG_ 2566907955 MLS_truck_trailer 5;
BA_ "SPN" SG_ 2566907955 MLS 520004;
BA_ "GenSigInvalidValue" SG_ 2566907955 MLS 15;
BA_ "GenSigInactiveValue" SG_ 2566907955 MLS 14;
BA_ "GenSigSendType" SG_ 2566907955 MLS 5;
BA_ "SPN" SG_ 2566907955 MLS_Tyre_Loc 520005;
BA_ "GenSigStartValue" SG_ 2566907955 MLS_Tyre_Loc 23;
BA_ "GenSigSendType" SG_ 2566907955 MLS_Tyre_Loc 5;
BA_ "ASIL" SG_ 2348876549 TransmissionRequestedGear "B";
BA_ "GenSigStartValue" SG_ 2348876549 AssistedbrakingSwt 7;
BA_ "GenSigStartValue" SG_ 2348876549 TransmissionRequestedGearflag 3;
BA_ "ASIL" SG_ 2566893317 HighBeamFltWarn_GSM "A";
BA_ "ASIL" SG_ 2566893317 OvertakinglampWarn_GSM "A";
BA_ "ASIL" SG_ 2566893317 FrontOperatorWiperFltWarn_GSM "A";
BA_ "ASIL" SG_ 2566893317 ShiftFltWarn_GSM "B";
BA_ "SPN" SG_ 2365443105 TurnSignalSwt 2876;
BA_ "SPN" SG_ 2365443105 HighBeamSwt 2874;
BA_ "ASIL" SG_ 2365443105 HighBeamSwt "A";
BA_ "ASIL" SG_ 2365443105 OvertakinglampSwt "A";
BA_ "SPN" SG_ 2566769953 FrontOperatorWiperSwt 2863;
BA_ "ASIL" SG_ 2566769953 FrontOperatorWiperSwt "A";
BA_ "ASIL" SG_ 2566769953 WiprSensitivitySwt "A";
BA_ "SPN" SG_ 2566769953 FrontOperatorWasherSwt 2866;
BA_ "ASIL" SG_ 2566874724 WiperParkSwt "A";
BA_ "ASIL" SG_ 2566874724 WiperSts "B";
BA_ "ASIL" SG_ 2566874724 AutoLampSwt "B";
BA_ "ASIL" SG_ 2566874724 LowBeamSwt "B";
BA_ "ASIL" SG_ 2566893412 LowBeamFltWarn_VIUB "B";
BA_ "ASIL" SG_ 2566893412 HighBeamFltWarn_VIUB "A";
BA_ "ASIL" SG_ 2566893412 FrontOperatorWiperFltWarn_VIUB "A";
BA_ "ASIL" SG_ 2566893412 AntiPinchFlt_Drvr_VIUB "A";
BA_ "ASIL" SG_ 2566893412 AntiPinchFlt_Pass_VIUB "A";
BA_ "ASIL" SG_ 2566893412 WinCtrlFlt_Drvr_VIUB "A";
BA_ "ASIL" SG_ 2566893412 WinCtrlFlt_Pass_VIUB "A";
BA_ "ASIL" SG_ 2566893412 VIUB_ACFrontDefrostSysSts "A";
BA_ "ASIL" SG_ 2566893412 MainBrkLightFltWarn_VIUC "B";
BA_ "ASIL" SG_ 2566893412 TrailerBrkLightFltWarn_VIUC "B";
BA_ "ASIL" SG_ 2566875492 WinSwt_DrvrsideD "A";
BA_ "ASIL" SG_ 2566875492 WinPsn_Drvr "A";
BA_ "ASIL" SG_ 2566875492 WinPsn_Pass "A";
BA_ "GenSigSendType" SG_ 2365522788 CertificationSts_VIU 1;
BA_ "GenSigSendType" SG_ 2365522788 CMAC1_VIU 1;
BA_ "GenSigSendType" SG_ 2365522788 CMAC2_VIU 1;
BA_ "GenSigSendType" SG_ 2365522788 CMAC3_VIU 1;
BA_ "GenSigSendType" SG_ 2365522788 CMAC4_VIU 1;
BA_ "GenSigSendType" SG_ 2365522788 CMAC5_VIU 1;
BA_ "GenSigSendType" SG_ 2365522788 CMAC6_VIU 1;
BA_ "GenSigSendType" SG_ 2365522788 CMAC7_VIU 1;
BA_ "GenSigSendType" SG_ 2365522788 CMAC8_VIU 1;
BA_ "GenSigSendType" SG_ 2365522788 CMAC9_VIU 1;
BA_ "GenSigSendType" SG_ 2365522788 CMAC10_VIU 1;
BA_ "GenSigSendType" SG_ 2365522788 CMAC11_VIU 1;
BA_ "GenSigSendType" SG_ 2365522788 CMAC12_VIU 1;
BA_ "GenSigSendType" SG_ 2365522788 CMAC13_VIU 1;
BA_ "GenSigSendType" SG_ 2365522788 CMAC14_VIU 1;
BA_ "GenSigSendType" SG_ 2365522788 CMAC15_VIU 1;
BA_ "GenSigSendType" SG_ 2365522788 CMAC16_VIU 1;
BA_ "SPN" SG_ 2566845721 AmbAirT 171;
BA_ "SPN" SG_ 2364539904 EngTorqueMode_ 899;
BA_ "SPN" SG_ 2364539904 ActlEngPrcntTrqueHighResolution_ 4154;
BA_ "SPN" SG_ 2364539904 DriversDemandEngPercentTorque 512;
BA_ "SPN" SG_ 2364539904 ActualEngPercentTorque_CF00400 513;
BA_ "SPN" SG_ 2364539904 EngSpeed 190;
BA_ "SPN" SG_ 2364539648 AccelPedal1LowIdleSwitch_ 558;
BA_ "GenSigStartValue" SG_ 2364539648 AccelPedal1LowIdleSwitch_ 3;
BA_ "SPN" SG_ 2364539648 AccelPedalKickdownSwitch 559;
BA_ "GenSigStartValue" SG_ 2364539648 AccelPedalKickdownSwitch 3;
BA_ "SPN" SG_ 2364539648 AccelPedalPos1_ 91;
BA_ "ASIL" SG_ 2364539648 AccelPedalPos1_ "B";
BA_ "SPN" SG_ 2364539648 EngPercentLoadAtCurrentSpeed 92;
BA_ "SPN" SG_ 2364539648 ActualMaxAvailableEnginePercentTorque 3357;
BA_ "SPN" SG_ 2566827568 ReAxleAirPressure 1087;
BA_ "SPN" SG_ 2566827568 FrAxleAirPressure 1088;
BA_ "SPN" SG_ 2348833319 Engine_override_control_mode 695;
BA_ "SPN" SG_ 2348833319 Override_control_mode_priority 897;
BA_ "SPN" SG_ 2348833319 Engine_requested_torque_torque_limit 518;
BA_ "SPN" SG_ 2348833319 Engine_Requested_Torque_High_Resolut 4191;
BA_ "SPN" SG_ 2348833319 TSC1EM_Message_counter 4206;
BA_ "SPN" SG_ 2348833319 TSC1EM_Message_checksum 4207;
BA_ "SPN" SG_ 2348876583 GearShiftInhibitReq 681;
BA_ "GenSigStartValue" SG_ 2348876583 GearShiftInhibitReq 3;
BA_ "SPN" SG_ 2348876583 Disengage_Driveline_Request 683;
BA_ "GenSigStartValue" SG_ 2348876583 Disengage_Driveline_Request 3;
BA_ "SPN" SG_ 2348876583 Disengage_Differential_Lock_Request_Rear_Axle_1 687;
BA_ "GenSigStartValue" SG_ 2348876583 Disengage_Differential_Lock_Request_Rear_Axle_1 3;
BA_ "SPN" SG_ 2348876583 Disengage_Differential_Lock_Request_Rear_Axle_2 688;
BA_ "GenSigStartValue" SG_ 2348876583 Disengage_Differential_Lock_Request_Rear_Axle_2 3;
BA_ "SPN" SG_ 2365522215 EVEHC_MSGCounter 4206;
BA_ "SPN" SG_ 2365522215 EVEHC_MSGChkSum 4207;
BA_ "SPN" SG_ 2365530663 Requested_Gear 525;
BA_ "GenSigStartValue" SG_ 2365530663 Requested_Gear 222;
BA_ "SPN" SG_ 2365530663 TC1_MSGCounter 4206;
BA_ "SPN" SG_ 2365530663 TC1_MSGChkSum 4207;
BA_ "SPN" SG_ 2364539687 Accelerator_Pedal_Position 91;
BA_ "SPN" SG_ 2566843687 MaxVehicleSpeedLimit 74;
BA_ "GenSigInvalidValue" SG_ 2364575988 DCL_Voltage 255;
BA_ "GenSigInvalidValue" SG_ 2364575988 DCL_Current 255;
BA_ "GenSigStartValue" SG_ 2364575988 DCL_Current 10000;
BA_ "GenSigInvalidValue" SG_ 2364577012 DCL_Max_Current_Discharge 255;
BA_ "GenSigStartValue" SG_ 2364577012 DCL_Max_Current_Discharge 10000;
BA_ "GenSigInvalidValue" SG_ 2364577012 DCL_Max_Current_Charge 255;
BA_ "GenSigStartValue" SG_ 2364577012 DCL_Max_Current_Charge 10000;
BA_ "GenSigInvalidValue" SG_ 2566848756 DCL_Max_Voltage 255;
BA_ "GenSigInvalidValue" SG_ 2566848756 DCL_Min_Voltage 255;
BA_ "SPN" SG_ 2566846247 Battery_voltage_24V 158;
VAL_ 2566889511 VDCU_ActiveWakeUpBit 1 "Active" 0 "Inactive";
VAL_ 2566889511 VDCU_RepeatMessageRequest 1 "RepeatMessageRequest" 0 "Inactive";
VAL_ 2566889511 VDCU_NMState_RMSfromBSM 1 "RepeatMessageState" 0 "Inactive";
VAL_ 2566889511 VDCU_NMState_RMSfromPBSM 1 "RepeatMessageState" 0 "Inactive";
VAL_ 2566889511 VDCU_NMState_RMSfromNOS 1 "RepeatMessageState" 0 "Inactive";
VAL_ 2566889511 VDCU_NMState_RMSfromRSS 1 "RepeatMessageState" 0 "Inactive";
VAL_ 2566889511 VDCU_NMState_NOSfromRMS 1 "NormalOperationState" 0 "Inactive";
VAL_ 2566889511 VDCU_NMState_NOSfromRSS 1 "NormalOperationState" 0 "Inactive";
VAL_ 2566889511 VDCU_WakeupSource 255 "Reserved" 254 "Reserved" 253 "Reserved" 252 "Reserved" 251 "Reserved" 250 "Reserved" 249 "Reserved" 248 "Reserved" 247 "Reserved" 246 "Reserved" 245 "Reserved" 244 "Reserved" 243 "Reserved" 242 "Reserved" 241 "Reserved" 240 "Reserved" 239 "Reserved" 238 "Reserved" 237 "Reserved" 236 "Reserved" 235 "Reserved" 234 "Reserved" 233 "Reserved" 232 "Reserved" 231 "Reserved" 230 "Reserved" 229 "Reserved" 228 "Reserved" 227 "Reserved" 226 "Reserved" 225 "Reserved" 224 "Reserved" 223 "Reserved" 222 "Reserved" 221 "Reserved" 220 "Reserved" 219 "Reserved" 218 "Reserved" 217 "Reserved" 216 "Reserved" 215 "Reserved" 214 "Reserved" 213 "Reserved" 212 "Reserved" 211 "Reserved" 210 "Reserved" 209 "Reserved" 208 "Reserved" 207 "Reserved" 206 "Reserved" 205 "Reserved" 204 "Reserved" 203 "Reserved" 202 "Reserved" 201 "Reserved" 200 "Reserved" 199 "Reserved" 198 "Reserved" 197 "Reserved" 196 "Reserved" 195 "Reserved" 194 "Reserved" 193 "Reserved" 192 "Reserved" 191 "Reserved" 190 "Reserved" 189 "Reserved" 188 "Reserved" 187 "Reserved" 186 "Reserved" 185 "Reserved" 184 "Reserved" 183 "Reserved" 182 "Reserved" 181 "Reserved" 180 "Reserved" 179 "Reserved" 178 "Reserved" 177 "Reserved" 176 "Reserved" 175 "Reserved" 174 "Reserved" 173 "Reserved" 172 "Reserved" 171 "Reserved" 170 "Reserved" 169 "Reserved" 168 "Reserved" 167 "Reserved" 166 "Reserved" 165 "Reserved" 164 "Reserved" 163 "Reserved" 162 "Reserved" 161 "Reserved" 160 "Reserved" 159 "Reserved" 158 "Reserved" 157 "Reserved" 156 "Reserved" 155 "Reserved" 154 "Reserved" 153 "Reserved" 152 "Reserved" 151 "Reserved" 150 "Reserved" 149 "Reserved" 148 "Reserved" 147 "Reserved" 146 "Reserved" 145 "Reserved" 144 "Reserved" 143 "Reserved" 142 "Reserved" 141 "Reserved" 140 "Reserved" 139 "Reserved" 138 "Reserved" 137 "Reserved" 136 "Reserved" 135 "Reserved" 134 "Reserved" 133 "Reserved" 132 "Reserved" 131 "Reserved" 130 "Reserved" 129 "Reserved" 128 "Reserved" 127 "Reserved" 126 "Reserved" 125 "Reserved" 124 "Reserved" 123 "Reserved" 122 "Reserved" 121 "Reserved" 120 "Reserved" 119 "Reserved" 118 "Reserved" 117 "Reserved" 116 "Reserved" 115 "Reserved" 114 "Reserved" 113 "Reserved" 112 "Reserved" 111 "Reserved" 110 "Reserved" 109 "Reserved" 108 "Reserved" 107 "Reserved" 106 "Reserved" 105 "Reserved" 104 "Reserved" 103 "Reserved" 102 "Reserved" 101 "Reserved" 100 "Reserved" 99 "Reserved" 98 "Reserved" 97 "Reserved" 96 "Reserved" 95 "Reserved" 94 "Reserved" 93 "Reserved" 92 "Reserved" 91 "Reserved" 90 "Reserved" 89 "Reserved" 88 "Reserved" 87 "Reserved" 86 "Reserved" 85 "Reserved" 84 "Reserved" 83 "Reserved" 82 "Reserved" 81 "Reserved" 80 "Reserved" 79 "Reserved" 78 "Reserved" 77 "Reserved" 76 "Reserved" 75 "Reserved" 74 "Reserved" 73 "Reserved" 72 "Reserved" 71 "Reserved" 70 "Reserved" 69 "Reserved" 68 "Reserved" 67 "Reserved" 66 "Reserved" 65 "Reserved" 64 "Reserved" 63 "Reserved" 62 "Reserved" 61 "Reserved" 60 "Reserved" 59 "Reserved" 58 "Reserved" 57 "Reserved" 56 "Reserved" 55 "Reserved" 54 "Reserved" 53 "Reserved" 52 "Reserved" 51 "Reserved" 50 "Reserved" 49 "Reserved" 48 "Reserved" 47 "Reserved" 46 "Reserved" 45 "Reserved" 44 "Reserved" 43 "Reserved" 42 "Reserved" 41 "Reserved" 40 "Reserved" 39 "Reserved" 38 "Reserved" 37 "Reserved" 36 "Reserved" 35 "Reserved" 34 "Reserved" 33 "Reserved" 32 "Reserved" 31 "Reserved" 30 "Reserved" 29 "Reserved" 28 "Reserved" 27 "Reserved" 26 "Reserved" 25 "Reserved" 24 "Reserved" 23 "Reserved" 22 "Reserved" 21 "Reserved" 20 "Reserved" 19 "Reserved" 18 "Reserved" 17 "Reserved" 16 "Reserved" 15 "Reserved" 14 "Reserved" 13 "Reserved" 12 "Reserved" 11 "Reserved" 10 "Reserved" 9 "蓄电池智能补电激活" 8 "电池充电保温" 7 "ACChargeActive" 6 "DCChargeActive" 5 "下电延时监控" 4 "BrakePadelPressed" 3 "LIN WakeupFrame" 2 "Diagnose" 1 "NM PDU Received" 0 "Default";
VAL_ 2566889511 VDCU_NMKpARson_NMPduReceived 1 "Active" 0 "Inactive";
VAL_ 2566889511 VDCU_NMKpARson_TimeOut 1 "Active" 0 "Inactive";
VAL_ 2566889511 VDCU_NMKpARson_Diag 1 "Active" 0 "Inactive";
VAL_ 2566889511 VDCU_NMKpARson_KL15 1 "Active" 0 "Inactive";
VAL_ 2566889511 VDCU_NMKpARson_LINReq 1 "Active" 0 "Inactive";
VAL_ 2566889511 VDCU_NMKpARson_WinCtrl_L 1 "Active" 0 "Inactive";
VAL_ 2566889511 VDCU_NMKpARson_WinCtrl_R 1 "Active" 0 "Inactive";
VAL_ 2566889511 VDCU_NMKpARson_BrakePedalPressed 1 "Active" 0 "Inactive";
VAL_ 2566889511 VDCU_NMKpARson_LowBeamReq 1 "Active" 0 "Inactive";
VAL_ 2566889511 VDCU_NMKpARson_PosnLigjtReq 1 "Active" 0 "Inactive";
VAL_ 2566889511 VDCU_NMKpARson_DCChargeActive 1 "Active" 0 "Inactive";
VAL_ 2566889511 VDCU_NMKpARson_PowerOFFdelayMonitor 1 "Active" 0 "Inactive";
VAL_ 2566889511 VDCU_NMKpARson_ACChargeActive 1 "Active" 0 "Inactive";
VAL_ 2566889511 VDCU_NMKpARson_HVConnected 1 "Active" 0 "Inactive";
VAL_ 2566889511 VDCU_NMKpARson_ChargeWarmer 1 "Active" 0 "Inactive";
VAL_ 2566889511 VDCU_NMKpARson_Ready 1 "Active" 0 "Inactive";
VAL_ 2566889511 VDCU_NMKpARson_SmartCharge 1 "Active" 0 "Inactive";
VAL_ 2566865177 ACTempLevelDisp 63 "Reserved" 62 "Reserved" 61 "Reserved" 60 "Reserved" 59 "Reserved" 58 "Reserved" 57 "Reserved" 56 "Reserved" 55 "Reserved" 54 "Reserved" 53 "Reserved" 52 "Reserved" 51 "Reserved" 50 "Reserved" 49 "Reserved" 48 "Reserved" 47 "Reserved" 46 "Reserved" 45 "Reserved" 44 "Reserved" 43 "Reserved" 42 "Reserved" 41 "Reserved" 40 "Reserved" 39 "Reserved" 38 "Reserved" 37 "Reserved" 36 "Reserved" 35 "Reserved" 34 "Reserved" 33 "Reserved" 32 "Reserved" 31 "32℃" 30 "31.5℃" 29 "31℃" 28 "30.5℃" 27 "30℃" 26 "29.5℃" 25 "29℃" 24 "28.5℃" 23 "28℃" 22 "27.5℃" 21 "27℃" 20 "26.5℃" 19 "26℃" 18 "25.5" 17 "25℃" 16 "24.5℃" 15 "24℃" 14 "23.5℃" 13 "23℃" 12 "22.5℃" 11 "22℃" 10 "21.5℃" 9 "21℃" 8 "20.5℃" 7 "20℃" 6 "19.5℃" 5 "19℃" 4 "18.5℃" 3 "18℃" 2 "17.5℃" 1 "17℃" 0 "TakeNoAction";
VAL_ 2566865177 ACPTCDisp 3 "Reserved" 2 "On" 1 "Off" 0 "TakeNoAction";
VAL_ 2566865177 ACTempLevelCtrl 63 "Reserved" 62 "Reserved" 61 "Reserved" 60 "Reserved" 59 "Reserved" 58 "Reserved" 57 "Reserved" 56 "Reserved" 55 "Reserved" 54 "Reserved" 53 "Reserved" 52 "Reserved" 51 "Reserved" 50 "Reserved" 49 "Reserved" 48 "Reserved" 47 "Reserved" 46 "Reserved" 45 "Reserved" 44 "Reserved" 43 "Reserved" 42 "Reserved" 41 "Reserved" 40 "Reserved" 39 "Reserved" 38 "Reserved" 37 "Reserved" 36 "Reserved" 35 "Reserved" 34 "Reserved" 33 "Reserved" 32 "Reserved" 31 "32℃" 30 "31.5℃" 29 "31℃" 28 "30.5℃" 27 "30℃" 26 "29.5℃" 25 "29℃" 24 "28.5℃" 23 "28℃" 22 "27.5℃" 21 "27℃" 20 "26.5℃" 19 "26℃" 18 "25.5" 17 "25℃" 16 "24.5℃" 15 "24℃" 14 "23.5℃" 13 "23℃" 12 "22.5℃" 11 "22℃" 10 "21.5℃" 9 "21℃" 8 "20.5℃" 7 "20℃" 6 "19.5℃" 5 "19℃" 4 "18.5℃" 3 "18℃" 2 "17.5℃" 1 "17℃" 0 "No Cmd";
VAL_ 2566865177 ACModeMotorDisp 7 "Reserved" 6 "Auto" 5 "Defrost" 4 "Foot&Defrost" 3 "Foot" 2 "Face&Foot" 1 "Face" 0 "TakeNoAction";
VAL_ 2566865177 ACModeMotorCtrl 7 "Reserved" 6 "Reserved" 5 "Defrost" 4 "Foot&Defrost" 3 "Foot" 2 "Face&Foot" 1 "Face" 0 "No Cmd";
VAL_ 2566865177 ACCycleMotorDisp 3 "Auto" 2 "Outside Cycle" 1 "Inside Cycle" 0 "TakeNoAction";
VAL_ 2566865177 ACCycleMotorPosnCtrl 3 "Reserved" 2 "Outside Cycle" 1 "Inside Cycle" 0 "No Cmd";
VAL_ 2566865177 ACBlowerLevelDisp 15 "Reserved" 14 "Reserved" 13 "Reserved" 12 "Reserved" 11 "Reserved" 10 "Reserved" 9 "Auto" 8 "7" 7 "6" 6 "5" 5 "4" 4 "3" 3 "2" 2 "1" 1 "Off" 0 "TakeNoAction";
VAL_ 2566865177 ACBlowerLevelCtrl 15 "Reserved" 14 "Reserved" 13 "Reserved" 12 "Reserved" 11 "Reserved" 10 "Reserved" 9 "Reserved" 8 "7" 7 "6" 6 "5" 5 "4" 4 "3" 3 "2" 2 "1" 1 "Off" 0 "No Cmd";
VAL_ 2566865177 ACFrontDefrostDisp 3 "Reserved" 2 "On" 1 "Off" 0 "TakeNoAction";
VAL_ 2566865177 ACAcDisp 3 "Reserved" 2 "On" 1 "Off" 0 "TakeNoAction";
VAL_ 2566865177 ACMaxDisp 3 "Reserved" 2 "On" 1 "Off" 0 "TakeNoAction";
VAL_ 2566865177 ACAutoDisp 3 "Reserved" 2 "On" 1 "Off" 0 "TakeNoAction";
VAL_ 2566865177 ACOffDisp 3 "Reserved" 2 "On" 1 "Off" 0 "TakeNoAction";
VAL_ 2566865177 ACAirPurgeDisp 3 "Reserved" 2 "On" 1 "Off" 0 "TakeNoAction";
VAL_ 2566865177 ACAirPurgeCtrl 3 "Reserved" 2 "On" 1 "Off" 0 "No Cmd";
VAL_ 2566865177 ACLonizerDisp 3 "Reserved" 2 "On" 1 "Off" 0 "TakeNoAction";
VAL_ 2566865177 ACLonizerCtrl 3 "Reserved" 2 "On" 1 "Off" 0 "No Cmd";
VAL_ 2566865177 AC_TempZoneSyncSts 3 "Reserved" 2 "Sync On" 1 "Sync Off" 0 "TakeNoAction";
VAL_ 2566865177 AC_HeatingMaxSts 3 "Reserved" 2 "On" 1 "Off" 0 "TakeNoAction";
VAL_ 2566865177 ElecACTempLevelDisp 31 "Reserved" 30 "Reserved" 29 "Reserved" 28 "Reserved" 27 "Reserved" 26 "Reserved" 25 "Reserved" 24 "Reserved" 23 "Reserved" 22 "Reserved" 21 "Reserved" 20 "Reserved" 19 "Reserved" 18 "Reserved" 17 "Reserved" 16 "Warm Level_8" 15 "Warm Level_7" 14 "Warm Level_6" 13 "Warm Level_5" 12 "Warm Level_4" 11 "Warm Level_3" 10 "Warm Level_2" 9 "Warm Level_1" 8 "Cold Level_1" 7 "Cold Level_2" 6 "Cold Level_3" 5 "Cold Level_4" 4 "Cold Level_5" 3 "Cold Level_6" 2 "Cold Level_7" 1 "Cold Level_8" 0 "TakeNoAction";
VAL_ 2566868505 HVPowerOnReq_HBattFan 3 "Reserved" 2 "Reserved" 1 "HV On Req" 0 "No Req";
VAL_ 2566868505 HVPowerOnReq_HMotorFan 3 "Reserved" 2 "Reserved" 1 "HV On Req" 0 "No Req";
VAL_ 2566868505 HVPowerOnReq_EAS1 3 "Reserved" 2 "Reserved" 1 "HV On Req" 0 "No Req";
VAL_ 2566868505 HVPowerOnReq_EAS2 3 "Reserved" 2 "Reserved" 1 "HV On Req" 0 "No Req";
VAL_ 2566868505 HVPowerOnReq_EAS3 3 "Reserved" 2 "Reserved" 1 "HV On Req" 0 "No Req";
VAL_ 2566868505 HVPowerOnReq_WPTC1 3 "Reserved" 2 "Reserved" 1 "HV On Req" 0 "No Req";
VAL_ 2566868505 HVPowerOnReq_WPTC2 3 "Reserved" 2 "Reserved" 1 "HV On Req" 0 "No Req";
VAL_ 2566868505 HVPowerOnReq_WPTC3 3 "Reserved" 2 "Reserved" 1 "HV On Req" 0 "No Req";
VAL_ 2566868505 HVPowerOnReq_APTC 3 "Reserved" 2 "Reserved" 1 "HV On Req" 0 "No Req";
VAL_ 2566865433 ACTempLevelDispSlpr 63 "Reserved" 62 "Reserved" 61 "Reserved" 60 "Reserved" 59 "Reserved" 58 "Reserved" 57 "Reserved" 56 "Reserved" 55 "Reserved" 54 "Reserved" 53 "Reserved" 52 "Reserved" 51 "Reserved" 50 "Reserved" 49 "Reserved" 48 "Reserved" 47 "Reserved" 46 "Reserved" 45 "Reserved" 44 "Reserved" 43 "Reserved" 42 "Reserved" 41 "Reserved" 40 "Reserved" 39 "Reserved" 38 "Reserved" 37 "Reserved" 36 "Reserved" 35 "Reserved" 34 "Reserved" 33 "Reserved" 32 "Reserved" 31 "32℃" 30 "31.5℃" 29 "31℃" 28 "30.5℃" 27 "30℃" 26 "29.5℃" 25 "29℃" 24 "28.5℃" 23 "28℃" 22 "27.5℃" 21 "27℃" 20 "26.5℃" 19 "26℃" 18 "25.5" 17 "25℃" 16 "24.5℃" 15 "24℃" 14 "23.5℃" 13 "23℃" 12 "22.5℃" 11 "22℃" 10 "21.5℃" 9 "21℃" 8 "20.5℃" 7 "20℃" 6 "19.5℃" 5 "19℃" 4 "18.5℃" 3 "18℃" 2 "17.5℃" 1 "17℃" 0 "TakeNoAction";
VAL_ 2566865433 ACTempLevelCtrl_Slpr 63 "Reserved" 62 "Reserved" 61 "Reserved" 60 "Reserved" 59 "Reserved" 58 "Reserved" 57 "Reserved" 56 "Reserved" 55 "Reserved" 54 "Reserved" 53 "Reserved" 52 "Reserved" 51 "Reserved" 50 "Reserved" 49 "Reserved" 48 "Reserved" 47 "Reserved" 46 "Reserved" 45 "Reserved" 44 "Reserved" 43 "Reserved" 42 "Reserved" 41 "Reserved" 40 "Reserved" 39 "Reserved" 38 "Reserved" 37 "Reserved" 36 "Reserved" 35 "Reserved" 34 "Reserved" 33 "Reserved" 32 "Reserved" 31 "32℃" 30 "31.5℃" 29 "31℃" 28 "30.5℃" 27 "30℃" 26 "29.5℃" 25 "29℃" 24 "28.5℃" 23 "28℃" 22 "27.5℃" 21 "27℃" 20 "26.5℃" 19 "26℃" 18 "25.5" 17 "25℃" 16 "24.5℃" 15 "24℃" 14 "23.5℃" 13 "23℃" 12 "22.5℃" 11 "22℃" 10 "21.5℃" 9 "21℃" 8 "20.5℃" 7 "20℃" 6 "19.5℃" 5 "19℃" 4 "18.5℃" 3 "18℃" 2 "17.5℃" 1 "17℃" 0 "TakeNoAction";
VAL_ 2566865433 ACBlowerLevelDisp_Slpr 15 "Reserved" 14 "Reserved" 13 "Reserved" 12 "Reserved" 11 "Reserved" 10 "Reserved" 9 "Auto" 8 "7" 7 "6" 6 "5" 5 "4" 4 "3" 3 "2" 2 "1" 1 "Off" 0 "TakeNoAction";
VAL_ 2566865433 ACBlowerLevelCtrl_Slpr 15 "Reserved" 14 "Reserved" 13 "Reserved" 12 "Reserved" 11 "Reserved" 10 "Reserved" 9 "Reserved" 8 "7" 7 "6" 6 "5" 5 "4" 4 "3" 3 "2" 2 "1" 1 "Off" 0 "No Cmd";
VAL_ 2566865433 ACTimingRunDisp_Slpr 3 "Reserved" 2 "On" 1 "Off" 0 "TakeNoAction";
VAL_ 2566865433 ACOffDisp_Slpr 3 "Reserved" 2 "On" 1 "Off" 0 "TakeNoAction";
VAL_ 2566865433 ESC_PTC_LowRelayCtrl 3 "Reserved" 2 "Close" 1 "Open" 0 "TakeNoAction";
VAL_ 2566865433 FAN_LowRelayCtrl 3 "Reserved" 2 "Close" 1 "Open" 0 "TakeNoAction";
VAL_ 2566865433 Blower_RelayCtrl 3 "Reserved" 2 "Close" 1 "Open" 0 "TakeNoAction";
VAL_ 2566865433 Blower_RelayCtrl_Slpr 3 "Reserved" 2 "Close" 1 "Open" 0 "TakeNoAction";
VAL_ 2566865433 BattPump_RelayCtrl 3 "Reserved" 2 "Close" 1 "Open" 0 "TakeNoAction";
VAL_ 2566865433 WarmPump_RelayCtrl 3 "Reserved" 2 "Close" 1 "Open" 0 "TakeNoAction";
VAL_ 2566865433 DrivePump_RelayCtrl 3 "Reserved" 2 "Close" 1 "Open" 0 "TakeNoAction";
VAL_ 2566865433 SOVFront_Ctrl 1 "On" 0 "Off";
VAL_ 2566865433 SOVRear_Ctrl 1 "On" 0 "Off";
VAL_ 2566865433 Wasteheat_use_2way_SOV 3 "Reserved" 2 "Close" 1 "Open" 0 "TakeNoAction";
VAL_ 2566865433 Temp_Ambt_Accurate 255 "Invalid";
VAL_ 2566865689 EAC1_ACFrontDefrostSysSts 3 "Reserved" 2 "PotentialFailures" 1 "Fault" 0 "Normal";
VAL_ 2566865689 EAC2_ACFrontDefrostSysSts 3 "Reserved" 2 "PotentialFailures" 1 "Fault" 0 "Normal";
VAL_ 2566867812 EVAP_Sensor_ERR 3 "NotAvailable" 2 "ShortCircuitFault" 1 "OpenCircultFault" 0 "NoError";
VAL_ 2566867812 EVAP_Sensor_Rear_ERR 3 "NotAvailable" 2 "ShortCircuitFault" 1 "OpenCircultFault" 0 "NoError";
VAL_ 2566867812 Temp_Cabin 255 "invild";
VAL_ 2566867812 Temp_Cabin_Slpr 255 "invild";
VAL_ 2566867812 Temp_CabinSensorErr 3 "NotAvailable" 2 "ShortCircuitFault" 1 "OpenCircultFault" 0 "NoError";
VAL_ 2566867812 Temp_CabinSensorErr_Slpr 3 "NotAvailable" 2 "ShortCircuitFault" 1 "OpenCircultFault" 0 "NoError";
VAL_ 2566868068 ESC_PTC_LowRelaySts 1 "Close" 0 "Open";
VAL_ 2566868068 FAN_LowRelaySts 1 "Close" 0 "Open";
VAL_ 2566868068 Blower_RelaySts 1 "Close" 0 "Open";
VAL_ 2566868068 BlowerRelaySts_Slpr 1 "Close" 0 "Open";
VAL_ 2566868068 VIUB_BattPump_RelaySts 1 "Close" 0 "Open";
VAL_ 2566868068 VIUB_WarmPump_RelaySts 1 "Close" 0 "Open";
VAL_ 2566868068 VIUB_DrivePump_RelaySts 1 "Close" 0 "Open";
VAL_ 2566868068 ESC_PTC_LowRelayErr 1 "Error" 0 "NoError";
VAL_ 2566868068 FAN_LowRelayErr 1 "Error" 0 "NoError";
VAL_ 2566868068 Blower_RelayErr 1 "Error" 0 "NoError";
VAL_ 2566868068 Blower_RelayErr_Slpr 1 "Error" 0 "NoError";
VAL_ 2566868068 VIUB_BattPump_RelayErr 1 "Error" 0 "NoError";
VAL_ 2566868068 VIUB_WarmPump_RelayErr 1 "Error" 0 "NoError";
VAL_ 2566868068 VIUB_DrivePump_RelayErr 1 "Error" 0 "NoError";
VAL_ 2566868068 ACModeMotorErr 7 "NotAvailable" 4 "堵转" 3 "过流" 2 "ShortCircuitFault" 1 "OpenCircultFault" 0 "NoError";
VAL_ 2566868068 ACTempMixMotorErr 7 "NotAvailable" 4 "堵转" 3 "过流" 2 "ShortCircuitFault" 1 "OpenCircultFault" 0 "NoError";
VAL_ 2566868068 ACBlowerMotorErr 7 "NotAvailable" 4 "堵转" 3 "过流" 2 "ShortCircuitFault" 1 "OpenCircultFault" 0 "NoError";
VAL_ 2566868068 ACCycleMotorErr 7 "NotAvailable" 4 "堵转" 3 "过流" 2 "ShortCircuitFault" 1 "OpenCircultFault" 0 "NoError";
VAL_ 2566868068 ACTempMixMotorErr_Splr 7 "NotAvailable" 4 "堵转" 3 "过流" 2 "ShortCircuitFault" 1 "OpenCircultFault" 0 "NoError";
VAL_ 2566868068 ACBlowerMotorErr_Splr 7 "NotAvailable" 4 "堵转" 3 "过流" 2 "ShortCircuitFault" 1 "OpenCircultFault" 0 "NoError";
VAL_ 2566868068 ACLonizerErr 3 "NotAvailable" 2 "ShortCircuitFault" 1 "OpenCircultFault" 0 "NoError";
VAL_ 2566870884 SunLightSensorErr 3 "NotAvailable" 2 "ShortCircuitFault" 1 "OpenCircultFault" 0 "NoError";
VAL_ 2566870884 TempSnsrErr_BlowFace 3 "NotAvailable" 2 "ShortCircuitFault" 1 "OpenCircultFault" 0 "NoError";
VAL_ 2566870884 TempSnsrErr__BlowFoot 3 "NotAvailable" 2 "ShortCircuitFault" 1 "OpenCircultFault" 0 "NoError";
VAL_ 2566870884 TempSnsrErr_SplrOutlet 3 "NotAvailable" 2 "ShortCircuitFault" 1 "OpenCircultFault" 0 "NoError";
VAL_ 2566871140 PT2SensorErr 7 "Reserved" 6 "Reserved" 5 "NotAvailable" 4 "PrsrShortCircuitFault" 3 "PrsrOpenCircultFault" 2 "TempShortCircuitFault" 1 "TempOpenCircultFault" 0 "NoError";
VAL_ 2566871140 PT3SensorErr 7 "Reserved" 6 "Reserved" 5 "NotAvailable" 4 "PrsrShortCircuitFault" 3 "PrsrOpenCircultFault" 2 "TempShortCircuitFault" 1 "TempOpenCircultFault" 0 "NoError";
VAL_ 2566909028 ACTempMixMotorSts_1 3 "Reserved" 2 "反转" 1 "正转" 0 "No action";
VAL_ 2566909028 ACModeMotorSts_1 3 "Reserved" 2 "反转" 1 "正转" 0 "No action";
VAL_ 2566909028 ACAirPurgeOutputSts 3 "Reserved" 2 "On" 1 "Off" 0 "No action";
VAL_ 2566909028 ACLonizerOutputFeedback 3 "Reserved" 2 "On" 1 "Off" 0 "No action";
VAL_ 2566909028 ACAirPurgeOutputFeedback 3 "Reserved" 2 "On" 1 "Off" 0 "No action";
VAL_ 2566909028 ACLonizerOutputSts 3 "Reserved" 2 "On" 1 "Off" 0 "No action";
VAL_ 2566908772 ACCycleMotorSts_2 3 "Reserved" 2 "反转" 1 "正转" 0 "No action";
VAL_ 2566908772 ACTempMixMotorSts_Splr_2 3 "Reserved" 2 "反转" 1 "正转" 0 "No action";
VAL_ 2566866021 LFAN1_Err 3 "NotAvailable" 2 "ShortCircuitFault" 1 "OpenCircultFault" 0 "NoError";
VAL_ 2566866021 DrivePumpErr 3 "过流" 2 "空转" 1 "堵转" 0 "NoError";
VAL_ 2566866021 BattPumpErr 3 "过流" 2 "空转" 1 "堵转" 0 "NoError";
VAL_ 2566866021 WasteHeatReusedErr 3 "NotAvailable" 2 "ShortCircuitFault" 1 "OpenCircultFault" 0 "NoError";
VAL_ 2566866021 WasteHeatReusedSts 1 "On" 0 "Off";
VAL_ 2566867557 LFAN2_Err 3 "NotAvailable" 2 "ShortCircuitFault" 1 "OpenCircultFault" 0 "NoError";
VAL_ 2566867557 LFAN3_Err 3 "NotAvailable" 2 "ShortCircuitFault" 1 "OpenCircultFault" 0 "NoError";
VAL_ 2566867557 LFAN4_Err 3 "NotAvailable" 2 "ShortCircuitFault" 1 "OpenCircultFault" 0 "NoError";
VAL_ 2566867557 WarmPumpErr 3 "过流" 2 "空转" 1 "堵转" 0 "NoError";
VAL_ 2566871397 TempAmbtErr 3 "NotAvailable" 2 "ShortCircuitFault" 1 "OpenCircultFault" 0 "NoError";
VAL_ 2566871397 TempSensorErr_Batt1Inlet 3 "NotAvailable" 2 "ShortCircuitFault" 1 "OpenCircultFault" 0 "NoError";
VAL_ 2566871397 TempSensorErr_MotorIntlet 3 "NotAvailable" 2 "ShortCircuitFault" 1 "OpenCircultFault" 0 "NoError";
VAL_ 2566871397 TempSensorErr_BattChiller1Outlet 3 "NotAvailable" 2 "ShortCircuitFault" 1 "OpenCircultFault" 0 "NoError";
VAL_ 2566871397 TempSensorErr_BattChiller2Outlet 3 "NotAvailable" 2 "ShortCircuitFault" 1 "OpenCircultFault" 0 "NoError";
VAL_ 2566871653 PT1SensorErr 7 "Reserved" 6 "Reserved" 5 "NotAvailable" 4 "PrsrShortCircuitFault" 3 "PrsrOpenCircultFault" 2 "TempShortCircuitFault" 1 "TempOpenCircultFault" 0 "NoError";
VAL_ 2566871653 PT4SensorErr 7 "Reserved" 6 "Reserved" 5 "NotAvailable" 4 "PrsrShortCircuitFault" 3 "PrsrOpenCircultFault" 2 "TempShortCircuitFault" 1 "TempOpenCircultFault" 0 "NoError";
VAL_ 2566871909 MidPressure1Sts 1 "Open" 0 "Close";
VAL_ 2566871909 HighPressure1Sts 3 "Reserved" 2 "Reserved" 1 "OverHigh or OverLow" 0 "Normal";
VAL_ 2566871909 MidPressure2Sts 1 "Open" 0 "Close";
VAL_ 2566871909 HighPressure2Sts 3 "Reserved" 2 "Reserved" 1 "OverHigh or OverLow" 0 "Normal";
VAL_ 2566871909 MidPressure3Sts 1 "Open" 0 "Close";
VAL_ 2566871909 HighPressure3Sts 3 "Reserved" 2 "Reserved" 1 "OverHigh or OverLow" 0 "Normal";
VAL_ 2566871909 HighPressure1Err 1 "Error" 0 "No  Error";
VAL_ 2566871909 HighPressure2Err 1 "Error" 0 "No  Error";
VAL_ 2566871909 HighPressure3Err 1 "Error" 0 "No  Error";
VAL_ 2566871909 LevelSwt1Cmd 1 "Open" 0 "Close";
VAL_ 2566871909 LevelSwt2Cmd 1 "Open" 0 "Close";
VAL_ 2566871909 LevelSwt3Cmd 1 "Open" 0 "Close";
VAL_ 2566871909 LevelSwt4Cmd 1 "Open" 0 "Close";
VAL_ 2566871909 LevelSwt1Err 1 "Error" 0 "NoError";
VAL_ 2566871909 LevelSwt2Err 1 "Error" 0 "NoError";
VAL_ 2566871909 LevelSwt3Err 1 "Error" 0 "NoError";
VAL_ 2566871909 LevelSwt4Err 1 "Error" 0 "NoError";
VAL_ 2566871909 BattPump_Err 3 "PumpFault水泵自身故障" 2 "Pump OpenCircuit开路" 1 "Pump Idling空转" 0 "Normal";
VAL_ 2566871909 MotorPump_Err 3 "PumpFault水泵自身故障" 2 "Pump OpenCircuit开路" 1 "Pump Idling空转" 0 "Normal";
VAL_ 2566871909 xxxPump_Err 3 "PumpFault水泵自身故障" 2 "Pump OpenCircuit开路" 1 "Pump Idling空转" 0 "Normal";
VAL_ 2566871909 VIUC_BattPump_RelaySts 1 "Close" 0 "Open";
VAL_ 2566871909 VIUC_WarmPump_RelaySts 1 "Close" 0 "Open";
VAL_ 2566871909 VIUC_DrivePump_RelaySts 1 "Close" 0 "Open";
VAL_ 2566871909 VIUC_BattPump_RelayErr 1 "Error" 0 "NoError";
VAL_ 2566871909 VIUC_WarmPump_RelayErr 1 "Error" 0 "NoError";
VAL_ 2566871909 VIUC_DrivePump_RelayErr 1 "Error" 0 "NoError";
VAL_ 2566907943 ValidDKM 1 "Valid" 0 "Invalid";
VAL_ 2566858223 VBUS_VCU7_BiOBC_HVIL_Err 1 "故障" 0 "正常";
VAL_ 2566858223 VBUS_VCU7_HVAccS_HVIL_Err 1 "故障" 0 "正常";
VAL_ 2566858223 VBUS_VCU7_Gear1_Indicator 1 "显示文字“车速过高，已启用N挡，请重新挂挡”" 0 "不显示";
VAL_ 2566858223 VBUS_VCU7_BRAKE_ENGERY_RECOV_LEVEL 7 "void" 6 "恒速挡" 5 "5挡辅助制动能量回收" 4 "4挡辅助制动能量回收" 3 "3挡辅助制动能量回收" 2 "2挡辅助制动能量回收" 1 "1挡辅助制动能量回收" 0 "未设置";
VAL_ 2566858223 VBUS_VCU7_Restricted_Warning 7 "void" 6 "void" 5 "void" 4 "锁车命令已执行，限速20km/h" 3 "防拆策略已执行，限速20km/h" 2 "解锁命令执行，将在车辆下一次启动时执行" 1 "锁车命令执行，将在车辆下一次启动时执行" 0 "默认值";
VAL_ 2566858223 VBUS_VCU7_St_LV_Chrg 3 "void" 2 "void" 1 "补电中" 0 "未进行补电";
VAL_ 2566858223 VBUS_VCU7_IMCUO_422_ready 1 "使能打开（ready）" 0 "使能关闭（not ready）";
VAL_ 2566858223 VBUS_VCU7_MTCU_HVIL_Err 1 "故障" 0 "正常";
VAL_ 2566858223 VBUS_VCU7_PDU_HVIL_Err 1 "故障" 0 "正常";
VAL_ 2566858223 VBUS_VCU7_BATT_HVIL_Err 1 "故障" 0 "正常";
VAL_ 2566858223 VBUS_VCU7_FUELCELL_HVIL_Err 1 "故障" 0 "正常";
VAL_ 2566858223 VBUS_VCU7_ADCAC_BRAKE_EN_CMD 1 "Enable" 0 "Disable";
VAL_ 2566858223 VBUS_VCU7_IMCUA_420_ready 1 "使能打开" 0 "使能关闭";
VAL_ 2566858223 VBUS_VCU7_FAULT_IMCUO 1 "故障" 0 "正常";
VAL_ 2566853359 VBUS_VCU4_St_Gears 3 "保留" 2 "R" 1 "D" 0 "N";
VAL_ 2566853359 VBUS_VCU4_St_Ready 1 "ready" 0 "not ready";
VAL_ 2566853359 VBUS_VCU4_St_Vehicle 3 "致命故障（闪烁蜂鸣）" 2 "严重故障（红灯闪烁）" 1 "一般故障（红灯常亮）" 0 "正常;";
VAL_ 2566853359 VBUS_VCU4_St_Interlocking 1 "互锁" 0 "非互锁";
VAL_ 2566853359 VBUS_VCU4_St_ShiftGearBrkOn 1 "换挡未踩制动" 0 "换挡已踩制动";
VAL_ 2566853359 VBUS_VCU4_F_ShiftGears 1 "换挡不成功，挡位指示闪烁" 0 "正常，不闪烁";
VAL_ 2566853359 VBUS_VCU4_F_Motor 1 "故障" 0 "正常";
VAL_ 2566853359 VBUS_VCU4_F_MotorOverTemp 1 "故障" 0 "正常";
VAL_ 2566853359 VBUS_VCU4_St_DISCHARGE_STA 3 "void" 2 "void" 1 "正在放电" 0 "非放电状态";
VAL_ 2566853359 VBUS_VCU4_St_BrakeSta 1 "已踩制动踏板" 0 "未踩制动踏板";
VAL_ 2566853359 VBUS_VCU4_St_Thermal_runaway 1 "故障" 0 "正常";
VAL_ 2566873957 TurnLightSts_LR 1 "Lamp On" 0 "Lamp Off";
VAL_ 2566873957 TurnLightFltMode_LR 3 "Underloading" 2 "Breaking" 1 "Short out" 0 "Normal";
VAL_ 2566873957 TurnLightSts_RR 1 "Lamp On" 0 "Lamp Off";
VAL_ 2566873957 TurnLightFltMode_RR 3 "Underloading" 2 "Breaking" 1 "Short out" 0 "Normal";
VAL_ 2566873957 MainReverseLampSts 1 "Lamp On" 0 "Lamp Off";
VAL_ 2566873957 TrailerReverseLampSts 1 "Lamp On" 0 "Lamp Off";
VAL_ 2566873957 MainReverseLampFltMode 3 "Underloading" 2 "Breaking" 1 "Short out" 0 "Normal";
VAL_ 2566873957 TrailerReverseLampFltMode 3 "Underloading" 2 "Breaking" 1 "Short out" 0 "Normal";
VAL_ 2566873957 TrailerSts 1 "Trailer On；" 0 "Trailer Off";
VAL_ 2566873957 RearPositionLightSts_L 1 "Lamp On" 0 "Lamp Off";
VAL_ 2566873957 RearPositionLighFltMode_L 3 "Underloading" 2 "Breaking" 1 "Short out" 0 "Normal";
VAL_ 2566873957 RearPositionLightSts_R 1 "Lamp On" 0 "Lamp Off";
VAL_ 2566873957 RearPositionLighFltMode_R 3 "Underloading" 2 "Breaking" 1 "Short out" 0 "Normal";
VAL_ 2566873957 RearHeadlightSts 1 "Lamp On" 0 "Lamp Off";
VAL_ 2566873957 RearHeadlightFltMode 3 "Underloading" 2 "Breaking" 1 "Short out" 0 "Normal";
VAL_ 2566873957 TrailerABSAlarm 3 "not used" 2 "reserved" 1 "alarm" 0 "no alarm";
VAL_ 2566873957 TurnLightSts_TL 1 "Lamp On" 0 "Lamp Off";
VAL_ 2566873957 TurnLightFltMode_TL 3 "Underloading" 2 "Breaking" 1 "Short out" 0 "Normal";
VAL_ 2566873957 TurnLightSts_TR 1 "Lamp On" 0 "Lamp Off";
VAL_ 2566873957 TurnLightFltMode_TR 3 "Underloading" 2 "Breaking" 1 "Short out" 0 "Normal";
VAL_ 2566873957 RearPositionLightSts_TL 1 "On" 0 "Off";
VAL_ 2566873957 RearPositionLightSts_TR 1 "On" 0 "Off";
VAL_ 2566859824 Force_Reblow_Mode 3 "流域" 2 "预留" 1 "表示进入模式" 0 "未进入模式";
VAL_ 2566859824 Intelgent_AirSuply_Mode 3 "预留" 2 "模式异常" 1 "进入模式；" 0 "未进入模式；";
VAL_ 2566859824 Exhaust_RelayEnable 1 "使能" 0 "未使能";
VAL_ 2566859824 Reblow_RelayEnable 1 "使能" 0 "未使能";
VAL_ 2566859824 Air_Susp_Set 1 "配置此功能" 0 "未配置此功能";
VAL_ 2566859824 Air_Susp_Mode 3 "预留" 2 "模式异常" 1 "进入模式；" 0 "未进入模式；";
VAL_ 2566859824 Heat_RelayEnable 0 "未使能，0x1:使能";
VAL_ 2566859824 LowTemp_Protect_Set 1 "配置此功能" 0 "未配置此功能";
VAL_ 2566859824 LowTemp_Protect_Mode 3 "预留" 2 "模式异常" 1 "进入模式；" 0 "未进入模式；";
VAL_ 2566859824 Invalid_Mode 1 "进入此模式" 0 "未进入此模式";
VAL_ 2566859824 Error_Level 3 "三级故障" 2 "二级故障" 1 "一级故障" 0 "无故障";
VAL_ 2566859824 Normal_Err 1 "故障" 0 "无故障";
VAL_ 2566859824 Serious_Err 0 "无故障 0x1:故障";
VAL_ 2566859824 DryTank_ChangedRemind 1 "需要更换" 0 "无须更换";
VAL_ 2566893413 VIUC_ACFrontDefrostSysSts 3 "Reserved" 2 "PotentialFailures" 1 "Fault" 0 "Normal";
VAL_ 2566903909 BrkliningWearAlrm_FLW 3 "NotAvailable" 2 "Reserved" 1 "warning" 0 "not warning";
VAL_ 2566903909 BrkliningWearAlrm_FRW 3 "NotAvailable" 2 "Reserved" 1 "warning" 0 "not warning";
VAL_ 2566903909 BrkliningWearAlrm_MLW 3 "NotAvailable" 2 "Reserved" 1 "warning" 0 "not warning";
VAL_ 2566903909 BrkliningWearAlrm_MRW 3 "NotAvailable" 2 "Reserved" 1 "warning" 0 "not warning";
VAL_ 2566903909 BrkliningWearAlrm_RLW 3 "NotAvailable" 2 "Reserved" 1 "warning" 0 "not warning";
VAL_ 2566903909 BrkliningWearAlrm_RRW 3 "NotAvailable" 2 "Reserved" 1 "warning" 0 "not warning";
VAL_ 2566903653 Front_AirPrs_Alarm 3 "NotAvailable" 2 "报警/前桥气压过高报警" 1 "报警/前桥气压过低报警" 0 "正常";
VAL_ 2566903653 Rear_AirPrs_Alarm 3 "NotAvailable" 2 "报警/后桥气压过高报警" 1 "报警/后桥气压过低报警" 0 "正常";
VAL_ 2566903653 ParkBreakPressureAlarm 3 "NotAvailable" 2 "Reserved" 1 "报警/后桥气压过低报警" 0 "正常";
VAL_ 2566903653 AirFilterBlocking 3 "NotAvailable" 2 "Reserved" 1 "Block；" 0 "Not block；";
VAL_ 2566903653 AirFilterBlockageAlarm 3 "NotAvailable" 2 "Reserved" 1 "warning" 0 "not warning";
VAL_ 2566903653 BrkliningTempAlarm_FLW 7 "not available" 6 "- reserved" 5 "- reserved" 4 "- reserved" 3 "Not available or Not inst~0xFFed  温度报警信号丢失或功能未安装" 2 "fadig yellow warning active 温度预警激活" 1 "fadig red warning active 温度报警激活" 0 "fadig warning not active 温度报警未激活";
VAL_ 2566903653 BrkliningTempAlarm_FRW 7 "not available" 6 "- reserved" 5 "- reserved" 4 "- reserved" 3 "Not available or Not inst~0xFFed  温度报警信号丢失或功能未安装" 2 "fadig yellow warning active 温度预警激活" 1 "fadig red warning active 温度报警激活" 0 "fadig warning not active 温度报警未激活";
VAL_ 2566903653 Braketemperature_MLW 7 "not available" 6 "- reserved" 5 "- reserved" 4 "- reserved" 3 "Not available or Not inst~0xFFed  温度报警信号丢失或功能未安装" 2 "fadig yellow warning active 温度预警激活" 1 "fadig red warning active 温度报警激活" 0 "fadig warning not active 温度报警未激活";
VAL_ 2566903653 Braketemperature_MRW 7 "not available" 6 "- reserved" 5 "- reserved" 4 "- reserved" 3 "Not available or Not inst~0xFFed  温度报警信号丢失或功能未安装" 2 "fadig yellow warning active 温度预警激活" 1 "fadig red warning active 温度报警激活" 0 "fadig warning not active 温度报警未激活";
VAL_ 2566903653 Braketemperature_RLW 7 "not available" 6 "- reserved" 5 "- reserved" 4 "- reserved" 3 "Not available or Not inst~0xFFed  温度报警信号丢失或功能未安装" 2 "fadig yellow warning active 温度预警激活" 1 "fadig red warning active 温度报警激活" 0 "fadig warning not active 温度报警未激活";
VAL_ 2566903653 Braketemperature_RRW 7 "not available" 6 "- reserved" 5 "- reserved" 4 "- reserved" 3 "Not available or Not inst~0xFFed  温度报警信号丢失或功能未安装" 2 "fadig yellow warning active 温度预警激活" 1 "fadig red warning active 温度报警激活" 0 "fadig warning not active 温度报警未激活";
VAL_ 2566893351 LowBeamFltWarn_VDCU 3 "预留" 2 "潜伏故障；" 1 "单点故障；" 0 "正常；";
VAL_ 2566893351 MainBrkLightFltWarn_VDCU 3 "预留" 2 "潜伏故障；" 1 "单点故障；" 0 "正常；";
VAL_ 2566893351 TrailerBrkLightFltWarn_VDCU 3 "预留" 2 "潜伏故障；" 1 "单点故障；" 0 "正常；";
VAL_ 2566893351 HighBeamFltWarn_VDCU 3 "预留" 2 "潜伏故障；" 1 "单点故障；" 0 "正常；";
VAL_ 2566893351 OvertakinglampWarn_VDCU 3 "预留" 2 "潜伏故障；" 1 "单点故障；" 0 "正常；";
VAL_ 2566893351 FrontOperatorWiperFltWarn_VDCU 3 "预留" 2 "潜伏故障；" 1 "单点故障；" 0 "正常；";
VAL_ 2566893351 WinCtrlFlt_Drvr_VDCU 3 "预留" 2 "潜伏故障；" 1 "单点故障；" 0 "正常；";
VAL_ 2566893351 WinCtrlFlt_Pass_VDCU 3 "预留" 2 "潜伏故障；" 1 "单点故障；" 0 "正常；";
VAL_ 2566893351 VDCU_ACFrontDefrostSysSts 3 "Reserved" 2 "PotentialFailures" 1 "Fault" 0 "Normal";
VAL_ 2566893351 LowPowerModeWarn_VDCU 3 "预留" 2 "潜伏故障；" 1 "单点故障；" 0 "正常；";
VAL_ 2365522727 CertificationSts_VDCU 1 "SendRandomData" 0 "No action";
VAL_ 2566861351 LeftTurnLightReq 15 "Invalid" 6 "寻车灯语" 5 "RemoteUnlock(解锁灯语)" 4 "RemoteLock(闭锁灯语)" 3 "变道灯语（预留）" 1 "On Normal(正常)（转向和危报）；" 0 "No Operation/OFF";
VAL_ 2566861351 RightTurnLightReq 15 "Invalid" 6 "寻车灯语" 5 "RemoteUnlock(解锁灯语)" 4 "RemoteLock(闭锁灯语)" 3 "变道灯语（预留）" 1 "On Normal(正常)（转向和危报）；" 0 "No Operation/OFF";
VAL_ 2566861351 HzrdLightReq 1 "Hazard(危报灯激活)" 0 "No Hazard(危报灯未激活)";
VAL_ 2566861351 LowBeamReq 1 "ON" 0 "OFF";
VAL_ 2566861351 HighBeamReq 1 "ON" 0 "OFF";
VAL_ 2566861351 ReverseLampReq 1 "ON" 0 "OFF";
VAL_ 2566861351 MainBrkLightReq 2 "Lamp Flash" 1 "Lamp On" 0 "Lamp Off";
VAL_ 2566861351 TrailerBrkLightReq 2 "Lamp Flash" 1 "Lamp On" 0 "Lamp Off";
VAL_ 2566861351 PosnLigjtReq 1 "ON" 0 "OFF";
VAL_ 2566861351 BacklightAdjustReq 10 "输出50Hz（TBD）占空比30%~100%波形；" 9 "输出50Hz（TBD）占空比30%~100%波形；" 8 "输出50Hz（TBD）占空比30%~100%波形；" 7 "输出50Hz（TBD）占空比30%~100%波形；" 6 "输出50Hz（TBD）占空比30%~100%波形；" 5 "输出50Hz（TBD）占空比30%~100%波形；" 4 "输出50Hz（TBD）占空比30%~100%波形；" 3 "输出50Hz（TBD）占空比30%~100%波形；" 2 "输出50Hz（TBD）占空比20%波形；" 1 "输出50Hz（TBD）占空比10%波形；" 0 "Invalid(Not Request)";
VAL_ 2566861351 LeftDayTimeRunngLiReq 1 "ON" 0 "off";
VAL_ 2566861351 RightDayTimeRunngLiReq 1 "ON" 0 "off";
VAL_ 2566861351 RearFogLampReq 1 "ON" 0 "off";
VAL_ 2566861351 RearFogLampReplcmtReq 1 "ON" 0 "OFF";
VAL_ 2566861351 LanternLanguageReq 15 "NotAvailable" 14 "Reserve" 13 "Reserve" 12 "Reserve" 11 "Reserve" 10 "Reserve" 9 "Reserve" 8 "Reserve" 7 "Reserve" 6 "Type6" 5 "Type5" 4 "Type4" 3 "Type3" 2 "Type2" 1 "Type1" 0 "OFF";
VAL_ 2566861351 IVI_FrontFogLampLinkageSetFB 1 "联动" 0 "无联动";
VAL_ 2566861351 LampFollowMeHomeSetSts 3 "90s" 2 "60s" 1 "30s" 0 "OFF";
VAL_ 2566861351 LampAwayHomeSetSts 3 "90s" 2 "60s" 1 "30s" 0 "OFF";
VAL_ 2566861351 ExtrMirrHeatCtrl 2 "ExtrMirrHeatOn" 1 "ExtrMirrHeatOff" 0 "No Req";
VAL_ 2566861351 ExtrMirrDirAdjmtCtrl_L 4 "TurnRight" 3 "TurnLeft" 2 "TurnDown" 1 "TurnUp" 0 "No Cmd";
VAL_ 2566861351 ExtrMirrDirAdjmtCtrl_R 4 "TurnRight" 3 "TurnLeft" 2 "TurnDown" 1 "TurnUp" 0 "No Cmd";
VAL_ 2566861351 FrontFogLampReq_L 1 "ON" 0 "off";
VAL_ 2566861351 FrontFogLampReq_R 1 "ON" 0 "off";
VAL_ 2566861607 WinReq_L 3 "无效" 2 "Driver Window down" 1 "Driver Window up" 0 "Driver Window Not Moving";
VAL_ 2566861607 WinReq_R 3 "无效" 2 "Passenger Window down" 1 "Passenger Window up" 0 "Passenger Window Not Moving";
VAL_ 2566861607 WasherReq 3 "无效" 2 "Error" 1 "喷淋电机驱动请求" 0 "NOT REQUEST";
VAL_ 2566861607 WiperReq 7 "预留" 6 "预留" 5 "预留" 4 "预留" 3 "雨刮间歇驱动请求（500ms或2帧）" 2 "雨刮高速驱动请求" 1 "雨刮低速驱动请求" 0 "NOT REQUEST";
VAL_ 2566861607 OutIncrWinAntAlarm 1 "Warning" 0 "No warning";
VAL_ 2566861607 StartStopButtonLiReq 2 "Yellow" 1 "Green" 0 "不驱动";
VAL_ 2566861607 RelayReq_ACC 1 "ON" 0 "OFF";
VAL_ 2566861607 RelayReq_IG1 1 "ON" 0 "OFF";
VAL_ 2566861607 RelayReq_IG2 1 "ON" 0 "OFF";
VAL_ 2566861607 CrankReq 1 "Active" 0 "Inactive";
VAL_ 2566861607 RelaySts_ACC 1 "Active" 0 "Inactive";
VAL_ 2566861607 RelaySts_IG1 1 "Active" 0 "Inactive";
VAL_ 2566861607 RelaySts_IG2 1 "Active" 0 "Inactive";
VAL_ 2566861607 LowPowerMode 15 "Signal Invalid" 14 "Reserved" 13 "Reserved" 12 "Reserved" 11 "Reserved" 10 "Reserved" 9 "Reserved" 8 "Reserved" 7 "Reserved" 6 "Reserved" 5 "Reserved" 4 "Start" 3 "ON" 2 "Reserved" 1 "OFF" 0 "Initial";
VAL_ 2566861607 RmtLowPowerMode 1 "有效" 0 "无效";
VAL_ 2566861607 RainCloseWinSwt_Fb 3 "无效" 2 "Error" 1 "ON" 0 "OFF";
VAL_ 2566861607 RmtLocaloutreq_VDCU 3 "Reserved" 2 "Reserved" 1 "本地事件触发" 0 "NOT REQUEST";
VAL_ 2566861607 BluetoothKeyConnect 3 "Reserve" 2 "安全连接" 1 "物理连接" 0 "未连接";
VAL_ 2566861607 BluetoothKeyLocation 4 "out car（除PE区）" 3 "PE（副驾侧）" 2 "PE（主驾侧）" 1 "PS（车内）" 0 "Invalid";
VAL_ 2566861607 BluetoothKeyReq 15 "Signal Invalid" 14 "Reserved" 13 "Reserved" 12 "Reserved" 11 "Reserved" 10 "Reserved" 9 "Reserved" 8 "Reserved" 7 "Reserved" 6 "Lamp Inspection" 5 "Searching Car" 4 "Auto Window Down" 3 "Auto Window Up" 2 "Lock" 1 "Unlock" 0 "Initial";
VAL_ 2566861607 BluetoothPhoneConnect 3 "Reserve" 2 "Reserve" 1 "已连接" 0 "未连接";
VAL_ 2566861607 PrimaryAntennaSleepSts 3 "Connection3:TBD" 2 "Connection2:Connection mode；" 1 "sleep:Sleep mode；" 0 "Connection1:position mode；";
VAL_ 2566907443 Wheel_Location_ID 255 "invalid" 254 "invalid" 253 "invalid" 252 "invalid" 251 "invalid" 250 "invalid" 249 "invalid" 248 "invalid" 247 "invalid" 246 "invalid" 245 "invalid" 244 "invalid" 243 "invalid" 242 "invalid" 241 "invalid" 240 "invalid" 239 "invalid" 238 "invalid" 237 "invalid" 236 "invalid" 235 "invalid" 234 "invalid" 233 "invalid" 232 "invalid" 231 "invalid" 230 "invalid" 229 "invalid" 228 "invalid" 227 "invalid" 226 "invalid" 225 "invalid" 224 "invalid" 223 "invalid" 222 "invalid" 221 "invalid" 220 "invalid" 219 "invalid" 218 "invalid" 217 "invalid" 216 "invalid" 215 "invalid" 214 "invalid" 213 "invalid" 212 "invalid" 211 "invalid" 210 "invalid" 209 "invalid" 208 "invalid" 207 "invalid" 206 "invalid" 205 "invalid" 204 "invalid" 203 "invalid" 202 "invalid" 201 "invalid" 200 "invalid" 199 "invalid" 198 "invalid" 197 "invalid" 196 "invalid" 195 "invalid" 194 "invalid" 193 "invalid" 192 "invalid" 191 "invalid" 190 "invalid" 189 "invalid" 188 "invalid" 187 "invalid" 186 "invalid" 185 "invalid" 184 "invalid" 183 "invalid" 182 "invalid" 181 "invalid" 180 "invalid" 179 "invalid" 178 "invalid" 177 "invalid" 176 "invalid" 175 "invalid" 174 "invalid" 173 "invalid" 172 "invalid" 171 "invalid" 170 "invalid" 169 "invalid" 168 "invalid" 167 "invalid" 166 "invalid" 165 "invalid" 164 "invalid" 163 "invalid" 162 "invalid" 161 "invalid" 160 "invalid" 159 "invalid" 158 "invalid" 157 "invalid" 156 "invalid" 155 "invalid" 154 "invalid" 153 "invalid" 152 "invalid" 151 "invalid" 150 "invalid" 149 "invalid" 148 "invalid" 147 "invalid" 146 "invalid" 145 "invalid" 144 "invalid" 143 "invalid" 142 "invalid" 141 "invalid" 140 "invalid" 139 "invalid" 138 "invalid" 137 "invalid" 136 "invalid" 135 "invalid" 134 "invalid" 133 "invalid" 132 "invalid" 131 "invalid" 130 "invalid" 129 "invalid" 128 "invalid" 127 "invalid" 126 "invalid" 125 "invalid" 124 "invalid" 123 "invalid" 122 "invalid" 121 "invalid" 120 "invalid" 119 "invalid" 118 "invalid" 117 "invalid" 116 "invalid" 115 "invalid" 114 "invalid" 113 "invalid" 112 "invalid" 111 "invalid" 110 "invalid" 109 "invalid" 108 "invalid" 107 "invalid" 106 "invalid" 105 "invalid" 104 "invalid" 103 "invalid" 102 "invalid" 101 "invalid" 100 "invalid" 99 "invalid" 98 "invalid" 97 "invalid" 96 "invalid" 95 "invalid" 94 "invalid" 93 "invalid" 92 "invalid" 91 "invalid" 90 "invalid" 89 "invalid" 88 "invalid" 87 "invalid" 86 "invalid" 85 "invalid" 84 "invalid" 83 "invalid" 82 "invalid" 81 "invalid" 80 "invalid" 79 "invalid" 78 "invalid" 77 "invalid" 76 "invalid" 75 "invalid" 74 "axle 4 OR" 73 "axle 4 IR" 71 "axle 4 IL" 70 "axle 4 OL" 58 "axle 3 OR" 57 "axle 3 IR" 55 "axle 3 IL" 54 "axle 3 OL" 42 "axle 2 OR（Outside Right）" 41 "axle 2 IR" 39 "axle 2 IL" 38 "axle 2 OL（Outside Left）" 25 "axle 1 IR（Inside Right）" 23 "axle 1 IL（Inside Left）";
VAL_ 2566907443 Tyre_Temperature 255 "invalid" 254 "Error" 253 "Reserved" 252 "Reserved" 251 "Reserved" 250 "210℃ or Overflow";
VAL_ 2566907443 Tyre_Pressure 1023 "invalid" 1022 "Error" 1021 "Reserved" 1020 "Reserved" 1019 "Function Not Supported" 1018 "2036kPa or Overflow";
VAL_ 2566907443 WU_Battery_Status 15 "invalid" 14 "Error" 13 "SignalNotSupported" 12 "SignalNotSupported" 11 "SignalNotSupported" 10 "<=100%" 9 "<=90%" 8 "<=80%" 7 "<=70%" 6 "<=60%" 5 "<=50%" 4 "<=40%" 3 "<=30%" 2 "<=20%" 1 "<=10%" 0 "Reserved";
VAL_ 2566907443 Tyre_LearnStatus 7 "Reserved" 6 "Reserved" 5 "Reserved" 4 "失败" 3 "完成" 2 "进行中" 1 "启动" 0 "未启动";
VAL_ 2566907443 Tyre_SensorLose_warning 3 "Reserved" 2 "Error" 1 "Warning" 0 "Not warning";
VAL_ 2566907443 Tyre_Learn 3 "Reserved" 2 "漏气学习" 1 "低频设备学习" 0 "Invalid";
VAL_ 2566907443 Tyre_SensorLowBatt_warning 3 "Reserved" 2 "Error" 1 "Warning" 0 "Not warning";
VAL_ 2566907443 Tyre_Pressure_Status 15 "invalid" 14 "Error" 13 "Signal Not Supported" 12 "Not defined" 11 "Not defined" 10 "Not defined" 9 "Not defined" 8 "Not defined" 7 "Not defined" 6 "Reserved" 5 "Under pressure" 4 "Reserved" 3 "Reserved" 2 "Over pressure" 1 "Reserved" 0 "Nominal pressure range";
VAL_ 2566907443 Tyre_Over_Temp_Status 3 "invalid" 2 "Error" 1 "TireOverTempEventDetected" 0 "NoTireOverTempEventDetected";
VAL_ 2566907443 Sensor_ID_Prog_Status 3 "invalid" 2 "Error" 1 "SensorNotProgrammed" 0 "SensorProgrammed";
VAL_ 2566907955 MLS_Page 15 "Reserved" 14 "Reserved" 13 "Reserved" 12 "Reserved" 11 "Reserved" 10 "Reserved" 9 "Reserved" 8 "Reserved" 7 "Reserved" 6 "Reserved" 5 "Reserved" 4 "Reserved" 3 "Reserved" 2 "Reserved" 1 "Reserved" 0 "Field definations as defined";
VAL_ 2566907955 MLS_truck_trailer 3 "Reserved" 2 "Reserved" 1 "trailer use" 0 "tractor use";
VAL_ 2566907955 MLS 15 "Reserved" 14 "Reserved" 13 "Reserved" 12 "Reserved" 11 "Reserved" 10 "Reserved" 9 "Reserved" 8 "Reserved" 7 "Reserved" 6 "Reserved" 5 "Reserved" 4 "Reserved" 3 "Reserved" 2 "Active" 1 "Inactive" 0 "Not request";
VAL_ 2566907955 MLS_Tyre_Loc 58 "Location 0x3A-axle 3 OR" 57 "Location 0x39-axle 3 IR" 25 "Location 0x19-axle 1 IR" 55 "Location 0x37-axle 3 IL" 23 "Location 0x17-axle 1 IL" 54 "Location 0x36-axle 3 OL" 74 "Location 0x4A-axle 4 OR" 42 "Location 0x2A-axle 2 OR" 73 "Location 0x49-axle 4 IR" 41 "Location 0x29-axle 2 IR" 71 "Location 0x47-axle 4 IL" 39 "Location 0x27-axle 2 IL" 70 "Location 0x46-axle 4 OL" 38 "Location 0x26-axle 2 OL";
VAL_ 2348876549 TransmissionRequestedGear 5 "~0xF:无效" 4 "向下2档" 3 "向上2档" 2 "向下1档" 1 "向上1档" 0 "Not request";
VAL_ 2348876549 AssistedbrakingSwt 7 "Not available" 6 "error" 5 "5档" 4 "4档" 3 "3档" 2 "2档" 1 "1档" 0 "No command";
VAL_ 2348876549 TransmissionRequestedGearflag 3 "Not available" 2 "有效" 1 "reserved" 0 "reserved";
VAL_ 2566893317 HighBeamFltWarn_GSM 3 "预留" 2 "潜伏故障；" 1 "单点故障；" 0 "正常；";
VAL_ 2566893317 OvertakinglampWarn_GSM 3 "预留" 2 "潜伏故障；" 1 "单点故障；" 0 "正常；";
VAL_ 2566893317 FrontOperatorWiperFltWarn_GSM 3 "预留" 2 "潜伏故障；" 1 "单点故障；" 0 "正常；";
VAL_ 2566893317 ShiftFltWarn_GSM 3 "预留" 2 "潜伏故障；" 1 "单点故障；" 0 "正常；";
VAL_ 2365443105 TurnSignalSwt 15 "Not available(do not change)" 14 "Error" 13 "reserved" 12 "reserved" 11 "reserved" 10 "reserved" 9 "reserved" 8 "reserved" 7 "reserved" 6 "reserved" 5 "reserved" 4 "reserved" 3 "reserved" 2 "right turn to be flashing" 1 "Left turn to be flashing" 0 "No Turn being signaled";
VAL_ 2365443105 HighBeamSwt 3 "Not available(do not change)" 2 "Error" 1 "High Beam selected" 0 "Low Beam selected";
VAL_ 2365443105 OvertakinglampSwt 3 "Not available(do not change)" 2 "Error" 1 "On" 0 "Off";
VAL_ 2566769953 FrontOperatorWiperSwt 15 "Not available(do not change)" 14 "Reserved" 13 "Reserved" 12 "Reserved" 11 "Reserved" 10 "Reserved" 9 "Reserved" 8 "Reserved" 7 "Auto" 6 "Mist" 5 "Reserved" 4 "Reserved" 3 "High" 2 "Reserved" 1 "Low" 0 "OFF";
VAL_ 2566769953 WiprSensitivitySwt 7 "预留" 6 "预留" 5 "预留" 4 "间歇/灵敏度4" 3 "间歇/灵敏度3" 2 "间歇/灵敏度2" 1 "间歇/灵敏度1" 0 "间歇/灵敏度0";
VAL_ 2566769953 FrontOperatorWasherSwt 7 "Not available(do not change)" 6 "Reserved" 5 "Reserved" 4 "Reserved" 3 "Reserved" 2 "Reserved" 1 "ON" 0 "OFF";
VAL_ 2566759916 LockStatusofDoor_L 3 "Not available" 2 "error" 1 "locked" 0 "unlocked";
VAL_ 2566759916 OpenStatusofDoor_L 3 "Not available" 2 "error" 1 "door opened" 0 "door closed";
VAL_ 2566759916 EnableStatusofDoor_L 3 "not available" 2 "error" 1 "door enabled" 0 "door disabled";
VAL_ 2566759916 LeftDoorFltWarn 3 "预留" 2 "潜伏故障；" 1 "单点故障；" 0 "正常；";
VAL_ 2566759917 LockStatusofDoor_R 3 "Not available" 2 "error" 1 "locked" 0 "unlocked";
VAL_ 2566759917 OpenStatusofDoor_R 3 "Not available" 2 "error" 1 "door opened" 0 "door closed";
VAL_ 2566759917 EnableStatusofDoor_R 3 "not available" 2 "error" 1 "door enabled" 0 "door disabled";
VAL_ 2566759917 RightDoorFltWarn 3 "预留" 2 "潜伏故障；" 1 "单点故障；" 0 "正常；";
VAL_ 2566759780 LockStatusofDoor_FD 3 "Not available" 2 "error" 1 "locked" 0 "unlocked";
VAL_ 2566759780 OpenStatusofDoor_FD 3 "Not available" 2 "error" 1 "door opened" 0 "door closed";
VAL_ 2566759780 EnableStatusofDoor_FD 3 "not available" 2 "error" 1 "door enabled" 0 "door disabled";
VAL_ 2566759780 LockStatusofDoor_FP 3 "Not available" 2 "error" 1 "locked" 0 "unlocked";
VAL_ 2566759780 OpenStatusofDoor_FP 3 "Not available" 2 "error" 1 "door opened" 0 "door closed";
VAL_ 2566759780 EnableStatusofDoor_FP 3 "not available" 2 "error" 1 "door enabled" 0 "door disabled";
VAL_ 2566759780 LockStatusofDoor_RL 3 "Not available" 2 "error" 1 "locked" 0 "unlocked";
VAL_ 2566759780 OpenStatusofDoor_RL 3 "Not available" 2 "error" 1 "door opened" 0 "door closed";
VAL_ 2566759780 EnableStatusofDoor_RL 3 "not available" 2 "error" 1 "door enabled" 0 "door disabled";
VAL_ 2566759780 LockStatusofDoor_RR 3 "Not available" 2 "error" 1 "locked" 0 "unlocked";
VAL_ 2566759780 OpenStatusofDoor_RR 3 "Not available" 2 "error" 1 "door opened" 0 "door closed";
VAL_ 2566759780 EnableStatusofDoor_RR 3 "not available" 2 "error" 1 "door enabled" 0 "door disabled";
VAL_ 2566874468 RearviewHeatSts 3 "NotAvailable" 2 "预留" 1 "加热" 0 "未加热";
VAL_ 2566874468 RearviewHeatRelayFlt 3 "NotAvailable" 2 "短路故障" 1 "开路故障" 0 "无故障";
VAL_ 2566874468 BacklightAdjustSts 15 "Reserved" 14 "Reserved" 13 "Reserved" 12 "Reserved" 11 "Reserved" 10 "0~10档（0%~100%）" 9 "0~10档（0%~100%）" 8 "0~10档（0%~100%）" 7 "0~10档（0%~100%）" 6 "0~10档（0%~100%）" 5 "0~10档（0%~100%）" 4 "0~10档（0%~100%）" 3 "0~10档（0%~100%）" 2 "0~10档（0%~100%）" 1 "0~10档（0%~100%）" 0 "0~10档（0%~100%）";
VAL_ 2566874468 UnlockTypeSetFb 1 "Unlock ~0xFF Door；" 0 "Unlock Driver Door；";
VAL_ 2566874468 PwroffAutoUnlockSetFb 1 "ON；" 0 "OFF；";
VAL_ 2566874468 SpdLockSetFb 3 "预留；" 2 "上锁车速8km/h；" 1 "上锁车速15km/h；" 0 "关闭；";
VAL_ 2566874468 ExternalKeySts 3 "预留" 2 "副驾驶侧低频有效区域内有合法钥匙；" 1 "驾驶侧低频有效区域内有合法钥匙；" 0 "车外低频有效区域内无合法钥匙；";
VAL_ 2566874468 LockPromptSetSts 1 "Lamp Activate；" 0 "Lamp And Siren Activate；";
VAL_ 2566874468 SearchingCarPromptSetSts 1 "Lamp Activate；" 0 "Lamp And Siren Activate；";
VAL_ 2566874468 KeyNotDetectedWarn 1 "warning" 0 "not warning";
VAL_ 2566874468 LowBatteryWarn 1 "warning" 0 "not warning";
VAL_ 2566874468 KeyPutAntennaWarn 1 "warning" 0 "not warning";
VAL_ 2566874468 PEPSFaultWarn 1 "warning" 0 "not warning";
VAL_ 2566874468 KeyInCarOpenWhenExitWarn 1 "warning" 0 "not warning";
VAL_ 2566874468 PowerSwt_220V 3 "Not available" 2 "error" 1 "ON" 0 "Off";
VAL_ 2566874468 StartStopButtonSts 1 "Valid(ON)" 0 "Invalid(OFF)";
VAL_ 2566874468 EmgyShutdownReq 1 "Valid" 0 "Invalid";
VAL_ 2566874468 KeySearchLFReq 1 "请求查找钥匙" 0 "无请求查找钥匙";
VAL_ 2566874468 LFAntennaFlt 2 "开路故障；" 1 "短路故障；" 0 "正常状态；";
VAL_ 2566874468 StartConditionMet 1 "满足" 0 "不满足";
VAL_ 2566874468 KeyAuthenticationSts 3 "预留" 2 "防盗校验成功" 1 "防盗校验失败" 0 "默认值";
VAL_ 2566874468 KeyNumber 7 "Reserved" 6 "Reserved" 5 "Reserved" 4 "key 4（Reserved）" 3 "key 3（Reserved）" 2 "key 2" 1 "key 1" 0 "no key";
VAL_ 2566874468 KeyPosition 4 "out car（除PE区）" 3 "PE（副驾侧）" 2 "PE（主驾侧）" 1 "PS" 0 "Invalid";
VAL_ 2566874468 ExtrMirrSelectSts 3 "invalid" 2 "Right" 1 "Left" 0 "No request";
VAL_ 2566874468 AutoLampReq 3 "NotAvailable" 2 "故障" 1 "On" 0 "Off";
VAL_ 2566874724 ElectricHornRelaySts 3 "NotAvailable" 2 "故障" 1 "On" 0 "Off";
VAL_ 2566874724 AirHornRelaySts 3 "NotAvailable" 2 "故障" 1 "On" 0 "Off";
VAL_ 2566874724 HornSwt 1 "Press" 0 "No Press";
VAL_ 2566874724 CabAntitheftSts 7 "Reserved" 6 "Reserved" 5 "Reserved" 4 "Reserved" 3 "Alarm Trigger" 2 "Partial Armed（预留）" 1 "full armed" 0 "disarm";
VAL_ 2566874724 LockElectricHornReq 3 "NotAvailable" 2 "预留" 1 "请求" 0 "无请求";
VAL_ 2566874724 SearchingCarElectricHorReq 3 "NotAvailable" 2 "预留" 1 "请求" 0 "无请求";
VAL_ 2566874724 WiperParkSwt 3 "不可用" 2 "Error" 1 "非停止位状态" 0 "停止位状态";
VAL_ 2566874724 WiperSts 3 "无效" 2 "高速继电器" 1 "低速继电器" 0 "NOT REQUEST";
VAL_ 2566874724 WasherSts 3 "不可用" 2 "Error" 1 "ON" 0 "OFF";
VAL_ 2566874724 WiperMotorFlt 1 "有雨刮电机相关故障" 0 "无雨刮电机相关故障";
VAL_ 2566874724 WasherMotorFlt 1 "有喷淋电机相关故障" 0 "无喷淋电机相关故障";
VAL_ 2566874724 HazardSwitch 3 "不可用" 2 "Error" 1 "ON" 0 "OFF";
VAL_ 2566874724 TurnLightSts_LM 1 "Lamp On" 0 "Lamp Off";
VAL_ 2566874724 TurnLightSts_RM 1 "Lamp On" 0 "Lamp Off";
VAL_ 2566874724 TurnLightFlt_LM 3 "Underloading" 2 "Breaking" 1 "Short out" 0 "Normal";
VAL_ 2566874724 TurnLightFlt_RM 3 "Underloading" 2 "Breaking" 1 "Short out" 0 "Normal";
VAL_ 2566874724 AutoLampSwt 3 "不可用" 2 "Error" 1 "ON" 0 "OFF";
VAL_ 2566874724 PsnLampSwt 1 "ON" 0 "OFF";
VAL_ 2566874724 LowBeamSwt 3 "不可用" 2 "Error" 1 "ON" 0 "OFF";
VAL_ 2566874724 LeftLowBeamSts 1 "Lamp On" 0 "Lamp Off";
VAL_ 2566874724 LeftLowBeamFlt 3 "Underloading" 2 "Breaking" 1 "Short out" 0 "Normal";
VAL_ 2566874724 RightLowBeamSts 1 "Lamp On" 0 "Lamp Off";
VAL_ 2566874724 RightLowBeamFlt 3 "Underloading" 2 "Breaking" 1 "Short out" 0 "Normal";
VAL_ 2566874724 HighBeamSts 1 "Lamp On" 0 "Lamp Off";
VAL_ 2566874724 HighBeamFlt 3 "Underloading" 2 "Breaking" 1 "Short out" 0 "Normal";
VAL_ 2566874724 PositionLightSts_L 1 "Lamp On" 0 "Lamp Off";
VAL_ 2566874724 PositionLightFlt_L 3 "Underloading" 2 "Breaking" 1 "Short out" 0 "Normal";
VAL_ 2566874724 PositionLightSts_R 1 "Lamp On" 0 "Lamp Off";
VAL_ 2566874724 PositionLightFlt_R 3 "Underloading" 2 "Breaking" 1 "Short out" 0 "Normal";
VAL_ 2566874724 RearFogLightSwt 3 "不可用" 2 "Error" 1 "Press" 0 "No Press";
VAL_ 2566874724 FrontFogLightSwt 3 "不可用" 2 "Error" 1 "Press" 0 "No Press";
VAL_ 2566874724 Electric_AirHornSetSts 1 "AirHorn" 0 "ElectricHorn";
VAL_ 2566874724 ElectricHornReq 1 "Request" 0 "Not Request";
VAL_ 2566874724 AirHornReq 1 "Request" 0 "Not Request";
VAL_ 2566874724 FrontFogLightSts_L 1 "Lamp On" 0 "Lamp Off";
VAL_ 2566874724 FrontFogLightFltMode_L 3 "Underloading" 2 "Breaking" 1 "Short out" 0 "Normal";
VAL_ 2566874724 FrontFogLightSts_R 1 "Lamp On" 0 "Lamp Off";
VAL_ 2566874724 FrontFogLightFltMode_R 3 "Underloading" 2 "Breaking" 1 "Short out" 0 "Normal";
VAL_ 2566874724 EgySavingPwrSplySts 1 "On" 0 "Off";
VAL_ 2566875236 LockSource_MasterLock 3 "无效" 2 "CentralUnlockReq；" 1 "Centr~0xFFockReq；" 0 "No Action；";
VAL_ 2566875236 LockSource_SleeperLock 3 "无效" 2 "SleeplUnlockReq；" 1 "SleepLockReq；" 0 "No Action；";
VAL_ 2566875236 LockSource_RkeLock 15 "Signal Invalid" 14 "Reserved" 13 "Reserved" 12 "Reserved" 11 "Reserved" 10 "Reserved" 9 "Reserved" 8 "Reserved" 7 "Reserved" 6 "Lamp Inspection" 5 "Searching Car" 4 "Auto Window Down" 3 "Auto Window Up" 2 "Lock" 1 "Unlock" 0 "Initial";
VAL_ 2566875236 LockSource_RemoteLock 5 "Reserved；" 4 "RemoteReqLampInspection；" 3 "RemoteReqSearching Car；" 2 "RemotelockReq；" 1 "RemoteUnlockReq；" 0 "No Action；";
VAL_ 2566875236 LockSource_AutoReLock 1 "触发自动闭锁回防请求闭锁；" 0 "未激活回防请求闭锁；";
VAL_ 2566875236 LockSource_PkeLock 3 "PKE_UnlockDriver；" 2 "PKE_LockReq；" 1 "PKE_UnlockReq；" 0 "No Action；";
VAL_ 2566875236 LockSource_CrashLock 1 "CrashReqUnlock；" 0 "No Action；";
VAL_ 2566875236 LockSource_DKMLock 5 "Reserved；" 4 "DKM_ReqLamp Inspection（灯光巡检识别码）；" 3 "DKM_ReqSearching Car（寻车识别码）；" 2 "DKM_ReqLock（闭锁识别码）；" 1 "DKM_ReqUnlock（解锁识别码）；" 0 "No Action；";
VAL_ 2566875236 LockSource_Insd_Outd 5 "Reserved；" 4 "车辆外部闭锁命令" 3 "车辆外部解锁命令" 2 "车辆内部闭锁命令" 1 "车辆内部解锁命令" 0 "No Action；";
VAL_ 2566875236 Lock_Unlock_SucessFb 2 "成功闭锁；" 1 "成功解锁；" 0 "无请求；";
VAL_ 2566875236 PlayPrevnSts_LPKE_Unlock 1 "主驾解锁进入防玩模式" 0 "主驾解锁未进入防玩模式";
VAL_ 2566875236 PlayPrevnSts_LPKE_Lock 1 "主驾闭锁进入防玩模式" 0 "主驾闭锁未进入防玩模式";
VAL_ 2566875236 PlayPrevnSts_RPKE_Unlock 1 "副驾解锁进入防玩模式" 0 "副驾解锁未进入防玩模式";
VAL_ 2566875236 PlayPrevnSts_RPKE_Lock 1 "副驾闭锁进入防玩模式" 0 "副驾闭锁未进入防玩模式";
VAL_ 2566875236 CentralLockSw 3 "Not Used；" 2 "Unlock；" 1 "Lock；" 0 "Off；";
VAL_ 2566875236 AutoUnlockReq 1 "AutoUnlockReqUnlock；" 0 "No Action；";
VAL_ 2566875236 SpeedReqLock 1 "ReqLock；" 0 "Not Request；";
VAL_ 2566875236 LockUnlockReq_L 3 "not used；" 2 "unlock；" 1 "lock；" 0 "off；";
VAL_ 2566875236 LockUnlockReq_R 3 "not used；" 2 "unlock；" 1 "lock；" 0 "off；";
VAL_ 2566875236 LockOverheatProtection_L 1 "主驾门锁电机过热；" 0 "主驾门锁电机正常；";
VAL_ 2566875236 LockOverheatProtection_R 1 "副驾门锁电机过热；" 0 "副驾门锁电机正常；";
VAL_ 2566875236 PlayPrevnSts_LPKE 3 "reserve" 2 "Error" 1 "主驾进入防玩模式" 0 "主驾未进入防玩模式";
VAL_ 2566875236 PlayPrevnSts_RPKE 3 "reserve" 2 "Error" 1 "副驾进入防玩模式" 0 "副驾未进入防玩模式";
VAL_ 2566875236 RearFogLightSts 1 "Lamp On" 0 "Lamp Off";
VAL_ 2566875236 RearFogLightFltMode 3 "Underloading" 2 "Breaking" 1 "Short out" 0 "Normal";
VAL_ 2566875236 RearFogLightSts_T 1 "Lamp On" 0 "Lamp Off";
VAL_ 2566875236 RearFogLightFltMode_T 3 "Underloading" 2 "Breaking" 1 "Short out" 0 "Normal";
VAL_ 2566875236 ExtrMirrHozlAdjMotorSts_R 4 "reserve" 2 "Block" 1 "Error" 0 "No Error";
VAL_ 2566875236 ExtrMirrVertAdjMotorSts_R 5 "reserve" 2 "Block" 1 "Error" 0 "No Error";
VAL_ 2566875236 ExtrMirrHozlAdjMotorSts_L 6 "reserve" 2 "Block" 1 "Error" 0 "No Error";
VAL_ 2566875236 ExtrMirrVertAdjMotorSts_L 7 "reserve" 2 "Block" 1 "Error" 0 "No Error";
VAL_ 2566875236 MainBrkLightSts 2 "Lamp Flash" 1 "Lamp On" 0 "Lamp Off";
VAL_ 2566875236 TrailerBrkLightSts 2 "Lamp Flash" 1 "Lamp On" 0 "Lamp Off";
VAL_ 2566875236 MainBrkLightFltMode 3 "Underloading" 2 "Breaking" 1 "Short out" 0 "Normal";
VAL_ 2566875236 TrailerBrkLightFltMode 3 "Underloading" 2 "Breaking" 1 "Short out" 0 "Normal";
VAL_ 2566893412 LowBeamFltWarn_VIUB 3 "预留" 2 "潜伏故障；" 1 "单点故障；" 0 "正常；";
VAL_ 2566893412 HighBeamFltWarn_VIUB 3 "预留" 2 "潜伏故障；" 1 "单点故障；" 0 "正常；";
VAL_ 2566893412 FrontOperatorWiperFltWarn_VIUB 3 "预留" 2 "潜伏故障；" 1 "单点故障；" 0 "正常；";
VAL_ 2566893412 AntiPinchFlt_Drvr_VIUB 3 "预留" 2 "潜伏故障；" 1 "单点故障；" 0 "正常；";
VAL_ 2566893412 AntiPinchFlt_Pass_VIUB 3 "预留" 2 "潜伏故障；" 1 "单点故障；" 0 "正常；";
VAL_ 2566893412 WinCtrlFlt_Drvr_VIUB 3 "预留" 2 "潜伏故障；" 1 "单点故障；" 0 "正常；";
VAL_ 2566893412 WinCtrlFlt_Pass_VIUB 3 "预留" 2 "潜伏故障；" 1 "单点故障；" 0 "正常；";
VAL_ 2566893412 VIUB_ACFrontDefrostSysSts 3 "Reserved" 2 "PotentialFailures" 1 "Fault" 0 "Normal";
VAL_ 2566893412 MainBrkLightFltWarn_VIUC 3 "预留" 2 "潜伏故障；" 1 "单点故障；" 0 "正常；";
VAL_ 2566893412 TrailerBrkLightFltWarn_VIUC 3 "预留" 2 "潜伏故障；" 1 "单点故障；" 0 "正常；";
VAL_ 2566875492 WinSwt_DrvrsideD 7 "预留" 6 "预留" 5 "故障" 4 "Driver side driver window auto down" 3 "Driver side driver window auto up" 2 "Driver side driver window manual down" 1 "Driver side driver window manual up" 0 "no request";
VAL_ 2566875492 WinSwt_DrvrsideP 7 "预留" 6 "预留" 5 "故障" 4 "Driver side passenger window auto down" 3 "Driver side passenger window auto up" 2 "Driver side passenger window manual down" 1 "Driver side passenger window manual up" 0 "no request";
VAL_ 2566875492 WinSwt_Pass 7 "预留" 6 "预留" 5 "故障" 4 "Passenger side passenger window auto down" 3 "Passenger side passenger window auto up" 2 "Passenger side passenger window manual down" 1 "Passenger side passenger window manual up" 0 "no request";
VAL_ 2566875492 WinSts_Drvr 3 "无效" 2 "Driver Window down" 1 "Driver Window up" 0 "Driver Window Not Moving";
VAL_ 2566875492 WinSts_Pass 3 "无效" 2 "Passenger Window down" 1 "Passenger Window up" 0 "Passenger Window Not Moving";
VAL_ 2566875492 RFReceiver 15 "Signal Invalid" 14 "Reserved" 13 "Reserved" 12 "Reserved" 11 "Reserved" 10 "Reserved" 9 "Reserved" 8 "Reserved" 7 "Reserved" 6 "Lamp Inspection" 5 "Searching Car" 4 "Auto Window Down" 3 "Auto Window Up" 2 "Lock" 1 "Unlock" 0 "Initial";
VAL_ 2566875492 PEUnlockSwt_L 3 "Signal Invalid" 2 "Reserved" 1 "press" 0 "No press";
VAL_ 2566875492 PELockSwt_L 3 "Signal Invalid" 2 "Reserved" 1 "press" 0 "No press";
VAL_ 2566875492 PEUnlockSwt_R 3 "Signal Invalid" 2 "Reserved" 1 "press" 0 "No press";
VAL_ 2566875492 PELockSwt_R 3 "Signal Invalid" 2 "Reserved" 1 "press" 0 "No press";
VAL_ 2566875492 PESwt_L 3 "Signal Invalid" 2 "Signal Invalid" 1 "Press；" 0 "NO Press；";
VAL_ 2566875492 PESwt_R 3 "Signal Invalid" 2 "Signal Invalid" 1 "Press；" 0 "NO Press；";
VAL_ 2566875492 ExtrMirrDirAdjOutput_L 4 "TurnRight Output;" 3 "TurnLeft Output;" 2 "TurnDown Output;" 1 "TurnUP Output;" 0 "No Output";
VAL_ 2566875492 ExtrMirrDirAdjOutput_R 4 "TurnRight Output;" 3 "TurnLeft Output;" 2 "TurnDown Output;" 1 "TurnUP Output;" 0 "No Output";
VAL_ 2566875748 WinMotorStallStopReq_L 3 "预留" 2 "错误值" 1 "Request" 0 "No Request";
VAL_ 2566875748 WinMotorStallStopReq_R 3 "预留" 2 "错误值" 1 "Request" 0 "No Request";
VAL_ 2566875748 AntiPinchRollbackReq_L 3 "预留" 2 "错误值" 1 "Request" 0 "No Request";
VAL_ 2566875748 AntiPinchRollbackReq_R 3 "预留" 2 "错误值" 1 "Request" 0 "No Request";
VAL_ 2566874980 SeatVibrationSts 7 "reserved" 6 "reserved" 5 "reserved" 4 "drive ~0xFF motors continuously vibrate" 3 "drive ~0xFF motors vibrate at 0.25s on 0.25s off as a period" 2 "drive ~0xFF motors vibrate at 0.5s on 0.5s off as a period" 1 "drive ~0xFF motors vibrate at 1s on 1s off as a period" 0 "no action";
VAL_ 2566874980 CentralLockFailFlg 1 "TRUE" 0 "FALSE";
VAL_ 2566874980 RKELockFailFlg 1 "TRUE" 0 "FALSE";
VAL_ 2566874980 PKELockFailFlg 1 "TRUE" 0 "FALSE";
VAL_ 2566874980 DKMLockFailFlg 1 "TRUE" 0 "FALSE";
VAL_ 2365522788 CertificationSts_VIU 2 "Verification is running" 1 "Send MAC" 0 "Initial";
VAL_ 2566873629 SGM_S_Unlock_Swt 3 "Error" 2 "Reserved" 1 "press" 0 "Not press";
VAL_ 2566873629 SGM_S_Lock_Swt 3 "Error" 2 "Reserved" 1 "press" 0 "Not press";
VAL_ 2566873629 SGM_S_WLM_FL_Swt 7 "预留" 6 "预留" 5 "故障" 4 "Driver side driver window auto down" 3 "Driver side driver window auto up" 2 "Driver side driver window manual down" 1 "Driver side driver window manual up" 0 "No request";
VAL_ 2566873629 SGM_S_WLM_FR_Swt 7 "预留" 6 "预留" 5 "故障" 4 "Driver side driver window auto down" 3 "Driver side driver window auto up" 2 "Driver side driver window manual down" 1 "Driver side driver window manual up" 0 "No request";
VAL_ 2566873629 SGM_S_VolumePlus_Swt 3 "Error" 2 "longpress" 1 "shortpress" 0 "Not press";
VAL_ 2566873629 SGM_S_VolumeMinus_Swt 3 "Error" 2 "longpress" 1 "shortpress" 0 "Not press";
VAL_ 2566873629 SGM_S_ACOnOrOff_Swt 3 "Error" 2 "Reserved" 1 "press" 0 "Not press";
VAL_ 2566873629 SGM_S_BlowerLvlPlus_Swt 3 "Error" 2 "Reserved" 1 "press" 0 "Not press";
VAL_ 2566873629 SGM_S_BlowerLvlMinus_Swt 3 "Error" 2 "Reserved" 1 "press" 0 "Not press";
VAL_ 2566873629 SGM_S_ACTempPlus_Swt 3 "Error" 2 "Reserved" 1 "press" 0 "Not press";
VAL_ 2566873629 SGM_S_ACTempMinus_Swt 3 "Error" 2 "Reserved" 1 "press" 0 "Not press";
VAL_ 2566873629 SGM_S_ACTimingRun_Swt 3 "Error" 2 "Reserved" 1 "press" 0 "Not press";
VAL_ 2566873629 SGM_S_CMSStart_Swt 3 "Error" 2 "Reserved" 1 "press" 0 "Not press";
VAL_ 2566873629 SGM_S_F_LINError 1 "Error" 0 "Normal";
VAL_ 2365537816 SWS_Mode_Swt 3 "Error" 2 "Reserved" 1 "press" 0 "Not press";
VAL_ 2365537816 SWS_ReturnOrConfirm_Swt 3 "Error" 2 "Reserved" 1 "press" 0 "Not press";
VAL_ 2365537816 SWS_DirectionUp_Swt 3 "Error" 2 "Reserved" 1 "press" 0 "Not press";
VAL_ 2365537816 SWS_DirectionDown_Swt 3 "Error" 2 "Reserved" 1 "press" 0 "Not press";
VAL_ 2365537816 SWS_DirectionLeft_Swt 3 "Error" 2 "Reserved" 1 "press" 0 "Not press";
VAL_ 2365537816 SWS_DirectionRight_Swt 3 "Error" 2 "Reserved" 1 "press" 0 "Not press";
VAL_ 2365537816 SWS_VROrHangUp_Swt 3 "Error" 2 "Reserved" 1 "press" 0 "Not press";
VAL_ 2365537816 SWS_MuteOrHangDown_Swt 3 "Error" 2 "Reserved" 1 "press" 0 "Not press";
VAL_ 2365537816 SWS_Userde_Swt 3 "Error" 2 "Reserved" 1 "press" 0 "Not press";
VAL_ 2365537816 SWS_ADAS_Swt 3 "Error" 2 "Reserved" 1 "press" 0 "Not press";
VAL_ 2365537816 SWS_SpeedUp_Set 3 "Error" 2 "Error" 1 "press" 0 "Not press";
VAL_ 2365537816 SWS_SpeedDown_Set 3 "Error" 2 "Error" 1 "press" 0 "Not press";
VAL_ 2365537816 SWS_TimeGapInc_Set 3 "Error" 2 "Reserved" 1 "press" 0 "Not press";
VAL_ 2365537816 SWS_TimeGapDec_Set 3 "Error" 2 "Reserved" 1 "press" 0 "Not press";
VAL_ 2365537816 SWS_LKA_Swt 3 "Error" 2 "Reserved" 1 "press" 0 "Not press";
VAL_ 2365537816 SWS_Heating_Swt 3 "Error" 2 "Reserved" 1 "press" 0 "Not press";
VAL_ 2566873374 SGM_IP_HornType_Swt 3 "Error" 2 "Reserved" 1 "press" 0 "Not press";
VAL_ 2566873374 SGM_IP_RearLight_Swt 3 "Error" 2 "Reserved" 1 "press" 0 "Not press";
VAL_ 2566873374 SGM_IP_ACOff_Swt 3 "Error" 2 "Reserved" 1 "press" 0 "Not press";
VAL_ 2566873374 SGM_IP_BlowerLvlPlus_Swt 3 "Error" 2 "Reserved" 1 "press" 0 "Not press";
VAL_ 2566873374 SGM_IP_BlowerLvlMinus_Swt 3 "Error" 2 "Reserved" 1 "press" 0 "Not press";
VAL_ 2566873374 SGM_IP_ACTempPlus_Swt 3 "Error" 2 "Reserved" 1 "press" 0 "Not press";
VAL_ 2566873374 SGM_IP_ACTempMinus_Swt 3 "Error" 2 "Reserved" 1 "press" 0 "Not press";
VAL_ 2566873374 SGM_IP_ACFrontDefrost_Swt 3 "Error" 2 "Reserved" 1 "press" 0 "Not press";
VAL_ 2566873374 SGM_IP_F_LINError 1 "Error" 0 "Normal";
VAL_ 2364539904 EngTorqueMode_ 15 "Not available" 14 "蠕行或非D档" 12 "Torque limiter activation" 11 "Remote accelerator" 10 "Braking system" 9 "High speed governor" 8 "Torque limiting" 7 "ABS control" 6 "Transmission control" 5 "ASR control" 4 "Road speed governor" 3 "PTO governor" 2 "Cruise control" 1 "Accelerator pedal/operator selec" 0 "Low idle governor/no request (de";
VAL_ 2364539904 ActlEngPrcntTrqueHighResolution_ 15 "NotAvailable" 14 "NotAvailable" 13 "NotAvailable" 12 "NotAvailable" 11 "NotAvailable" 10 "NotAvailable" 9 "NotAvailable" 8 "NotAvailable" 7 "0.875" 6 "0.750" 5 "0.625" 4 "0.500" 3 "0.375" 2 "0.250" 1 "0.125" 0 "0";
VAL_ 2364539648 AccelPedal1LowIdleSwitch_ 3 "NotAvailable" 2 "Error" 1 "AccelPedal1InLowIdleCondition" 0 "AcclPedal1NotInLowIdleCondition";
VAL_ 2364539648 AccelPedalKickdownSwitch 3 "NotAvailable" 2 "Error" 1 "KickdownActive" 0 "KickdownPassive";
VAL_ 2348833319 Engine_override_control_mode 3 "Speed/torque limit control (Only Trq-Limit)" 2 "torque control" 1 "Speed control (Not supported by ZF ECU)" 0 "Override disabled";
VAL_ 2348833319 Override_control_mode_priority 3 "Low" 2 "Midium" 1 "High" 0 "Highest";
VAL_ 2348833319 Vehicle_St_CrpDrv 1 "已开启" 0 "未开启";
VAL_ 2348876583 GearShiftInhibitReq 3 "Take no action (leave function as is)" 2 "Reserved" 1 "Gear shifts are inhibited (enable function)" 0 "Gear shifts are ~0xFFowed (disable function)";
VAL_ 2348876583 Disengage_Driveline_Request 3 "Take no action" 2 "Reserved" 1 "Disengage driveline" 0 "~0xFFow driveline engagement";
VAL_ 2348876583 Disengage_Differential_Lock_Request_Rear_Axle_1 3 "Take no action" 2 "Reserved" 1 "Disengage differential lock" 0 "Engage differential lock";
VAL_ 2348876583 Disengage_Differential_Lock_Request_Rear_Axle_2 3 "Take no action" 2 "Reserved" 1 "Disengage differential lock" 0 "Engage differential lock";
VAL_ 2365522215 EV_System_Release 3 "not available" 2 "Error" 1 "Valid driver system activation" 0 "Init";
VAL_ 2365522215 Electrical_System_Ready 3 "not available" 2 "Error" 1 "System ready" 0 "Init / not ready";
VAL_ 2365522215 External_Drive_Mode_Request 2 "Eco Mode (high limitation)" 1 "Normal Mode (low limitation)" 0 "Power Mode (no llimitation)";
VAL_ 2365522215 External_Workshop_Mode_Request 3 "not available" 2 "Error" 1 "Workshop Mode Requested" 0 "No Request of Workshop Mode";
VAL_ 2365522215 External_Discharge_Request 3 "Not available" 2 "Error" 1 "External Discharge Requested" 0 "External Discharge NOT Requrested";
VAL_ 2365530663 Requested_Gear 255 "Not Vailable" 223 "R挡" 222 "N挡" 252 "D挡";
